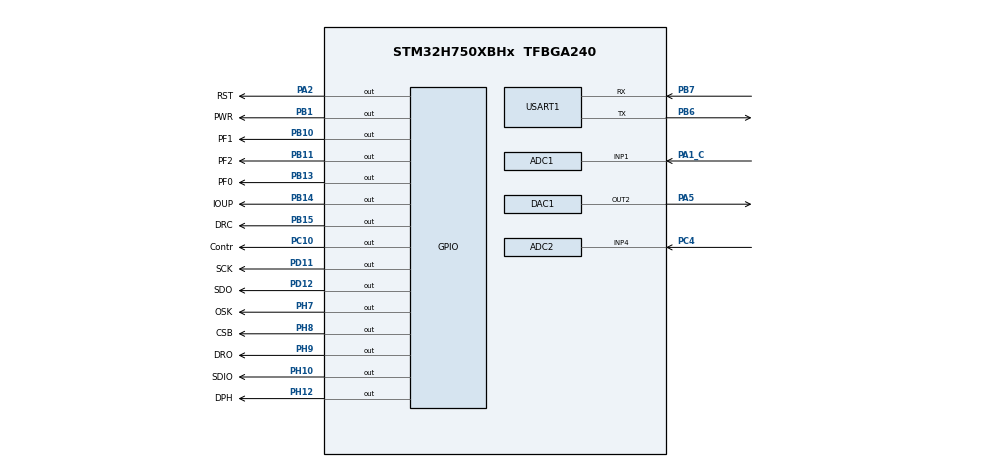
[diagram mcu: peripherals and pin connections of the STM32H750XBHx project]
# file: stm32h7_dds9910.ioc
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ADC1.Channel-3\#ChannelRegularConversion=ADC_CHANNEL_1
ADC1.ContinuousConvMode=DISABLE
ADC1.ConversionDataManagement=ADC_CONVERSIONDATA_DMA_CIRCULAR
ADC1.EOCSelection=ADC_EOC_SINGLE_CONV
ADC1.ExternalTrigConv=ADC_EXTERNALTRIG_T4_TRGO
ADC1.Mode=ADC_MODE_INDEPENDENT
ADC1.NbrOfConversionFlag=1
ADC1.OffsetNumber-3\#ChannelRegularConversion=ADC_OFFSET_NONE
ADC1.OffsetSignedSaturation-3\#ChannelRegularConversion=DISABLE
ADC1.Overrun=ADC_OVR_DATA_OVERWRITTEN
ADC1.Rank-3\#ChannelRegularConversion=1
ADC1.Resolution=ADC_RESOLUTION_12B
ADC1.SamplingTime-3\#ChannelRegularConversion=ADC_SAMPLETIME_1CYCLE_5
ADC1.master=1
ADC2.Channel-3\#ChannelRegularConversion=ADC_CHANNEL_4
ADC2.ConversionDataManagement=ADC_CONVERSIONDATA_DMA_CIRCULAR
ADC2.ExternalTrigConv=ADC_EXTERNALTRIG_T4_TRGO
ADC2.NbrOfConversionFlag=1
ADC2.OffsetNumber-3\#ChannelRegularConversion=ADC_OFFSET_NONE
ADC2.OffsetSignedSaturation-3\#ChannelRegularConversion=DISABLE
ADC2.Overrun=ADC_OVR_DATA_OVERWRITTEN
ADC2.Rank-3\#ChannelRegularConversion=1
ADC2.Resolution=ADC_RESOLUTION_12B
ADC2.SamplingTime-3\#ChannelRegularConversion=ADC_SAMPLETIME_1CYCLE_5
CORTEX_M7.default_mode_Activation=1
DAC1.DAC_Channel-DAC_OUT2=DAC_CHANNEL_2
DAC1.DAC_Trigger-DAC_OUT2=DAC_TRIGGER_T6_TRGO
Dma.ADC1.0.Direction=DMA_PERIPH_TO_MEMORY
Dma.ADC1.0.EventEnable=DISABLE
Dma.ADC1.0.FIFOMode=DMA_FIFOMODE_DISABLE
Dma.ADC1.0.Instance=DMA1_Stream0
Dma.ADC1.0.MemDataAlignment=DMA_MDATAALIGN_HALFWORD
Dma.ADC1.0.MemInc=DMA_MINC_ENABLE
Dma.ADC1.0.Mode=DMA_NORMAL
Dma.ADC1.0.PeriphDataAlignment=DMA_PDATAALIGN_HALFWORD
Dma.ADC1.0.PeriphInc=DMA_PINC_DISABLE
Dma.ADC1.0.Polarity=HAL_DMAMUX_REQ_GEN_RISING
Dma.ADC1.0.Priority=DMA_PRIORITY_LOW
Dma.ADC1.0.RequestNumber=1
Dma.ADC1.0.SignalID=NONE
Dma.ADC1.0.SyncEnable=DISABLE
Dma.ADC1.0.SyncPolarity=HAL_DMAMUX_SYNC_NO_EVENT
Dma.ADC1.0.SyncRequestNumber=1
Dma.ADC1.0.SyncSignalID=NONE
Dma.ADC2.2.Direction=DMA_PERIPH_TO_MEMORY
Dma.ADC2.2.EventEnable=DISABLE
Dma.ADC2.2.FIFOMode=DMA_FIFOMODE_DISABLE
Dma.ADC2.2.Instance=DMA1_Stream2
Dma.ADC2.2.MemDataAlignment=DMA_MDATAALIGN_HALFWORD
Dma.ADC2.2.MemInc=DMA_MINC_ENABLE
Dma.ADC2.2.Mode=DMA_NORMAL
Dma.ADC2.2.PeriphDataAlignment=DMA_PDATAALIGN_HALFWORD
Dma.ADC2.2.PeriphInc=DMA_PINC_DISABLE
Dma.ADC2.2.Polarity=HAL_DMAMUX_REQ_GEN_RISING
Dma.ADC2.2.Priority=DMA_PRIORITY_LOW
Dma.ADC2.2.RequestNumber=1
Dma.ADC2.2.SignalID=NONE
Dma.ADC2.2.SyncEnable=DISABLE
Dma.ADC2.2.SyncPolarity=HAL_DMAMUX_SYNC_NO_EVENT
Dma.ADC2.2.SyncRequestNumber=1
Dma.ADC2.2.SyncSignalID=NONE
Dma.DAC1_CH2.1.Direction=DMA_MEMORY_TO_PERIPH
Dma.DAC1_CH2.1.EventEnable=DISABLE
Dma.DAC1_CH2.1.FIFOMode=DMA_FIFOMODE_DISABLE
Dma.DAC1_CH2.1.Instance=DMA1_Stream1
Dma.DAC1_CH2.1.MemDataAlignment=DMA_MDATAALIGN_HALFWORD
Dma.DAC1_CH2.1.MemInc=DMA_MINC_ENABLE
Dma.DAC1_CH2.1.Mode=DMA_CIRCULAR
Dma.DAC1_CH2.1.PeriphDataAlignment=DMA_PDATAALIGN_HALFWORD
Dma.DAC1_CH2.1.PeriphInc=DMA_PINC_DISABLE
Dma.DAC1_CH2.1.Polarity=HAL_DMAMUX_REQ_GEN_RISING
Dma.DAC1_CH2.1.Priority=DMA_PRIORITY_VERY_HIGH
Dma.DAC1_CH2.1.RequestNumber=1
Dma.DAC1_CH2.1.SignalID=NONE
Dma.DAC1_CH2.1.SyncEnable=DISABLE
Dma.DAC1_CH2.1.SyncPolarity=HAL_DMAMUX_SYNC_NO_EVENT
Dma.DAC1_CH2.1.SyncRequestNumber=1
Dma.DAC1_CH2.1.SyncSignalID=NONE
Dma.Request0=ADC1
Dma.Request1=DAC1_CH2
Dma.Request2=ADC2
Mcu.Family=STM32H7
Mcu.Name=STM32H750XBHx
Mcu.Package=TFBGA240
NVIC.ADC_IRQn=true\:1\:0\:true\:false\:true\:true\:true\:true
NVIC.DMA1_Stream0_IRQn=true\:0\:0\:false\:false\:true\:false\:true\:true
NVIC.DMA1_Stream1_IRQn=true\:0\:0\:false\:false\:true\:false\:true\:true
NVIC.DMA1_Stream2_IRQn=true\:0\:0\:false\:false\:true\:false\:true\:true
NVIC.PriorityGroup=NVIC_PRIORITYGROUP_4
NVIC.USART1_IRQn=true\:0\:0\:false\:false\:true\:true\:true\:true
PA13\ (JTMS/SWDIO).Mode=Serial_Wire
PA13\ (JTMS/SWDIO).Signal=DEBUG_JTMS-SWDIO
PA14\ (JTCK/SWCLK).Mode=Serial_Wire
PA14\ (JTCK/SWCLK).Signal=DEBUG_JTCK-SWCLK
PA1_C.Signal=ADCx_INP1
PA2.GPIO_Label=RST
PA2.GPIO_Speed=GPIO_SPEED_FREQ_VERY_HIGH
PA2.Signal=GPIO_Output
PA4.Signal=ADCx_INP18
PA5.Signal=COMP_DAC12_group
PB1.GPIO_Label=PWR
PB1.GPIO_Speed=GPIO_SPEED_FREQ_VERY_HIGH
PB1.Signal=GPIO_Output
PB10.GPIO_Label=PF1
PB10.GPIO_Speed=GPIO_SPEED_FREQ_VERY_HIGH
PB10.Signal=GPIO_Output
PB11.GPIO_Label=PF2
PB11.GPIO_Speed=GPIO_SPEED_FREQ_VERY_HIGH
PB11.Signal=GPIO_Output
PB13.GPIO_Label=PF0
PB13.GPIO_Speed=GPIO_SPEED_FREQ_VERY_HIGH
PB13.Signal=GPIO_Output
PB14.GPIO_Label=IOUP
PB14.GPIO_Speed=GPIO_SPEED_FREQ_VERY_HIGH
PB14.Signal=GPIO_Output
PB15.GPIO_Label=DRC
PB15.GPIO_Speed=GPIO_SPEED_FREQ_VERY_HIGH
PB15.Signal=GPIO_Output
PB6.Mode=Asynchronous
PB6.Signal=USART1_TX
PB7.Mode=Asynchronous
PB7.Signal=USART1_RX
PC10.GPIO_Label=Contr
PC10.Signal=GPIO_Output
PC4.Signal=ADCx_INP4
PD11.GPIO_Label=SCK
PD11.GPIO_Speed=GPIO_SPEED_FREQ_VERY_HIGH
PD11.Signal=GPIO_Output
PD12.GPIO_Label=SDO
PD12.GPIO_Speed=GPIO_SPEED_FREQ_VERY_HIGH
PD12.Signal=GPIO_Output
PH0-OSC_IN\ (PH0).Mode=HSE-External-Oscillator
PH0-OSC_IN\ (PH0).Signal=RCC_OSC_IN
PH1-OSC_OUT\ (PH1).Mode=HSE-External-Oscillator
PH1-OSC_OUT\ (PH1).Signal=RCC_OSC_OUT
PH10.GPIO_Label=SDIO
PH10.GPIO_Speed=GPIO_SPEED_FREQ_VERY_HIGH
PH10.Signal=GPIO_Output
PH12.GPIO_Label=DPH
PH12.GPIO_Speed=GPIO_SPEED_FREQ_VERY_HIGH
PH12.Signal=GPIO_Output
PH7.GPIO_Label=OSK
PH7.GPIO_Speed=GPIO_SPEED_FREQ_VERY_HIGH
PH7.Signal=GPIO_Output
PH8.GPIO_Label=CSB
PH8.GPIO_Speed=GPIO_SPEED_FREQ_VERY_HIGH
PH8.Signal=GPIO_Output
PH9.GPIO_Label=DRO
PH9.GPIO_Speed=GPIO_SPEED_FREQ_VERY_HIGH
PH9.Signal=GPIO_Output
ProjectManager.HeapSize=0x2000
ProjectManager.StackSize=0x4000
ProjectManager.TargetToolchain=MDK-ARM V5.32
RCC.ADCFreq_Value=50000000
RCC.APB1Freq_Value=120000000
RCC.APB2Freq_Value=120000000
RCC.APB3Freq_Value=120000000
RCC.APB4Freq_Value=120000000
RCC.CortexFreq_Value=480000000
RCC.D1PPRE=RCC_APB3_DIV2
RCC.D2PPRE1=RCC_APB1_DIV2
RCC.D2PPRE2=RCC_APB2_DIV2
RCC.D3PPRE=RCC_APB4_DIV2
RCC.DIVM1=5
RCC.DIVM2=25
RCC.DIVN1=192
RCC.DIVN2=500
RCC.DIVP2=10
RCC.HCLKFreq_Value=240000000
RCC.HPRE=RCC_HCLK_DIV2
RCC.PLL2FRACN=0
RCC.PLL3FRACN=0
RCC.PLLFRACN=0
RCC.PLLSourceVirtual=RCC_PLLSOURCE_HSE
RCC.SYSCLKFreq_VALUE=480000000
RCC.SYSCLKSource=RCC_SYSCLKSOURCE_PLLCLK
RCC.USBFreq_Value=480000000
SH.ADCx_INP1.0=ADC1_INP1,IN1-Single-Ended
SH.ADCx_INP18.0=ADC1_INP18
SH.ADCx_INP4.0=ADC2_INP4,IN4-Single-Ended
SH.COMP_DAC12_group.0=DAC1_OUT2,DAC_OUT2
TIM4.AutoReloadPreload=TIM_AUTORELOAD_PRELOAD_ENABLE
TIM4.Period=240-1
TIM4.Prescaler=0
TIM4.TIM_MasterOutputTrigger=TIM_TRGO_UPDATE
TIM4.TIM_MasterSlaveMode=TIM_MASTERSLAVEMODE_DISABLE
TIM6.AutoReloadPreload=TIM_AUTORELOAD_PRELOAD_ENABLE
TIM6.Period=120-1
TIM6.TIM_MasterOutputTrigger=TIM_TRGO_UPDATE
USART1.VirtualMode-Asynchronous=VM_ASYNC
VP_MEMORYMAP_VS_MEMORYMAP.Mode=CurAppReg
VP_TIM4_VS_ClockSourceINT.Mode=Internal
VP_TIM6_VS_ClockSourceINT.Mode=Enable_Timer
board=custom

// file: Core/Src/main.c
/* USER CODE BEGIN Header */
/**
  ******************************************************************************
  * @file           : main.c
  * @brief          : Main program body
  ******************************************************************************
  * @attention
  *
  * Copyright (c) 2025 STMicroelectronics.
  * All rights reserved.
  *
  * This software is licensed under terms that can be found in the LICENSE file
  * in the root directory of this software component.
  * If no LICENSE file comes with this software, it is provided AS-IS.
  *
  ******************************************************************************
  */
/* USER CODE END Header */
#include "main.h"
#include "adc.h"
#include "dac.h"
#include "dma.h"
#include "memorymap.h"
#include "tim.h"
#include "usart.h"
#include "gpio.h"

/* USER CODE BEGIN Includes */
#include "AD9910.h"
#include "tjc_usart_hmi.h"
#include <stdio.h>
#include <stdlib.h>
#include <string.h>
#include "arm_math.h"
#include "math.h"
#include "arm_const_structs.h"
/* USER CODE END Includes */

/* USER CODE BEGIN PD */
#define FRAME_LENGTH 2
#define FFT_LEN 2048

/* USER CODE END PD */

/* USER CODE BEGIN PV */
float Fre_respon[30]=
{
0.9865,
0.9488,
0.8944,
0.8316,
0.7668,
0.7045,
0.6466,
0.5942,
0.5471,
0.5051,
0.4677,
0.4343,
0.4044,
0.3776,
0.3534,
0.3316,
0.3118,
0.2937,
0.2773,
0.2622,
0.2483,
0.2355,
0.2237,
0.2128,
0.2026,
0.1932,
0.1843,
0.1761,
0.1684,
0.1612
};

/* USER CODE END PV */

void SystemClock_Config(void);
void PeriphCommonClock_Config(void);
static void MPU_Config(void);
/* USER CODE BEGIN PFP */
static float si_10000[10000] = {
0.00000000, 0.00031419, 0.00062838, 0.00094257, 0.00125676, 0.00157095, 0.00188514, 0.00219933, 0.00251351, 0.00282770, 0.00314189, 0.00345607, 0.00377025, 0.00408443, 0.00439861, 0.00471279, 0.00502697, 0.00534114, 0.00565531, 0.00596948, 0.00628365, 0.00659781, 0.00691197, 0.00722613, 0.00754029, 0.00785444, 0.00816859, 0.00848274, 0.00879689, 0.00911103, 0.00942516, 0.00973930, 0.01005342, 0.01036755, 0.01068167, 0.01099579, 0.01130990, 0.01162401, 0.01193811, 0.01225221, 0.01256630, 0.01288039, 0.01319448, 0.01350856, 0.01382263, 0.01413670, 0.01445076, 0.01476482, 0.01507887, 0.01539291, 0.01570695, 0.01602098, 0.01633501, 0.01664903, 0.01696304, 0.01727705, 0.01759105, 0.01790504, 0.01821903, 0.01853300, 0.01884698, 0.01916094, 0.01947489, 0.01978884, 0.02010278, 0.02041672, 0.02073064, 0.02104456, 0.02135847, 0.02167237, 0.02198626, 0.02230014, 0.02261401, 0.02292788, 0.02324173, 0.02355558, 0.02386942, 0.02418324, 0.02449706, 0.02481087, 0.02512467, 0.02543846, 0.02575224, 0.02606601, 0.02637976, 0.02669351, 0.02700725, 0.02732098, 0.02763469, 0.02794840, 0.02826209, 0.02857577, 0.02888944, 0.02920310, 0.02951675, 0.02983039, 0.03014402, 0.03045763, 0.03077123, 0.03108482,
0.03139840, 0.03171196, 0.03202551, 0.03233905, 0.03265258, 0.03296609, 0.03327959, 0.03359308, 0.03390655, 0.03422001, 0.03453346, 0.03484689, 0.03516031, 0.03547372, 0.03578711, 0.03610049, 0.03641385, 0.03672720, 0.03704054, 0.03735386, 0.03766716, 0.03798045, 0.03829373, 0.03860699, 0.03892023, 0.03923346, 0.03954668, 0.03985988, 0.04017306, 0.04048623, 0.04079938, 0.04111251, 0.04142563, 0.04173873, 0.04205182, 0.04236489, 0.04267794, 0.04299098, 0.04330399, 0.04361700, 0.04392998, 0.04424295, 0.04455590, 0.04486883, 0.04518174, 0.04549464, 0.04580752, 0.04612038, 0.04643322, 0.04674604, 0.04705885, 0.04737164, 0.04768440, 0.04799715, 0.04830988, 0.04862259, 0.04893529, 0.04924796, 0.04956061, 0.04987325, 0.05018586, 0.05049845, 0.05081103, 0.05112358, 0.05143612, 0.05174863, 0.05206112, 0.05237359, 0.05268605, 0.05299848, 0.05331089, 0.05362328, 0.05393565, 0.05424799, 0.05456032, 0.05487262, 0.05518490, 0.05549716, 0.05580940, 0.05612162, 0.05643381, 0.05674598, 0.05705813, 0.05737026, 0.05768236, 0.05799445, 0.05830650, 0.05861854, 0.05893055, 0.05924254, 0.05955451, 0.05986645, 0.06017837, 0.06049026, 0.06080213, 0.06111398, 0.06142580, 0.06173760, 0.06204938, 0.06236113,
0.06267285, 0.06298455, 0.06329623, 0.06360788, 0.06391950, 0.06423110, 0.06454268, 0.06485423, 0.06516575, 0.06547725, 0.06578872, 0.06610017, 0.06641159, 0.06672298, 0.06703435, 0.06734569, 0.06765700, 0.06796829, 0.06827955, 0.06859078, 0.06890199, 0.06921317, 0.06952432, 0.06983545, 0.07014655, 0.07045761, 0.07076866, 0.07107967, 0.07139066, 0.07170161, 0.07201254, 0.07232344, 0.07263432, 0.07294516, 0.07325597, 0.07356676, 0.07387752, 0.07418824, 0.07449894, 0.07480961, 0.07512025, 0.07543086, 0.07574144, 0.07605199, 0.07636251, 0.07667300, 0.07698346, 0.07729389, 0.07760429, 0.07791465, 0.07822499, 0.07853530, 0.07884557, 0.07915582, 0.07946603, 0.07977621, 0.08008636, 0.08039648, 0.08070657, 0.08101662, 0.08132664, 0.08163663, 0.08194659, 0.08225652, 0.08256641, 0.08287627, 0.08318610, 0.08349590, 0.08380566, 0.08411539, 0.08442508, 0.08473475, 0.08504438, 0.08535397, 0.08566353, 0.08597306, 0.08628256, 0.08659202, 0.08690144, 0.08721083, 0.08752019, 0.08782951, 0.08813880, 0.08844805, 0.08875727, 0.08906646, 0.08937560, 0.08968472, 0.08999379, 0.09030284, 0.09061184, 0.09092081, 0.09122975, 0.09153865, 0.09184751, 0.09215633, 0.09246512, 0.09277388, 0.09308259, 0.09339127,
0.09369992, 0.09400852, 0.09431709, 0.09462562, 0.09493412, 0.09524257, 0.09555099, 0.09585937, 0.09616772, 0.09647602, 0.09678429, 0.09709252, 0.09740071, 0.09770886, 0.09801698, 0.09832505, 0.09863309, 0.09894108, 0.09924904, 0.09955696, 0.09986484, 0.10017268, 0.10048048, 0.10078824, 0.10109597, 0.10140365, 0.10171129, 0.10201889, 0.10232645, 0.10263397, 0.10294145, 0.10324889, 0.10355629, 0.10386365, 0.10417096, 0.10447824, 0.10478547, 0.10509267, 0.10539982, 0.10570693, 0.10601399, 0.10632102, 0.10662800, 0.10693495, 0.10724185, 0.10754870, 0.10785552, 0.10816229, 0.10846902, 0.10877571, 0.10908235, 0.10938895, 0.10969551, 0.11000203, 0.11030850, 0.11061492, 0.11092131, 0.11122765, 0.11153394, 0.11184020, 0.11214640, 0.11245257, 0.11275869, 0.11306476, 0.11337079, 0.11367678, 0.11398272, 0.11428861, 0.11459446, 0.11490027, 0.11520603, 0.11551174, 0.11581741, 0.11612303, 0.11642861, 0.11673414, 0.11703962, 0.11734506, 0.11765045, 0.11795580, 0.11826110, 0.11856635, 0.11887156, 0.11917672, 0.11948183, 0.11978689, 0.12009191, 0.12039688, 0.12070180, 0.12100668, 0.12131150, 0.12161628, 0.12192101, 0.12222570, 0.12253033, 0.12283492, 0.12313945, 0.12344394, 0.12374838, 0.12405277,
0.12435712, 0.12466141, 0.12496565, 0.12526985, 0.12557399, 0.12587809, 0.12618214, 0.12648613, 0.12679008, 0.12709397, 0.12739782, 0.12770162, 0.12800536, 0.12830906, 0.12861270, 0.12891629, 0.12921983, 0.12952333, 0.12982677, 0.13013015, 0.13043349, 0.13073678, 0.13104001, 0.13134320, 0.13164633, 0.13194940, 0.13225243, 0.13255541, 0.13285833, 0.13316120, 0.13346401, 0.13376678, 0.13406949, 0.13437215, 0.13467475, 0.13497731, 0.13527981, 0.13558225, 0.13588464, 0.13618698, 0.13648927, 0.13679150, 0.13709367, 0.13739580, 0.13769787, 0.13799988, 0.13830184, 0.13860374, 0.13890559, 0.13920739, 0.13950913, 0.13981082, 0.14011245, 0.14041402, 0.14071554, 0.14101700, 0.14131841, 0.14161976, 0.14192106, 0.14222230, 0.14252348, 0.14282461, 0.14312568, 0.14342670, 0.14372766, 0.14402856, 0.14432940, 0.14463019, 0.14493092, 0.14523160, 0.14553221, 0.14583277, 0.14613327, 0.14643371, 0.14673410, 0.14703443, 0.14733470, 0.14763491, 0.14793506, 0.14823516, 0.14853519, 0.14883517, 0.14913509, 0.14943495, 0.14973475, 0.15003449, 0.15033417, 0.15063379, 0.15093336, 0.15123286, 0.15153231, 0.15183169, 0.15213101, 0.15243028, 0.15272948, 0.15302863, 0.15332771, 0.15362673, 0.15392570, 0.15422460,
0.15452344, 0.15482222, 0.15512094, 0.15541959, 0.15571819, 0.15601672, 0.15631520, 0.15661361, 0.15691196, 0.15721024, 0.15750847, 0.15780663, 0.15810473, 0.15840277, 0.15870074, 0.15899866, 0.15929651, 0.15959430, 0.15989202, 0.16018968, 0.16048728, 0.16078481, 0.16108228, 0.16137969, 0.16167703, 0.16197431, 0.16227153, 0.16256868, 0.16286577, 0.16316279, 0.16345975, 0.16375665, 0.16405348, 0.16435024, 0.16464694, 0.16494358, 0.16524015, 0.16553665, 0.16583309, 0.16612946, 0.16642577, 0.16672201, 0.16701819, 0.16731430, 0.16761035, 0.16790632, 0.16820224, 0.16849808, 0.16879386, 0.16908957, 0.16938522, 0.16968080, 0.16997631, 0.17027175, 0.17056713, 0.17086244, 0.17115768, 0.17145286, 0.17174797, 0.17204301, 0.17233798, 0.17263288, 0.17292772, 0.17322248, 0.17351718, 0.17381181, 0.17410637, 0.17440087, 0.17469529, 0.17498965, 0.17528393, 0.17557815, 0.17587230, 0.17616637, 0.17646038, 0.17675432, 0.17704819, 0.17734199, 0.17763572, 0.17792938, 0.17822297, 0.17851648, 0.17880993, 0.17910331, 0.17939661, 0.17968985, 0.17998301, 0.18027611, 0.18056913, 0.18086208, 0.18115496, 0.18144777, 0.18174051, 0.18203317, 0.18232576, 0.18261828, 0.18291073, 0.18320311, 0.18349541, 0.18378764,
0.18407980, 0.18437189, 0.18466390, 0.18495584, 0.18524771, 0.18553951, 0.18583123, 0.18612288, 0.18641445, 0.18670595, 0.18699738, 0.18728873, 0.18758001, 0.18787122, 0.18816235, 0.18845340, 0.18874439, 0.18903529, 0.18932613, 0.18961688, 0.18990757, 0.19019818, 0.19048871, 0.19077917, 0.19106955, 0.19135986, 0.19165009, 0.19194025, 0.19223033, 0.19252033, 0.19281026, 0.19310011, 0.19338989, 0.19367959, 0.19396921, 0.19425876, 0.19454823, 0.19483762, 0.19512694, 0.19541618, 0.19570534, 0.19599442, 0.19628343, 0.19657236, 0.19686121, 0.19714999, 0.19743868, 0.19772730, 0.19801584, 0.19830430, 0.19859269, 0.19888099, 0.19916922, 0.19945737, 0.19974544, 0.20003343, 0.20032134, 0.20060917, 0.20089693, 0.20118460, 0.20147220, 0.20175971, 0.20204715, 0.20233450, 0.20262178, 0.20290897, 0.20319609, 0.20348313, 0.20377008, 0.20405696, 0.20434375, 0.20463046, 0.20491710, 0.20520365, 0.20549012, 0.20577651, 0.20606282, 0.20634904, 0.20663519, 0.20692125, 0.20720723, 0.20749314, 0.20777895, 0.20806469, 0.20835034, 0.20863592, 0.20892141, 0.20920681, 0.20949214, 0.20977738, 0.21006254, 0.21034761, 0.21063261, 0.21091752, 0.21120234, 0.21148709, 0.21177175, 0.21205632, 0.21234081, 0.21262522,
0.21290955, 0.21319379, 0.21347794, 0.21376201, 0.21404600, 0.21432990, 0.21461372, 0.21489746, 0.21518110, 0.21546467, 0.21574815, 0.21603154, 0.21631485, 0.21659807, 0.21688121, 0.21716426, 0.21744723, 0.21773011, 0.21801290, 0.21829561, 0.21857823, 0.21886076, 0.21914321, 0.21942558, 0.21970785, 0.21999004, 0.22027214, 0.22055416, 0.22083609, 0.22111793, 0.22139968, 0.22168135, 0.22196293, 0.22224442, 0.22252582, 0.22280713, 0.22308836, 0.22336950, 0.22365055, 0.22393152, 0.22421239, 0.22449318, 0.22477387, 0.22505448, 0.22533500, 0.22561543, 0.22589577, 0.22617602, 0.22645619, 0.22673626, 0.22701625, 0.22729614, 0.22757594, 0.22785566, 0.22813528, 0.22841482, 0.22869426, 0.22897362, 0.22925288, 0.22953205, 0.22981114, 0.23009013, 0.23036903, 0.23064784, 0.23092656, 0.23120519, 0.23148372, 0.23176217, 0.23204052, 0.23231878, 0.23259695, 0.23287503, 0.23315302, 0.23343091, 0.23370872, 0.23398643, 0.23426404, 0.23454157, 0.23481900, 0.23509634, 0.23537359, 0.23565074, 0.23592780, 0.23620477, 0.23648165, 0.23675843, 0.23703511, 0.23731171, 0.23758821, 0.23786461, 0.23814093, 0.23841715, 0.23869327, 0.23896930, 0.23924524, 0.23952108, 0.23979682, 0.24007248, 0.24034803, 0.24062350,
0.24089886, 0.24117414, 0.24144931, 0.24172439, 0.24199938, 0.24227427, 0.24254907, 0.24282376, 0.24309837, 0.24337288, 0.24364729, 0.24392160, 0.24419582, 0.24446994, 0.24474397, 0.24501790, 0.24529173, 0.24556547, 0.24583910, 0.24611265, 0.24638609, 0.24665944, 0.24693269, 0.24720584, 0.24747889, 0.24775185, 0.24802471, 0.24829747, 0.24857013, 0.24884270, 0.24911516, 0.24938753, 0.24965980, 0.24993197, 0.25020405, 0.25047602, 0.25074789, 0.25101967, 0.25129135, 0.25156292, 0.25183440, 0.25210578, 0.25237706, 0.25264824, 0.25291932, 0.25319030, 0.25346118, 0.25373196, 0.25400264, 0.25427322, 0.25454369, 0.25481407, 0.25508435, 0.25535453, 0.25562460, 0.25589458, 0.25616445, 0.25643423, 0.25670390, 0.25697347, 0.25724294, 0.25751230, 0.25778157, 0.25805073, 0.25831980, 0.25858876, 0.25885761, 0.25912637, 0.25939502, 0.25966357, 0.25993202, 0.26020037, 0.26046861, 0.26073675, 0.26100479, 0.26127272, 0.26154055, 0.26180828, 0.26207591, 0.26234343, 0.26261084, 0.26287816, 0.26314537, 0.26341247, 0.26367947, 0.26394637, 0.26421317, 0.26447985, 0.26474644, 0.26501292, 0.26527930, 0.26554557, 0.26581173, 0.26607779, 0.26634375, 0.26660960, 0.26687535, 0.26714099, 0.26740652, 0.26767195,
0.26793727, 0.26820249, 0.26846760, 0.26873261, 0.26899751, 0.26926230, 0.26952699, 0.26979157, 0.27005604, 0.27032041, 0.27058467, 0.27084882, 0.27111287, 0.27137681, 0.27164064, 0.27190437, 0.27216799, 0.27243150, 0.27269490, 0.27295819, 0.27322138, 0.27348446, 0.27374743, 0.27401030, 0.27427305, 0.27453570, 0.27479824, 0.27506067, 0.27532299, 0.27558520, 0.27584731, 0.27610930, 0.27637119, 0.27663296, 0.27689463, 0.27715619, 0.27741764, 0.27767898, 0.27794021, 0.27820133, 0.27846234, 0.27872324, 0.27898403, 0.27924471, 0.27950528, 0.27976574, 0.28002609, 0.28028632, 0.28054645, 0.28080647, 0.28106638, 0.28132617, 0.28158585, 0.28184543, 0.28210489, 0.28236424, 0.28262348, 0.28288260, 0.28314162, 0.28340052, 0.28365931, 0.28391799, 0.28417656, 0.28443502, 0.28469336, 0.28495159, 0.28520971, 0.28546771, 0.28572560, 0.28598338, 0.28624105, 0.28649861, 0.28675605, 0.28701337, 0.28727059, 0.28752769, 0.28778468, 0.28804155, 0.28829831, 0.28855495, 0.28881149, 0.28906790, 0.28932421, 0.28958040, 0.28983647, 0.29009243, 0.29034828, 0.29060401, 0.29085963, 0.29111513, 0.29137052, 0.29162579, 0.29188095, 0.29213599, 0.29239091, 0.29264573, 0.29290042, 0.29315500, 0.29340946, 0.29366381,
0.29391804, 0.29417216, 0.29442616, 0.29468004, 0.29493381, 0.29518746, 0.29544100, 0.29569441, 0.29594771, 0.29620090, 0.29645396, 0.29670691, 0.29695975, 0.29721246, 0.29746506, 0.29771754, 0.29796990, 0.29822215, 0.29847428, 0.29872629, 0.29897818, 0.29922995, 0.29948161, 0.29973315, 0.29998456, 0.30023587, 0.30048705, 0.30073811, 0.30098906, 0.30123988, 0.30149059, 0.30174118, 0.30199164, 0.30224199, 0.30249222, 0.30274233, 0.30299233, 0.30324220, 0.30349195, 0.30374158, 0.30399109, 0.30424048, 0.30448976, 0.30473891, 0.30498794, 0.30523685, 0.30548564, 0.30573431, 0.30598286, 0.30623129, 0.30647959, 0.30672778, 0.30697584, 0.30722379, 0.30747161, 0.30771931, 0.30796689, 0.30821435, 0.30846169, 0.30870890, 0.30895599, 0.30920296, 0.30944981, 0.30969654, 0.30994314, 0.31018962, 0.31043598, 0.31068222, 0.31092833, 0.31117432, 0.31142019, 0.31166594, 0.31191156, 0.31215706, 0.31240243, 0.31264769, 0.31289282, 0.31313782, 0.31338270, 0.31362746, 0.31387210, 0.31411661, 0.31436099, 0.31460525, 0.31484939, 0.31509341, 0.31533729, 0.31558106, 0.31582470, 0.31606821, 0.31631160, 0.31655487, 0.31679801, 0.31704103, 0.31728392, 0.31752668, 0.31776932, 0.31801184, 0.31825422, 0.31849649,
0.31873862, 0.31898064, 0.31922252, 0.31946428, 0.31970591, 0.31994742, 0.32018880, 0.32043005, 0.32067118, 0.32091218, 0.32115306, 0.32139380, 0.32163443, 0.32187492, 0.32211529, 0.32235552, 0.32259564, 0.32283562, 0.32307548, 0.32331521, 0.32355481, 0.32379428, 0.32403363, 0.32427285, 0.32451194, 0.32475090, 0.32498973, 0.32522844, 0.32546702, 0.32570547, 0.32594379, 0.32618198, 0.32642004, 0.32665797, 0.32689578, 0.32713345, 0.32737100, 0.32760842, 0.32784571, 0.32808286, 0.32831989, 0.32855679, 0.32879356, 0.32903020, 0.32926671, 0.32950309, 0.32973934, 0.32997546, 0.33021145, 0.33044731, 0.33068303, 0.33091863, 0.33115410, 0.33138944, 0.33162464, 0.33185972, 0.33209466, 0.33232947, 0.33256415, 0.33279870, 0.33303312, 0.33326741, 0.33350156, 0.33373558, 0.33396948, 0.33420324, 0.33443686, 0.33467036, 0.33490372, 0.33513695, 0.33537005, 0.33560302, 0.33583585, 0.33606856, 0.33630113, 0.33653356, 0.33676586, 0.33699803, 0.33723007, 0.33746198, 0.33769375, 0.33792538, 0.33815689, 0.33838826, 0.33861949, 0.33885060, 0.33908157, 0.33931240, 0.33954310, 0.33977367, 0.34000410, 0.34023440, 0.34046457, 0.34069460, 0.34092449, 0.34115425, 0.34138388, 0.34161337, 0.34184273, 0.34207195,
0.34230104, 0.34252999, 0.34275880, 0.34298748, 0.34321603, 0.34344444, 0.34367271, 0.34390085, 0.34412885, 0.34435672, 0.34458445, 0.34481205, 0.34503951, 0.34526683, 0.34549401, 0.34572106, 0.34594798, 0.34617475, 0.34640139, 0.34662790, 0.34685426, 0.34708049, 0.34730658, 0.34753254, 0.34775836, 0.34798404, 0.34820958, 0.34843499, 0.34866025, 0.34888538, 0.34911038, 0.34933523, 0.34955995, 0.34978453, 0.35000897, 0.35023327, 0.35045743, 0.35068146, 0.35090535, 0.35112909, 0.35135271, 0.35157618, 0.35179951, 0.35202270, 0.35224576, 0.35246867, 0.35269145, 0.35291409, 0.35313658, 0.35335894, 0.35358116, 0.35380324, 0.35402518, 0.35424698, 0.35446864, 0.35469016, 0.35491154, 0.35513278, 0.35535388, 0.35557484, 0.35579565, 0.35601633, 0.35623687, 0.35645727, 0.35667752, 0.35689764, 0.35711761, 0.35733745, 0.35755714, 0.35777669, 0.35799610, 0.35821537, 0.35843449, 0.35865348, 0.35887232, 0.35909103, 0.35930959, 0.35952800, 0.35974628, 0.35996442, 0.36018241, 0.36040026, 0.36061797, 0.36083553, 0.36105295, 0.36127023, 0.36148737, 0.36170437, 0.36192122, 0.36213793, 0.36235449, 0.36257092, 0.36278720, 0.36300333, 0.36321933, 0.36343518, 0.36365088, 0.36386645, 0.36408187, 0.36429714,
0.36451227, 0.36472726, 0.36494210, 0.36515680, 0.36537136, 0.36558577, 0.36580004, 0.36601416, 0.36622814, 0.36644197, 0.36665566, 0.36686920, 0.36708260, 0.36729585, 0.36750896, 0.36772193, 0.36793475, 0.36814742, 0.36835995, 0.36857233, 0.36878457, 0.36899666, 0.36920860, 0.36942040, 0.36963206, 0.36984356, 0.37005493, 0.37026614, 0.37047721, 0.37068813, 0.37089891, 0.37110954, 0.37132003, 0.37153036, 0.37174055, 0.37195060, 0.37216049, 0.37237024, 0.37257985, 0.37278930, 0.37299861, 0.37320777, 0.37341679, 0.37362565, 0.37383437, 0.37404294, 0.37425137, 0.37445964, 0.37466777, 0.37487575, 0.37508358, 0.37529127, 0.37549880, 0.37570619, 0.37591343, 0.37612052, 0.37632746, 0.37653426, 0.37674090, 0.37694740, 0.37715374, 0.37735994, 0.37756599, 0.37777189, 0.37797764, 0.37818325, 0.37838870, 0.37859400, 0.37879916, 0.37900416, 0.37920901, 0.37941372, 0.37961827, 0.37982268, 0.38002693, 0.38023104, 0.38043499, 0.38063880, 0.38084245, 0.38104596, 0.38124931, 0.38145251, 0.38165556, 0.38185847, 0.38206122, 0.38226382, 0.38246627, 0.38266856, 0.38287071, 0.38307271, 0.38327455, 0.38347624, 0.38367779, 0.38387918, 0.38408041, 0.38428150, 0.38448244, 0.38468322, 0.38488385, 0.38508433,
0.38528466, 0.38548483, 0.38568486, 0.38588473, 0.38608445, 0.38628401, 0.38648343, 0.38668269, 0.38688179, 0.38708075, 0.38727955, 0.38747820, 0.38767670, 0.38787504, 0.38807323, 0.38827127, 0.38846915, 0.38866688, 0.38886446, 0.38906188, 0.38925915, 0.38945627, 0.38965323, 0.38985004, 0.39004670, 0.39024320, 0.39043954, 0.39063573, 0.39083177, 0.39102766, 0.39122339, 0.39141896, 0.39161438, 0.39180965, 0.39200476, 0.39219971, 0.39239451, 0.39258916, 0.39278365, 0.39297799, 0.39317217, 0.39336619, 0.39356006, 0.39375378, 0.39394734, 0.39414074, 0.39433399, 0.39452708, 0.39472002, 0.39491280, 0.39510543, 0.39529790, 0.39549021, 0.39568237, 0.39587437, 0.39606621, 0.39625790, 0.39644943, 0.39664080, 0.39683202, 0.39702308, 0.39721399, 0.39740474, 0.39759533, 0.39778576, 0.39797604, 0.39816616, 0.39835612, 0.39854593, 0.39873557, 0.39892506, 0.39911440, 0.39930357, 0.39949259, 0.39968145, 0.39987015, 0.40005870, 0.40024708, 0.40043531, 0.40062338, 0.40081129, 0.40099905, 0.40118664, 0.40137408, 0.40156136, 0.40174848, 0.40193544, 0.40212224, 0.40230888, 0.40249537, 0.40268170, 0.40286786, 0.40305387, 0.40323972, 0.40342541, 0.40361094, 0.40379631, 0.40398152, 0.40416657, 0.40435146,
0.40453620, 0.40472077, 0.40490518, 0.40508944, 0.40527353, 0.40545746, 0.40564124, 0.40582485, 0.40600830, 0.40619159, 0.40637472, 0.40655770, 0.40674051, 0.40692316, 0.40710565, 0.40728798, 0.40747014, 0.40765215, 0.40783400, 0.40801568, 0.40819721, 0.40837857, 0.40855977, 0.40874081, 0.40892169, 0.40910241, 0.40928296, 0.40946336, 0.40964359, 0.40982366, 0.41000357, 0.41018332, 0.41036290, 0.41054233, 0.41072159, 0.41090069, 0.41107962, 0.41125840, 0.41143701, 0.41161546, 0.41179374, 0.41197187, 0.41214983, 0.41232763, 0.42500527, 0.41268274, 0.41286005, 0.41303720, 0.41321418, 0.41339100, 0.41356766, 0.41374415, 0.41392048, 0.41409665, 0.41427266, 0.41444850, 0.41462417, 0.41479969, 0.41497504, 0.41515022, 0.41532524, 0.41550010, 0.41567479, 0.41584932, 0.41602369, 0.41619789, 0.41637193, 0.41654580, 0.41671950, 0.41689305, 0.41706643, 0.41723964, 0.41741269, 0.41758557, 0.41775829, 0.41793085, 0.41810324, 0.41827546, 0.41844752, 0.41861941, 0.41879114, 0.41896271, 0.41913410, 0.41930534, 0.41947640, 0.41964730, 0.41981804, 0.41998861, 0.42015901, 0.42032925, 0.42049932, 0.42066923, 0.42083897, 0.42100854, 0.42117795, 0.42134719, 0.42151626, 0.42168517, 0.42185391, 0.42202249,
0.42219090, 0.42235914, 0.42252721, 0.42269512, 0.42286286, 0.42303044, 0.42319784, 0.42336508, 0.42353216, 0.42369906, 0.42386580, 0.42403237, 0.42419878, 0.42436501, 0.42453108, 0.42469698, 0.42486271, 0.42502828, 0.42519368, 0.42535891, 0.42552397, 0.42568886, 0.42585359, 0.42601815, 0.42618254, 0.42634676, 0.42651081, 0.42667469, 0.42683841, 0.42700196, 0.42716534, 0.42732854, 0.42749159, 0.42765446, 0.42781716, 0.42797970, 0.42814206, 0.42830426, 0.42846629, 0.42862814, 0.42878983, 0.42895135, 0.42911270, 0.42927388, 0.42943490, 0.42959574, 0.42975641, 0.42991691, 0.43007724, 0.43023741, 0.43039740, 0.43055722, 0.43071688, 0.43087636, 0.43103567, 0.43119482, 0.43135379, 0.43151259, 0.43167122, 0.43182968, 0.43198797, 0.43214609, 0.43230404, 0.43246182, 0.43261943, 0.43277687, 0.43293413, 0.43309123, 0.43324815, 0.43340491, 0.43356149, 0.43371790, 0.43387414, 0.43403021, 0.43418610, 0.43434183, 0.43449738, 0.43465277, 0.43480798, 0.43496302, 0.43511788, 0.43527258, 0.43542710, 0.43558145, 0.43573563, 0.43588964, 0.43604348, 0.43619714, 0.43635063, 0.43650395, 0.43665710, 0.43681007, 0.43696287, 0.43711550, 0.43726796, 0.43742024, 0.43757235, 0.43772429, 0.43787606, 0.43802765,
0.43817907, 0.43833032, 0.43848139, 0.43863229, 0.43878302, 0.43893357, 0.43908395, 0.43923416, 0.43938419, 0.43953405, 0.43968374, 0.43983325, 0.43998259, 0.44013176, 0.44028075, 0.44042957, 0.44057821, 0.44072668, 0.44087498, 0.44102310, 0.44117105, 0.44131882, 0.44146642, 0.44161385, 0.44176110, 0.44190817, 0.44205508, 0.44220180, 0.44234836, 0.44249473, 0.44264094, 0.44278696, 0.44293282, 0.44307850, 0.44322400, 0.44336933, 0.44351448, 0.44365946, 0.44380427, 0.44394889, 0.44409335, 0.44423762, 0.44438173, 0.44452565, 0.44466940, 0.44481298, 0.44495638, 0.44509960, 0.44524265, 0.44538552, 0.44552822, 0.44567074, 0.44581309, 0.44595526, 0.44609725, 0.44623907, 0.44638071, 0.44652217, 0.44666346, 0.44680457, 0.44694550, 0.44708626, 0.44722684, 0.44736725, 0.44750748, 0.44764753, 0.44778741, 0.44792710, 0.44806663, 0.44820597, 0.44834514, 0.44848413, 0.44862294, 0.44876158, 0.44890004, 0.44903832, 0.44917642, 0.44931435, 0.44945210, 0.44958967, 0.44972707, 0.44986429, 0.45000133, 0.45013819, 0.45027487, 0.45041138, 0.45054771, 0.45068386, 0.45081983, 0.45095563, 0.45109124, 0.45122668, 0.45136194, 0.45149702, 0.45163193, 0.45176665, 0.45190120, 0.45203557, 0.45216976, 0.45230377,
0.45243760, 0.45257126, 0.45270473, 0.45283803, 0.45297115, 0.45310409, 0.45323685, 0.45336943, 0.45350183, 0.45363405, 0.45376610, 0.45389796, 0.45402965, 0.45416116, 0.45429248, 0.45442363, 0.45455460, 0.45468539, 0.45481600, 0.45494643, 0.45507668, 0.45520675, 0.45533664, 0.45546635, 0.45559588, 0.45572523, 0.45585440, 0.45598339, 0.45611220, 0.45624084, 0.45636929, 0.45649756, 0.45662565, 0.45675356, 0.45688129, 0.45700884, 0.45713621, 0.45726339, 0.45739040, 0.45751723, 0.45764388, 0.45777034, 0.45789663, 0.45802273, 0.45814865, 0.45827440, 0.45839996, 0.45852534, 0.45865054, 0.45877556, 0.45890039, 0.45902505, 0.45914952, 0.45927382, 0.45939793, 0.45952186, 0.45964561, 0.45976918, 0.45989256, 0.46001577, 0.46013879, 0.46026163, 0.46038429, 0.46050677, 0.46062907, 0.46075118, 0.46087311, 0.46099486, 0.46111643, 0.46123782, 0.46135902, 0.46148004, 0.46160088, 0.46172154, 0.46184201, 0.46196231, 0.46208242, 0.46220235, 0.46232209, 0.46244165, 0.46256103, 0.46268023, 0.46279924, 0.46291808, 0.46303673, 0.46315519, 0.46327348, 0.46339158, 0.46350949, 0.46362723, 0.46374478, 0.46386215, 0.46397933, 0.46409634, 0.46421315, 0.46432979, 0.46444624, 0.46456251, 0.46467860, 0.46479450,
0.46491022, 0.46502575, 0.46514110, 0.46525627, 0.46537125, 0.46548605, 0.46560067, 0.46571510, 0.46582935, 0.46594341, 0.46605729, 0.46617099, 0.46628450, 0.46639783, 0.46651097, 0.46662393, 0.46673671, 0.46684930, 0.46696171, 0.46707393, 0.46718597, 0.46729782, 0.46740949, 0.46752098, 0.46763228, 0.46774339, 0.46785432, 0.46796507, 0.46807563, 0.46818600, 0.46829620, 0.46840620, 0.46851602, 0.46862566, 0.46873511, 0.46884438, 0.46895346, 0.46906236, 0.46917107, 0.46927959, 0.46938793, 0.46949609, 0.46960406, 0.46971184, 0.46981944, 0.46992685, 0.47003408, 0.47014112, 0.47024798, 0.47035465, 0.47046113, 0.47056743, 0.47067355, 0.47077947, 0.47088522, 0.47099077, 0.47109614, 0.47120133, 0.47130632, 0.47141113, 0.47151576, 0.47162020, 0.47172445, 0.47182852, 0.47193240, 0.47203609, 0.47213960, 0.47224292, 0.47234606, 0.47244901, 0.47255177, 0.47265434, 0.47275673, 0.47285893, 0.47296095, 0.47306278, 0.47316442, 0.47326587, 0.47336714, 0.47346822, 0.47356911, 0.47366982, 0.47377034, 0.47387067, 0.47397082, 0.47407078, 0.47417055, 0.47427013, 0.47436953, 0.47446874, 0.47456776, 0.47466660, 0.47476525, 0.47486371, 0.47496198, 0.47506006, 0.47515796, 0.47525567, 0.47535319, 0.47545053,
0.47554767, 0.47564463, 0.47574140, 0.47583799, 0.47593438, 0.47603059, 0.47612661, 0.47622244, 0.47631808, 0.47641354, 0.47650880, 0.47660388, 0.47669877, 0.47679348, 0.47688799, 0.47698232, 0.47707645, 0.47717040, 0.47726416, 0.47735774, 0.47745112, 0.47754432, 0.47763732, 0.47773014, 0.47782277, 0.47791521, 0.47800746, 0.47809953, 0.47819140, 0.47828309, 0.47837458, 0.47846589, 0.47855701, 0.47864794, 0.47873868, 0.47882924, 0.47891960, 0.47900977, 0.47909976, 0.47918955, 0.47927916, 0.47936858, 0.47945780, 0.47954684, 0.47963569, 0.47972435, 0.47981282, 0.47990110, 0.47998919, 0.48007710, 0.48016481, 0.48025233, 0.48033966, 0.48042681, 0.48051376, 0.48060053, 0.48068710, 0.48077348, 0.48085968, 0.48094568, 0.48103150, 0.48111712, 0.48120256, 0.48128780, 0.48137286, 0.48145772, 0.48154240, 0.48162688, 0.48171118, 0.48179528, 0.48187919, 0.48196292, 0.48204645, 0.48212979, 0.48221295, 0.48229591, 0.48237868, 0.48246126, 0.48254365, 0.48262585, 0.48270786, 0.48278968, 0.48287131, 0.48295275, 0.48303399, 0.48311505, 0.48319592, 0.48327659, 0.48335707, 0.48343737, 0.48351747, 0.48359738, 0.48367710, 0.48375663, 0.48383597, 0.48391512, 0.48399407, 0.48407284, 0.48415141, 0.48422979,
0.48430798, 0.48438599, 0.48446379, 0.48454141, 0.48461884, 0.48469607, 0.48477312, 0.48484997, 0.48492663, 0.48500310, 0.48507938, 0.48515546, 0.48523136, 0.48530706, 0.48538257, 0.48545789, 0.48553302, 0.48560796, 0.48568270, 0.48575725, 0.48583161, 0.48590578, 0.48597976, 0.48605355, 0.48612714, 0.48620054, 0.48627375, 0.48634677, 0.48641959, 0.48649223, 0.48656467, 0.48663692, 0.48670898, 0.48678084, 0.48685251, 0.48692399, 0.48699528, 0.48706638, 0.48713728, 0.48720799, 0.48727851, 0.48734884, 0.48741897, 0.48748891, 0.48755866, 0.48762822, 0.48769758, 0.48776675, 0.48783573, 0.48790452, 0.48797311, 0.48804151, 0.48810972, 0.48817774, 0.48824556, 0.48831319, 0.48838063, 0.48844787, 0.48851492, 0.48858178, 0.48864845, 0.48871492, 0.48878120, 0.48884728, 0.48891318, 0.48897888, 0.48904439, 0.48910970, 0.48917482, 0.48923975, 0.48930448, 0.48936902, 0.48943337, 0.48949753, 0.48956149, 0.48962526, 0.48968883, 0.48975222, 0.48981540, 0.48987840, 0.48994120, 0.49000381, 0.49006622, 0.49012844, 0.49019047, 0.49025231, 0.49031395, 0.49037539, 0.49043665, 0.49049771, 0.49055857, 0.49061924, 0.49067972, 0.49074001, 0.49080010, 0.49086000, 0.49091970, 0.49097921, 0.49103852, 0.49109765,
0.49115657, 0.49121531, 0.49127385, 0.49133219, 0.49139034, 0.49144830, 0.49150607, 0.49156364, 0.49162101, 0.49167819, 0.49173518, 0.49179197, 0.49184857, 0.49190498, 0.49196119, 0.49201720, 0.49207303, 0.49212865, 0.49218409, 0.49223933, 0.49229437, 0.49234922, 0.49240388, 0.49245834, 0.49251260, 0.49256668, 0.49262056, 0.49267424, 0.49272773, 0.49278102, 0.49283412, 0.49288703, 0.49293974, 0.49299225, 0.49304457, 0.49309670, 0.49314863, 0.49320037, 0.49325191, 0.49330326, 0.49335441, 0.49340537, 0.49345613, 0.49350670, 0.49355708, 0.49360726, 0.49365724, 0.49370703, 0.49375662, 0.49380602, 0.49385522, 0.49390423, 0.49395305, 0.49400167, 0.49405009, 0.49409832, 0.49414635, 0.49419419, 0.49424183, 0.49428928, 0.49433653, 0.49438359, 0.49443045, 0.49447712, 0.49452359, 0.49456987, 0.49461595, 0.49466184, 0.49470753, 0.49475303, 0.49479833, 0.49484343, 0.49488834, 0.49493305, 0.49497757, 0.49502190, 0.49506602, 0.49510996, 0.49515369, 0.49519723, 0.49524058, 0.49528373, 0.49532668, 0.49536944, 0.49541201, 0.49545437, 0.49549654, 0.49553852, 0.49558030, 0.49562189, 0.49566328, 0.49570447, 0.49574547, 0.49578627, 0.49582688, 0.49586729, 0.49590750, 0.49594752, 0.49598734, 0.49602697,
0.49606640, 0.49610564, 0.49614468, 0.49618352, 0.49622217, 0.49626062, 0.49629888, 0.49633694, 0.49637480, 0.49641247, 0.49644994, 0.49648722, 0.49652430, 0.49656118, 0.49659787, 0.49663436, 0.49667066, 0.49670675, 0.49674266, 0.49677837, 0.49681388, 0.49684919, 0.49688431, 0.49691923, 0.49695396, 0.49698849, 0.49702282, 0.49705696, 0.49709090, 0.49712465, 0.49715819, 0.49719155, 0.49722470, 0.49725766, 0.49729043, 0.49732299, 0.49735536, 0.49738754, 0.49741952, 0.49745130, 0.49748288, 0.49751427, 0.49754546, 0.49757646, 0.49760726, 0.49763786, 0.49766827, 0.49769848, 0.49772849, 0.49775831, 0.49778793, 0.49781735, 0.49784658, 0.49787561, 0.49790444, 0.49793308, 0.49796152, 0.49798976, 0.49801781, 0.49804566, 0.49807331, 0.49810077, 0.49812803, 0.49815509, 0.49818196, 0.49820863, 0.49823511, 0.49826138, 0.49828746, 0.49831335, 0.49833903, 0.49836452, 0.49838982, 0.49841491, 0.49843981, 0.49846452, 0.49848902, 0.49851333, 0.49853744, 0.49856136, 0.49858508, 0.49860860, 0.49863192, 0.49865505, 0.49867798, 0.49870072, 0.49872325, 0.49874559, 0.49876774, 0.49878968, 0.49881143, 0.49883299, 0.49885434, 0.49887550, 0.49889646, 0.49891723, 0.49893779, 0.49895816, 0.49897834, 0.49899831,
0.49901809, 0.49903768, 0.49905706, 0.49907625, 0.49909524, 0.49911403, 0.49913263, 0.49915103, 0.49916923, 0.49918724, 0.49920505, 0.49922266, 0.49924007, 0.49925729, 0.49927431, 0.49929114, 0.49930776, 0.49932419, 0.49934042, 0.49935646, 0.49937229, 0.49938793, 0.49940338, 0.49941862, 0.49943367, 0.49944852, 0.49946317, 0.49947763, 0.49949189, 0.49950595, 0.49951982, 0.49953349, 0.49954696, 0.49956023, 0.49957331, 0.49958618, 0.49959887, 0.49961135, 0.49962364, 0.49963573, 0.49964762, 0.49965931, 0.49967081, 0.49968211, 0.49969322, 0.49970412, 0.49971483, 0.49972534, 0.49973566, 0.49974577, 0.49975569, 0.49976541, 0.49977494, 0.49978427, 0.49979340, 0.49980233, 0.49981106, 0.49981960, 0.49982794, 0.49983609, 0.49984403, 0.49985178, 0.49985933, 0.49986668, 0.49987384, 0.49988080, 0.49988756, 0.49989412, 0.49990049, 0.49990666, 0.49991263, 0.49991841, 0.49992398, 0.49992936, 0.49993455, 0.49993953, 0.49994432, 0.49994891, 0.49995330, 0.49995750, 0.49996150, 0.49996530, 0.49996890, 0.49997230, 0.49997551, 0.49997852, 0.49998134, 0.49998395, 0.49998637, 0.49998859, 0.49999062, 0.49999244, 0.49999407, 0.49999550, 0.49999674, 0.49999777, 0.49999861, 0.49999925, 0.49999970, 0.49999994,
0.49999999, 0.49999985, 0.49999950, 0.49999896, 0.49999822, 0.49999728, 0.49999614, 0.49999481, 0.49999328, 0.49999155, 0.49998963, 0.49998751, 0.49998519, 0.49998267, 0.49997995, 0.49997704, 0.49997393, 0.49997063, 0.49996712, 0.49996342, 0.49995952, 0.49995542, 0.49995113, 0.49994664, 0.49994195, 0.49993706, 0.49993198, 0.49992670, 0.49992122, 0.49991554, 0.49990967, 0.49990360, 0.49989733, 0.49989087, 0.49988420, 0.49987734, 0.49987029, 0.49986303, 0.49985558, 0.49984793, 0.49984008, 0.49983204, 0.49982380, 0.49981536, 0.49980672, 0.49979789, 0.49978886, 0.49977963, 0.49977020, 0.49976058, 0.49975076, 0.49974074, 0.49973052, 0.49972011, 0.49970950, 0.49969869, 0.49968769, 0.49967649, 0.49966509, 0.49965349, 0.49964170, 0.49962971, 0.49961752, 0.49960513, 0.49959255, 0.49957977, 0.49956679, 0.49955362, 0.49954025, 0.49952668, 0.49951291, 0.49949895, 0.49948479, 0.49947043, 0.49945587, 0.49944112, 0.49942617, 0.49941102, 0.49939568, 0.49938014, 0.49936440, 0.49934846, 0.49933233, 0.49931600, 0.49929947, 0.49928275, 0.49926583, 0.49924871, 0.49923139, 0.49921388, 0.49919617, 0.49917826, 0.49916016, 0.49914186, 0.49912336, 0.49910466, 0.49908577, 0.49906668, 0.49904739, 0.49902791,
0.49900823, 0.49898835, 0.49896828, 0.49894800, 0.49892753, 0.49890687, 0.49888601, 0.49886495, 0.49884369, 0.49882223, 0.49880058, 0.49877874, 0.49875669, 0.49873445, 0.49871201, 0.49868937, 0.49866654, 0.49864351, 0.49862029, 0.49859686, 0.49857324, 0.49854943, 0.49852541, 0.49850120, 0.49847679, 0.49845219, 0.49842739, 0.49840239, 0.49837720, 0.49835180, 0.49832622, 0.49830043, 0.49827445, 0.49824827, 0.49822189, 0.49819532, 0.49816855, 0.49814159, 0.49811443, 0.49808707, 0.49805951, 0.49803176, 0.49800381, 0.49797566, 0.49794732, 0.49791878, 0.49789005, 0.49786112, 0.49783199, 0.49780266, 0.49777314, 0.49774342, 0.49771351, 0.49768340, 0.49765309, 0.49762258, 0.49759188, 0.49756098, 0.49752989, 0.49749860, 0.49746711, 0.49743543, 0.49740355, 0.49737148, 0.49733920, 0.49730673, 0.49727407, 0.49724121, 0.49720815, 0.49717490, 0.49714144, 0.49710780, 0.49707395, 0.49703992, 0.49700568, 0.49697125, 0.49693662, 0.49690180, 0.49686678, 0.49683156, 0.49679615, 0.49676054, 0.49672473, 0.49668873, 0.49665253, 0.49661614, 0.49657955, 0.49654276, 0.49650578, 0.49646860, 0.49643123, 0.49639366, 0.49635589, 0.49631793, 0.49627977, 0.49624142, 0.49620287, 0.49616412, 0.49612518, 0.49608604,
0.49604671, 0.49600718, 0.49596746, 0.49592754, 0.49588742, 0.49584711, 0.49580660, 0.49576589, 0.49572499, 0.49568390, 0.49564261, 0.49560112, 0.49555944, 0.49551756, 0.49547548, 0.49543321, 0.49539075, 0.49534809, 0.49530523, 0.49526218, 0.49521893, 0.49517549, 0.49513185, 0.49508801, 0.49504398, 0.49499976, 0.49495534, 0.49491072, 0.49486591, 0.49482090, 0.49477570, 0.49473030, 0.49468471, 0.49463892, 0.49459294, 0.49454676, 0.49450038, 0.49445381, 0.49440705, 0.49436009, 0.49431293, 0.49426558, 0.49421804, 0.49417030, 0.49412236, 0.49407423, 0.49402590, 0.49397738, 0.49392866, 0.49387975, 0.49383065, 0.49378135, 0.49373185, 0.49368216, 0.49363227, 0.49358219, 0.49353191, 0.49348144, 0.49343078, 0.49337992, 0.49332886, 0.49327761, 0.49322617, 0.49317453, 0.49312269, 0.49307066, 0.49301844, 0.49296602, 0.49291341, 0.49286060, 0.49280760, 0.49275440, 0.49270101, 0.49264742, 0.49259364, 0.49253967, 0.49248550, 0.49243113, 0.49237657, 0.49232182, 0.49226687, 0.49221173, 0.49215639, 0.49210086, 0.49204514, 0.49198922, 0.49193311, 0.49187680, 0.49182030, 0.49176360, 0.49170671, 0.49164963, 0.49159235, 0.49153487, 0.49147721, 0.49141935, 0.49136129, 0.49130304, 0.49124460, 0.49118596,
0.49112713, 0.49106811, 0.49100889, 0.49094948, 0.49088987, 0.49083007, 0.49077008, 0.49070989, 0.49064951, 0.49058893, 0.49052816, 0.49046720, 0.49040604, 0.49034469, 0.49028315, 0.49022141, 0.49015948, 0.49009736, 0.49003504, 0.48997253, 0.48990982, 0.48984693, 0.48978383, 0.48972055, 0.48965707, 0.48959340, 0.48952953, 0.48946547, 0.48940122, 0.48933678, 0.48927214, 0.48920731, 0.48914228, 0.48907707, 0.48901166, 0.48894605, 0.48888025, 0.48881426, 0.48874808, 0.48868171, 0.48861514, 0.48854837, 0.48848142, 0.48841427, 0.48834693, 0.48827940, 0.48821167, 0.48814375, 0.48807564, 0.48800734, 0.48793884, 0.48787015, 0.48780127, 0.48773219, 0.48766292, 0.48759346, 0.48752381, 0.48745397, 0.48738393, 0.48731370, 0.48724328, 0.48717266, 0.48710185, 0.48703085, 0.48695966, 0.48688828, 0.48681670, 0.48674493, 0.48667297, 0.48660082, 0.48652847, 0.48645594, 0.48638321, 0.48631028, 0.48623717, 0.48616387, 0.48609037, 0.48601668, 0.48594280, 0.48586872, 0.48579446, 0.48572000, 0.48564535, 0.48557051, 0.48549548, 0.48542026, 0.48534484, 0.48526923, 0.48519343, 0.48511744, 0.48504126, 0.48496489, 0.48488832, 0.48481157, 0.48473462, 0.48465748, 0.48458015, 0.48450263, 0.48442491, 0.48434701,
0.48426891, 0.48419063, 0.48411215, 0.48403348, 0.48395462, 0.48387557, 0.48379632, 0.48371689, 0.48363726, 0.48355745, 0.48347744, 0.48339724, 0.48331686, 0.48323628, 0.48315551, 0.48307455, 0.48299339, 0.48291205, 0.48283052, 0.48274880, 0.48266688, 0.48258478, 0.48250248, 0.48241999, 0.48233732, 0.48225445, 0.48217139, 0.48208815, 0.48200471, 0.48192108, 0.48183726, 0.48175325, 0.48166905, 0.48158466, 0.48150008, 0.48141531, 0.48133035, 0.48124520, 0.48115986, 0.48107433, 0.48098861, 0.48090270, 0.48081661, 0.48073032, 0.48064384, 0.48055717, 0.48047031, 0.48038326, 0.48029602, 0.48020859, 0.48012098, 0.48003317, 0.47994517, 0.47985699, 0.47976861, 0.47968005, 0.47959129, 0.47950235, 0.47941321, 0.47932389, 0.47923438, 0.47914468, 0.47905479, 0.47896471, 0.47887444, 0.47878398, 0.47869334, 0.47860250, 0.47851148, 0.47842026, 0.47832886, 0.47823727, 0.47814549, 0.47805352, 0.47796136, 0.47786901, 0.47777648, 0.47768376, 0.47759084, 0.47749774, 0.47740445, 0.47731097, 0.47721731, 0.47712345, 0.47702941, 0.47693518, 0.47684076, 0.47674615, 0.47665135, 0.47655637, 0.47646119, 0.47636583, 0.47627028, 0.47617455, 0.47607862, 0.47598251, 0.47588621, 0.47578972, 0.47569304, 0.47559618,
0.47549912, 0.47540188, 0.47530445, 0.47520684, 0.47510903, 0.47501104, 0.47491286, 0.47481450, 0.47471594, 0.47461720, 0.47451828, 0.47441916, 0.47431986, 0.47422037, 0.47412069, 0.47402082, 0.47392077, 0.47382053, 0.47372010, 0.47361949, 0.47351869, 0.47341770, 0.47331653, 0.47321517, 0.47311362, 0.47301188, 0.47290996, 0.47280785, 0.47270556, 0.47260308, 0.47250041, 0.47239755, 0.47229451, 0.47219128, 0.47208787, 0.47198427, 0.47188048, 0.47177651, 0.47167235, 0.47156800, 0.47146347, 0.47135875, 0.47125385, 0.47114876, 0.47104348, 0.47093802, 0.47083237, 0.47072653, 0.47062051, 0.47051431, 0.47040792, 0.47030134, 0.47019457, 0.47008762, 0.46998049, 0.46987317, 0.46976566, 0.46965797, 0.46955010, 0.46944203, 0.46933379, 0.46922535, 0.46911673, 0.46900793, 0.46889894, 0.46878977, 0.46868041, 0.46857087, 0.46846114, 0.46835122, 0.46824112, 0.46813084, 0.46802037, 0.46790972, 0.46779888, 0.46768786, 0.46757665, 0.46746526, 0.46735368, 0.46724192, 0.46712997, 0.46701784, 0.46690553, 0.46679303, 0.46668034, 0.46656748, 0.46645443, 0.46634119, 0.46622777, 0.46611416, 0.46600038, 0.46588640, 0.46577225, 0.46565791, 0.46554338, 0.46542867, 0.46531378, 0.46519871, 0.46508345, 0.46496801,
0.46485238, 0.46473657, 0.46462058, 0.46450440, 0.46438804, 0.46427149, 0.46415477, 0.46403786, 0.46392076, 0.46380349, 0.46368603, 0.46356838, 0.46345056, 0.46333255, 0.46321436, 0.46309598, 0.46297742, 0.46285868, 0.46273976, 0.46262065, 0.46500137, 0.46238189, 0.46226224, 0.46214240, 0.46202239, 0.46190218, 0.46178180, 0.46166123, 0.46154049, 0.46141955, 0.46129844, 0.46117715, 0.46105567, 0.46093401, 0.46081217, 0.46069015, 0.46056794, 0.46044555, 0.46032299, 0.46020024, 0.46007730, 0.45995419, 0.45983089, 0.45970742, 0.45958376, 0.45945992, 0.45933590, 0.45921169, 0.45908731, 0.45896274, 0.45883800, 0.45871307, 0.45858796, 0.45846267, 0.45833720, 0.45821155, 0.45808572, 0.45795970, 0.45783351, 0.45770713, 0.45758058, 0.45745384, 0.45732692, 0.45719982, 0.45707254, 0.45694508, 0.45681745, 0.45668963, 0.45656163, 0.45643344, 0.45630508, 0.45617654, 0.45604782, 0.45591892, 0.45578984, 0.45566058, 0.45553114, 0.45540152, 0.45527172, 0.45514174, 0.45501157, 0.45488123, 0.45475072, 0.45462002, 0.45448914, 0.45435808, 0.45422684, 0.45409543, 0.45396383, 0.45383205, 0.45370010, 0.45356797, 0.45343565, 0.45330316, 0.45317049, 0.45303764, 0.45290461, 0.45277140, 0.45263802, 0.45250445,
0.45237071, 0.45223679, 0.45210269, 0.45196841, 0.45183395, 0.45169931, 0.45156450, 0.45142950, 0.45129433, 0.45115898, 0.45102346, 0.45088775, 0.45075187, 0.45061580, 0.45047957, 0.45034315, 0.45020655, 0.45006978, 0.44993283, 0.44979570, 0.44965839, 0.44952091, 0.44938325, 0.44924541, 0.44910739, 0.44896920, 0.44883083, 0.44869228, 0.44855356, 0.44841466, 0.44827558, 0.44813632, 0.44799689, 0.44785728, 0.44771749, 0.44757753, 0.44743739, 0.44729707, 0.44715658, 0.44701591, 0.44687506, 0.44673404, 0.44659284, 0.44645146, 0.44630991, 0.44616818, 0.44602627, 0.44588419, 0.44574194, 0.44559950, 0.44545689, 0.44531411, 0.44517115, 0.44502801, 0.44488470, 0.44474121, 0.44459755, 0.44445371, 0.44430970, 0.44416551, 0.44402114, 0.44387660, 0.44373189, 0.44358699, 0.44344193, 0.44329669, 0.44315127, 0.44300568, 0.44285991, 0.44271397, 0.44256786, 0.44242157, 0.44227510, 0.44212846, 0.44198165, 0.44183466, 0.44168749, 0.44154016, 0.44139264, 0.44124496, 0.44109710, 0.44094906, 0.44080085, 0.44065247, 0.44050391, 0.44035518, 0.44020628, 0.44005720, 0.43990794, 0.43975852, 0.43960892, 0.43945914, 0.43930920, 0.43915908, 0.43900878, 0.43885832, 0.43870767, 0.43855686, 0.43840587, 0.43825471,
0.43810338, 0.43795187, 0.43780020, 0.43764834, 0.43749632, 0.43734412, 0.43719175, 0.43703921, 0.43688649, 0.43673361, 0.43658055, 0.43642731, 0.43627391, 0.43612033, 0.43596658, 0.43581266, 0.43565857, 0.43550430, 0.43534986, 0.43519525, 0.43504047, 0.43488552, 0.43473039, 0.43457510, 0.43441963, 0.43426399, 0.43410818, 0.43395219, 0.43379604, 0.43363971, 0.43348322, 0.43332655, 0.43316971, 0.43301270, 0.43285552, 0.43269817, 0.43254065, 0.43238295, 0.43222509, 0.43206705, 0.43190885, 0.43175047, 0.43159193, 0.43143321, 0.43127432, 0.43111527, 0.43095604, 0.43079664, 0.43063707, 0.43047733, 0.43031743, 0.43015735, 0.42999710, 0.42983668, 0.42967609, 0.42951534, 0.42935441, 0.42919332, 0.42903205, 0.42887061, 0.42870901, 0.42854724, 0.42838529, 0.42822318, 0.42806090, 0.42789845, 0.42773583, 0.42757304, 0.42741009, 0.42724696, 0.42708367, 0.42692020, 0.42675657, 0.42659277, 0.42642880, 0.42626467, 0.42610036, 0.42593589, 0.42577125, 0.42560644, 0.42544146, 0.42527631, 0.42511100, 0.42494552, 0.42477987, 0.42461405, 0.42444807, 0.42428192, 0.42411560, 0.42394911, 0.42378245, 0.42361563, 0.42344864, 0.42328149, 0.42311416, 0.42294667, 0.42277901, 0.42261119, 0.42244320, 0.42227504,
0.42210671, 0.42193822, 0.42176956, 0.42160074, 0.42143175, 0.42126259, 0.42109327, 0.42092377, 0.42075412, 0.42058430, 0.42041431, 0.42024415, 0.42007383, 0.41990334, 0.41973269, 0.41956187, 0.41939089, 0.41921974, 0.41904842, 0.41887694, 0.41870530, 0.41853349, 0.41836151, 0.41818937, 0.41801706, 0.41784459, 0.41767195, 0.41749915, 0.41732619, 0.41715305, 0.41697976, 0.41680630, 0.41663267, 0.41645888, 0.41628493, 0.41611081, 0.41593653, 0.41576208, 0.41558747, 0.41541269, 0.41523775, 0.41506265, 0.41488738, 0.41471195, 0.41453635, 0.41436060, 0.41418467, 0.41400859, 0.41383234, 0.41365593, 0.41347935, 0.41330261, 0.41312571, 0.41294864, 0.41277141, 0.41259402, 0.41241647, 0.41223875, 0.41206087, 0.41188283, 0.41170462, 0.41152625, 0.41134772, 0.41116903, 0.41099017, 0.41081116, 0.41063198, 0.41045263, 0.41027313, 0.41009346, 0.40991364, 0.40973365, 0.40955349, 0.40937318, 0.40919271, 0.40901207, 0.40883127, 0.40865031, 0.40846919, 0.40828791, 0.40810646, 0.40792486, 0.40774309, 0.40756117, 0.40737908, 0.40719683, 0.40701442, 0.40683185, 0.40664912, 0.40646623, 0.40628318, 0.40609997, 0.40591659, 0.40573306, 0.40554937, 0.40536552, 0.40518150, 0.40499733, 0.40481300, 0.40462850,
0.40444385, 0.40425904, 0.40407407, 0.40388893, 0.40370364, 0.40351819, 0.40333258, 0.40314681, 0.40296089, 0.40277480, 0.40258855, 0.40240215, 0.40221558, 0.40202886, 0.40184198, 0.40165494, 0.40146774, 0.40128038, 0.40109286, 0.40090519, 0.40071736, 0.40052937, 0.40034122, 0.40015291, 0.39996444, 0.39977582, 0.39958704, 0.39939810, 0.39920901, 0.39901975, 0.39883034, 0.39864077, 0.39845104, 0.39826116, 0.39807112, 0.39788092, 0.39769056, 0.39750005, 0.39730938, 0.39711856, 0.39692757, 0.39673643, 0.39654514, 0.39635368, 0.39616207, 0.39597031, 0.39577839, 0.39558631, 0.39539407, 0.39520168, 0.39500913, 0.39481643, 0.39462357, 0.39443056, 0.39423739, 0.39404406, 0.39385058, 0.39365694, 0.39346315, 0.39326920, 0.39307510, 0.39288084, 0.39268643, 0.39249186, 0.39229713, 0.39210225, 0.39190722, 0.39171203, 0.39151669, 0.39132119, 0.39112554, 0.39092973, 0.39073377, 0.39053766, 0.39034139, 0.39014496, 0.38994839, 0.38975166, 0.38955477, 0.38935773, 0.38916054, 0.38896319, 0.38876569, 0.38856804, 0.38837023, 0.38817227, 0.38797416, 0.38777589, 0.38757747, 0.38737890, 0.38718017, 0.38698129, 0.38678226, 0.38658307, 0.38638374, 0.38618425, 0.38598461, 0.38578481, 0.38558486, 0.38538476,
0.38518451, 0.38498411, 0.38478355, 0.38458285, 0.38438199, 0.38418098, 0.38397981, 0.38377850, 0.38357703, 0.38337542, 0.38317365, 0.38297173, 0.38276966, 0.38256743, 0.38236506, 0.38216254, 0.38195986, 0.38175703, 0.38155406, 0.38135093, 0.38114765, 0.38094422, 0.38074064, 0.38053691, 0.38033303, 0.38012900, 0.37992482, 0.37972049, 0.37951601, 0.37931138, 0.37910661, 0.37890168, 0.37869660, 0.37849137, 0.37828599, 0.37808046, 0.37787479, 0.37766896, 0.37746299, 0.37725686, 0.37705059, 0.37684417, 0.37663760, 0.37643088, 0.37622401, 0.37601699, 0.37580983, 0.37560252, 0.37539505, 0.37518744, 0.37497969, 0.37477178, 0.37456373, 0.37435552, 0.37414717, 0.37393868, 0.37373003, 0.37352124, 0.37331230, 0.37310321, 0.37289398, 0.37268459, 0.37247506, 0.37226539, 0.37205556, 0.37184559, 0.37163548, 0.37142521, 0.37121480, 0.37100424, 0.37079354, 0.37058269, 0.37037169, 0.37016055, 0.36994926, 0.36973783, 0.36952625, 0.36931452, 0.36910265, 0.36889063, 0.36867847, 0.36846616, 0.36825370, 0.36804110, 0.36782835, 0.36761546, 0.36740243, 0.36718925, 0.36697592, 0.36676245, 0.36654883, 0.36633507, 0.36612117, 0.36590712, 0.36569292, 0.36547858, 0.36526410, 0.36504947, 0.36483470, 0.36461978,
0.36440472, 0.36418952, 0.36397417, 0.36375868, 0.36354305, 0.36332727, 0.36311135, 0.36289528, 0.36267908, 0.36246272, 0.36224623, 0.36202959, 0.36181281, 0.36159589, 0.36137882, 0.36116161, 0.36094426, 0.36072677, 0.36050913, 0.36029135, 0.36007343, 0.35985537, 0.35963716, 0.35941881, 0.35920032, 0.35898169, 0.35876292, 0.35854400, 0.35832495, 0.35810575, 0.35788641, 0.35766693, 0.35744731, 0.35722755, 0.35700764, 0.35678760, 0.35656741, 0.35634709, 0.35612662, 0.35590601, 0.35568526, 0.35546437, 0.35524334, 0.35502217, 0.35480087, 0.35457942, 0.35435783, 0.35413610, 0.35391423, 0.35369222, 0.35347007, 0.35324778, 0.35302535, 0.35280278, 0.35258008, 0.35235723, 0.35213425, 0.35191112, 0.35168786, 0.35146446, 0.35124092, 0.35101724, 0.35079342, 0.35056946, 0.35034537, 0.35012114, 0.34989676, 0.34967225, 0.34944761, 0.34922282, 0.34899790, 0.34877284, 0.34854764, 0.34832230, 0.34809683, 0.34787121, 0.34764546, 0.34741958, 0.34719355, 0.34696739, 0.34674110, 0.34651466, 0.34628809, 0.34606138, 0.34583454, 0.34560756, 0.34538044, 0.34515318, 0.34492579, 0.34469827, 0.34447060, 0.34424281, 0.34401487, 0.34378680, 0.34355859, 0.34333025, 0.34310177, 0.34287316, 0.34264441, 0.34241553,
0.34218651, 0.34195736, 0.34172807, 0.34149864, 0.34126908, 0.34103939, 0.34080956, 0.34057960, 0.34034950, 0.34011927, 0.33988890, 0.33965840, 0.33942777, 0.33919700, 0.33896610, 0.33873506, 0.33850389, 0.33827259, 0.33804115, 0.33780958, 0.33757788, 0.33734604, 0.33711407, 0.33688197, 0.33664973, 0.33641736, 0.33618486, 0.33595222, 0.33571945, 0.33548655, 0.33525352, 0.33502036, 0.33478706, 0.33455363, 0.33432007, 0.33408637, 0.33385255, 0.33361859, 0.33338450, 0.33315028, 0.33291593, 0.33268144, 0.33244683, 0.33221208, 0.33197720, 0.33174219, 0.33150705, 0.33127178, 0.33103638, 0.33080085, 0.33056519, 0.33032939, 0.33009347, 0.32985742, 0.32962123, 0.32938492, 0.32914847, 0.32891190, 0.32867519, 0.32843836, 0.32820139, 0.32796430, 0.32772708, 0.32748973, 0.32725224, 0.32701463, 0.32677689, 0.32653902, 0.32630103, 0.32606290, 0.32582464, 0.32558626, 0.32534775, 0.32510910, 0.32487033, 0.32463144, 0.32439241, 0.32415326, 0.32391397, 0.32367456, 0.32343502, 0.32319536, 0.32295557, 0.32271564, 0.32247560, 0.32223542, 0.32199512, 0.32175469, 0.32151413, 0.32127345, 0.32103264, 0.32079170, 0.32055063, 0.32030944, 0.32006813, 0.31982668, 0.31958511, 0.31934342, 0.31910159, 0.31885965,
0.31861757, 0.31837537, 0.31813305, 0.31789059, 0.31764802, 0.31740531, 0.31716249, 0.31691953, 0.31667646, 0.31643325, 0.31618992, 0.31594647, 0.31570289, 0.31545919, 0.31521537, 0.31497141, 0.31472734, 0.31448314, 0.31423881, 0.31399437, 0.31374979, 0.31350510, 0.31326028, 0.31301533, 0.31277027, 0.31252508, 0.31227976, 0.31203432, 0.31178876, 0.31154308, 0.31129727, 0.31105134, 0.31080529, 0.31055912, 0.31031282, 0.31006640, 0.30981986, 0.30957319, 0.30932640, 0.30907949, 0.30883246, 0.30858531, 0.30833803, 0.30809064, 0.30784312, 0.30759548, 0.30734771, 0.30709983, 0.30685183, 0.30660370, 0.30635545, 0.30610709, 0.30585860, 0.30560999, 0.30536126, 0.30511241, 0.30486344, 0.30461435, 0.30436514, 0.30411580, 0.30386635, 0.30361678, 0.30336709, 0.30311728, 0.30286735, 0.30261729, 0.30236712, 0.30211683, 0.30186643, 0.30161590, 0.30136525, 0.30111448, 0.30086360, 0.30061259, 0.30036147, 0.30011023, 0.29985887, 0.29960739, 0.29935580, 0.29910408, 0.29885225, 0.29860030, 0.29834823, 0.29809604, 0.29784374, 0.29759132, 0.29733878, 0.29708612, 0.29683335, 0.29658045, 0.29632745, 0.29607432, 0.29582108, 0.29556772, 0.29531424, 0.29506065, 0.29480694, 0.29455312, 0.29429917, 0.29404512,
0.29379094, 0.29353665, 0.29328225, 0.29302772, 0.29277309, 0.29251833, 0.29226347, 0.29200848, 0.29175338, 0.29149817, 0.29124284, 0.29098739, 0.29073183, 0.29047616, 0.29022037, 0.28996447, 0.28970845, 0.28945232, 0.28919607, 0.28893971, 0.28868324, 0.28842665, 0.28816994, 0.28791313, 0.28765620, 0.28739915, 0.28714199, 0.28688472, 0.28662734, 0.28636984, 0.28611223, 0.28585451, 0.28559667, 0.28533872, 0.28508066, 0.28482249, 0.28456420, 0.28430580, 0.28404729, 0.28378867, 0.28352993, 0.28327108, 0.28301213, 0.28275305, 0.28249387, 0.28223458, 0.28197517, 0.28171565, 0.28145603, 0.28119629, 0.28093644, 0.28067647, 0.28041640, 0.28015622, 0.27989593, 0.27963552, 0.27937501, 0.27911438, 0.27885365, 0.27859280, 0.27833185, 0.27807078, 0.27780961, 0.27754832, 0.27728693, 0.27702542, 0.27676381, 0.27650209, 0.27624026, 0.27597832, 0.27571627, 0.27545411, 0.27519184, 0.27492947, 0.27466698, 0.27440439, 0.27414169, 0.27387888, 0.27361596, 0.27335294, 0.27308980, 0.27282656, 0.27256321, 0.27229975, 0.27203619, 0.27177252, 0.27150874, 0.27124485, 0.27098086, 0.27071676, 0.27045255, 0.27018824, 0.26992382, 0.26965929, 0.26939466, 0.26912992, 0.26886507, 0.26860012, 0.26833506, 0.26806989,
0.26780462, 0.26753925, 0.26727377, 0.26700818, 0.26674249, 0.26647669, 0.26621078, 0.26594478, 0.26567866, 0.26541244, 0.26514612, 0.26487969, 0.26461316, 0.26434652, 0.26407978, 0.26381294, 0.26354599, 0.26327893, 0.26301177, 0.26274451, 0.26247715, 0.26220968, 0.26194211, 0.26167443, 0.26140665, 0.26113877, 0.26087078, 0.26060269, 0.26033450, 0.26006621, 0.25979781, 0.25952931, 0.25926071, 0.25899200, 0.25872320, 0.25845429, 0.25818528, 0.25791616, 0.25764695, 0.25737763, 0.25710822, 0.25683870, 0.25656907, 0.25629935, 0.25602953, 0.25575960, 0.25548958, 0.25521945, 0.25494922, 0.25467890, 0.25440847, 0.25413794, 0.25386731, 0.25359658, 0.25332575, 0.25305482, 0.25278379, 0.25251266, 0.25224143, 0.25197010, 0.25169867, 0.25142715, 0.25115552, 0.25088379, 0.25061197, 0.25034004, 0.25006802, 0.24979590, 0.24952368, 0.24925136, 0.24897894, 0.24870643, 0.24843381, 0.24816110, 0.24788829, 0.24761538, 0.24734238, 0.24706927, 0.24679607, 0.24652278, 0.24624938, 0.24597589, 0.24570230, 0.24542861, 0.24515483, 0.24488094, 0.24460697, 0.24433289, 0.24405872, 0.24378446, 0.24351009, 0.24323563, 0.24296108, 0.24268643, 0.24241168, 0.24213684, 0.24186190, 0.24158686, 0.24131174, 0.24103651,
0.24076119, 0.24048578, 0.24021027, 0.23993466, 0.23965896, 0.23938317, 0.23910728, 0.23883130, 0.23855522, 0.23827905, 0.23800278, 0.23772642, 0.23744997, 0.23717342, 0.23689678, 0.23662005, 0.23634322, 0.23606630, 0.23578928, 0.23551218, 0.23523498, 0.23495768, 0.23468030, 0.23440282, 0.23412525, 0.23384758, 0.23356983, 0.23329198, 0.23301404, 0.23273601, 0.23245788, 0.23217967, 0.23190136, 0.23162296, 0.23134447, 0.23106588, 0.23078721, 0.23050845, 0.23022959, 0.22995064, 0.22967161, 0.22939248, 0.22911326, 0.22883395, 0.22855455, 0.22827506, 0.22799548, 0.22771581, 0.22743605, 0.22715620, 0.22687626, 0.22659624, 0.22631612, 0.22603591, 0.22575561, 0.22547523, 0.22519475, 0.22491419, 0.22463354, 0.22435279, 0.22407196, 0.22379105, 0.22351004, 0.22322894, 0.22294776, 0.22266649, 0.22238513, 0.22210368, 0.22182215, 0.22154052, 0.22125881, 0.22097702, 0.22069513, 0.22041316, 0.22013110, 0.21984896, 0.21956672, 0.21928441, 0.21900200, 0.21871951, 0.21843693, 0.21815426, 0.21787151, 0.21758868, 0.21730575, 0.21702274, 0.21673965, 0.21645647, 0.21617321, 0.21588985, 0.21560642, 0.21532290, 0.21503929, 0.21475560, 0.21447182, 0.21418796, 0.21390402, 0.21361999, 0.21333587, 0.21305168,
0.21276739, 0.21248303, 0.21219858, 0.21191404, 0.21162943, 0.21134472, 0.21105994, 0.21077507, 0.21049012, 0.21020509, 0.20991997, 0.20963477, 0.20934949, 0.20906412, 0.20877867, 0.20849314, 0.20820753, 0.20792183, 0.20763605, 0.20735020, 0.20706425, 0.20677823, 0.20649213, 0.20620594, 0.20591967, 0.20563332, 0.20534689, 0.20506038, 0.20477379, 0.20448712, 0.20420036, 0.20391353, 0.20362661, 0.20333962, 0.20305254, 0.20276539, 0.20247815, 0.20219084, 0.20190344, 0.20161596, 0.20132841, 0.20104077, 0.20075306, 0.20046527, 0.20017740, 0.19988944, 0.19960141, 0.19931330, 0.19902512, 0.19873685, 0.19844851, 0.19816008, 0.19787158, 0.19758300, 0.19729434, 0.19700561, 0.19671679, 0.19642790, 0.19613894, 0.19584989, 0.19556077, 0.19527157, 0.19498229, 0.19469293, 0.19440350, 0.19411399, 0.19382441, 0.19353475, 0.19324501, 0.19295520, 0.19266530, 0.19237534, 0.19208530, 0.19179518, 0.19150498, 0.19121471, 0.19092437, 0.19063395, 0.19034345, 0.19005288, 0.18976224, 0.18947151, 0.18918072, 0.18888985, 0.18859890, 0.18830788, 0.18801679, 0.18772562, 0.18743438, 0.18714306, 0.18685167, 0.18656021, 0.18626867, 0.18597706, 0.18568538, 0.18539362, 0.18510179, 0.18480988, 0.18451791, 0.18422586,
0.18393373, 0.18364154, 0.18334927, 0.18305693, 0.18276452, 0.18247203, 0.18217948, 0.18188685, 0.18159415, 0.18130137, 0.18100853, 0.18071562, 0.18042263, 0.18012957, 0.17983644, 0.17954324, 0.17924997, 0.17895663, 0.17866322, 0.17836973, 0.17807618, 0.17778256, 0.17748886, 0.17719510, 0.17690126, 0.17660736, 0.17631339, 0.17601934, 0.17572523, 0.17543105, 0.17513680, 0.17484248, 0.17454809, 0.17425363, 0.17395910, 0.17366451, 0.17336984, 0.17307511, 0.17278031, 0.17248544, 0.17219050, 0.17189550, 0.17160042, 0.17130528, 0.17101007, 0.17071480, 0.17041945, 0.17012404, 0.16982856, 0.16953302, 0.16923740, 0.16894173, 0.16864598, 0.16835017, 0.16805429, 0.16775834, 0.16746233, 0.16716625, 0.16687011, 0.16657390, 0.16627763, 0.16598128, 0.16568488, 0.16538841, 0.16509187, 0.16479527, 0.16449860, 0.16420187, 0.16390507, 0.16360821, 0.16331128, 0.16301429, 0.16271723, 0.16242011, 0.16212293, 0.16182568, 0.16152837, 0.16123100, 0.16093356, 0.16063605, 0.16033849, 0.16004086, 0.15974317, 0.15944541, 0.15914759, 0.15884971, 0.15855177, 0.15825376, 0.15795569, 0.15765756, 0.15735936, 0.15706111, 0.15676279, 0.15646441, 0.15616597, 0.15586746, 0.15556890, 0.15527027, 0.15497158, 0.15467284,
0.15437403, 0.15407515, 0.15377622, 0.15347723, 0.15317818, 0.15287906, 0.15257989, 0.15228065, 0.15198136, 0.15168201, 0.15138259, 0.15108312, 0.15078358, 0.15048399, 0.15018434, 0.14988463, 0.14958485, 0.14928502, 0.14898514, 0.14868519, 0.14838518, 0.14808512, 0.14778499, 0.14748481, 0.14718457, 0.14688427, 0.14658391, 0.14628350, 0.14598303, 0.14568250, 0.14538191, 0.14508127, 0.14478056, 0.14447980, 0.14417899, 0.14387811, 0.14357719, 0.14327620, 0.14297516, 0.14267406, 0.14237290, 0.14207169, 0.14177042, 0.14146909, 0.14116771, 0.14086628, 0.14056479, 0.14026324, 0.13996164, 0.13965998, 0.13935827, 0.13905650, 0.13875468, 0.13845280, 0.13815087, 0.13784888, 0.13754684, 0.13724474, 0.13694259, 0.13664039, 0.13633813, 0.13603582, 0.13573345, 0.13543104, 0.13512856, 0.13482604, 0.13452346, 0.13422083, 0.13391814, 0.13361540, 0.13331261, 0.13300977, 0.13270687, 0.13240393, 0.13210092, 0.13179787, 0.13149477, 0.13119161, 0.13088840, 0.13058514, 0.13028183, 0.12997847, 0.12967505, 0.12937159, 0.12906807, 0.12876450, 0.12846088, 0.12815721, 0.12785349, 0.12754972, 0.12724590, 0.12694203, 0.12663811, 0.12633414, 0.12603012, 0.12572605, 0.12542193, 0.12511776, 0.12481354, 0.12450927,
0.12420495, 0.12390058, 0.12359617, 0.12329170, 0.12298719, 0.12268263, 0.12237802, 0.12207336, 0.12176865, 0.12146390, 0.12115910, 0.12085424, 0.12054935, 0.12024440, 0.11993941, 0.11963437, 0.11932928, 0.11902414, 0.11871896, 0.11841373, 0.11810846, 0.11780313, 0.11749776, 0.11719235, 0.11688689, 0.11658138, 0.11627582, 0.11597023, 0.11566458, 0.11535889, 0.11505315, 0.11474737, 0.11444154, 0.11413567, 0.11382975, 0.11352379, 0.11321778, 0.11291173, 0.11260563, 0.11229949, 0.11199330, 0.11168707, 0.11138080, 0.11107448, 0.11076812, 0.11046172, 0.11015527, 0.10984877, 0.10954224, 0.10923566, 0.10892904, 0.10862237, 0.10831566, 0.10800891, 0.10770212, 0.10739528, 0.10708840, 0.10678148, 0.10647452, 0.10616751, 0.10586047, 0.10555338, 0.10524625, 0.10493907, 0.10463186, 0.10432461, 0.10401731, 0.10370997, 0.10340259, 0.10309518, 0.10278772, 0.10248022, 0.10217267, 0.10186509, 0.10155747, 0.10124981, 0.10094211, 0.10063437, 0.10032659, 0.10001877, 0.09971091, 0.09940301, 0.09909507, 0.09878709, 0.09847907, 0.09817102, 0.09786292, 0.09755479, 0.09724662, 0.09693841, 0.09663016, 0.09632187, 0.09601355, 0.09570519, 0.09539679, 0.09508835, 0.09477987, 0.09447136, 0.09416281, 0.09385422,
0.09354560, 0.09323694, 0.09292824, 0.09261950, 0.09231073, 0.09200193, 0.09169308, 0.09138420, 0.09107528, 0.09076633, 0.09045734, 0.09014832, 0.08983926, 0.08953017, 0.08922103, 0.08891187, 0.08860267, 0.08829343, 0.08798416, 0.08767486, 0.08736552, 0.08705614, 0.08674673, 0.08643729, 0.08612781, 0.08581830, 0.08550876, 0.08519918, 0.08488957, 0.08457992, 0.08427024, 0.08396053, 0.08365078, 0.08334100, 0.08303119, 0.08272135, 0.08241147, 0.08210156, 0.08179162, 0.08148164, 0.08117164, 0.08086160, 0.08055153, 0.08024142, 0.07993129, 0.07962112, 0.07931093, 0.07900070, 0.07869044, 0.07838015, 0.07806983, 0.07775947, 0.07744909, 0.07713868, 0.07682823, 0.07651776, 0.07620725, 0.07589672, 0.07558615, 0.07527556, 0.07496493, 0.07465428, 0.07434360, 0.07403288, 0.07372214, 0.07341137, 0.07310057, 0.07278974, 0.07247888, 0.07216800, 0.07185708, 0.07154614, 0.07123517, 0.07092417, 0.07061314, 0.07030208, 0.06999100, 0.06967989, 0.06936875, 0.06905758, 0.06874639, 0.06843517, 0.06812392, 0.06781265, 0.06750135, 0.06719002, 0.06687867, 0.06656729, 0.06625588, 0.06594445, 0.06563299, 0.06532150, 0.06500999, 0.06469846, 0.06438689, 0.06407531, 0.06376369, 0.06345206, 0.06314039, 0.06282870,
0.06251699, 0.06220525, 0.06189349, 0.06158171, 0.06126990, 0.06095806, 0.06064620, 0.06033432, 0.06002241, 0.05971048, 0.05939853, 0.05908655, 0.05877455, 0.05846252, 0.05815048, 0.05783841, 0.05752631, 0.05721420, 0.05690206, 0.05658990, 0.05627772, 0.05596551, 0.05565328, 0.05534104, 0.05502876, 0.05471647, 0.05440416, 0.05409182, 0.05377946, 0.05346709, 0.05315469, 0.05284226, 0.05252982, 0.05221736, 0.05190488, 0.05159237, 0.05127985, 0.05096731, 0.05065474, 0.05034216, 0.05002955, 0.04971693, 0.04940429, 0.04909162, 0.04877894, 0.04846624, 0.04815352, 0.04784078, 0.04752802, 0.04721524, 0.04690245, 0.04658963, 0.04627680, 0.04596395, 0.04565108, 0.04533819, 0.04502529, 0.04471236, 0.04439942, 0.04408647, 0.04377349, 0.04346050, 0.04314749, 0.04283446, 0.04252142, 0.04220835, 0.04189528, 0.04158218, 0.04126907, 0.04095595, 0.04064280, 0.04032964, 0.04001647, 0.03970328, 0.03939007, 0.03907685, 0.03876361, 0.03845036, 0.03813709, 0.03782381, 0.03751051, 0.03719720, 0.03688387, 0.03657053, 0.03625717, 0.03594380, 0.03563042, 0.03531702, 0.03500361, 0.03469018, 0.03437674, 0.03406328, 0.03374982, 0.03343634, 0.03312284, 0.03280934, 0.03249582, 0.03218228, 0.03186874, 0.03155518,
0.03124161, 0.03092803, 0.03061443, 0.03030082, 0.02998720, 0.02967357, 0.02935993, 0.02904628, 0.02873261, 0.02841893, 0.02810524, 0.02779155, 0.02747783, 0.02716411, 0.02685038, 0.02653664, 0.02622289, 0.02590912, 0.02559535, 0.02528157, 0.02496777, 0.02465397, 0.02434015, 0.02402633, 0.02372500, 0.02339866, 0.02308481, 0.02277095, 0.02245708, 0.02214320, 0.02182931, 0.02151542, 0.02120151, 0.02088760, 0.02057368, 0.02025975, 0.01994581, 0.01963187, 0.01931792, 0.01900396, 0.01868999, 0.01837602, 0.01806203, 0.01774804, 0.01743405, 0.01712005, 0.01680604, 0.01649202, 0.01617800, 0.01586397, 0.01554993, 0.01523589, 0.01492184, 0.01460779, 0.01429373, 0.01397966, 0.01366559, 0.01335152, 0.01303744, 0.01272335, 0.01240926, 0.01209516, 0.01178106, 0.01146695, 0.01115284, 0.01083873, 0.01052461, 0.01021049, 0.00989636, 0.00958223, 0.00926809, 0.00895396, 0.00863981, 0.00832567, 0.00801152, 0.00769737, 0.00738321, 0.00706905, 0.00675489, 0.00644073, 0.00612657, 0.00581240, 0.00549823, 0.00518405, 0.00486988, 0.00455570, 0.00424152, 0.00392734, 0.00361316, 0.00329898, 0.00298479, 0.00267061, 0.00235642, 0.00204223, 0.00172805, 0.00141386, 0.00109967, 0.00078548, 0.00047129, 0.00015710,
-0.00015710, -0.00047129, -0.00078548, -0.00109967, -0.00141386, -0.00172805, -0.00204223, -0.00235642, -0.00267061, -0.00298479, -0.00329898, -0.00361316, -0.00392734, -0.00424152, -0.00455570, -0.00486988, -0.00518405, -0.00549823, -0.00581240, -0.00612657, -0.00644073, -0.00675489, -0.00706905, -0.00738321, -0.00769737, -0.00801152, -0.00832567, -0.00863981, -0.00895396, -0.00926809, -0.00958223, -0.00989636, -0.01021049, -0.01052461, -0.01083873, -0.01115284, -0.01146695, -0.01178106, -0.01209516, -0.01240926, -0.01272335, -0.01303744, -0.01335152, -0.01366559, -0.01397966, -0.01429373, -0.01460779, -0.01492184, -0.01523589, -0.01554993, -0.01586397, -0.01617800, -0.01649202, -0.01680604, -0.01712005, -0.01743405, -0.01774804, -0.01806203, -0.01837602, -0.01868999, -0.01900396, -0.01931792, -0.01963187, -0.01994581, -0.02025975, -0.02057368, -0.02088760, -0.02120151, -0.02151542, -0.02182931, -0.02214320, -0.02245708, -0.02277095, -0.02308481, -0.02339866, -0.02372500, -0.02402633, -0.02434015, -0.02465397, -0.02496777, -0.02528157, -0.02559535, -0.02590912, -0.02622289, -0.02653664, -0.02685038, -0.02716411, -0.02747783, -0.02779155, -0.02810524, -0.02841893, -0.02873261, -0.02904628, -0.02935993, -0.02967357, -0.02998720, -0.03030082, -0.03061443, -0.03092803, -0.03124161,
-0.03155518, -0.03186874, -0.03218228, -0.03249582, -0.03280934, -0.03312284, -0.03343634, -0.03374982, -0.03406328, -0.03437674, -0.03469018, -0.03500361, -0.03531702, -0.03563042, -0.03594380, -0.03625717, -0.03657053, -0.03688387, -0.03719720, -0.03751051, -0.03782381, -0.03813709, -0.03845036, -0.03876361, -0.03907685, -0.03939007, -0.03970328, -0.04001647, -0.04032964, -0.04064280, -0.04095595, -0.04126907, -0.04158218, -0.04189528, -0.04220835, -0.04252142, -0.04283446, -0.04314749, -0.04346050, -0.04377349, -0.04408647, -0.04439942, -0.04471236, -0.04502529, -0.04533819, -0.04565108, -0.04596395, -0.04627680, -0.04658963, -0.04690245, -0.04721524, -0.04752802, -0.04784078, -0.04815352, -0.04846624, -0.04877894, -0.04909162, -0.04940429, -0.04971693, -0.05002955, -0.05034216, -0.05065474, -0.05096731, -0.05127985, -0.05159237, -0.05190488, -0.05221736, -0.05252982, -0.05284226, -0.05315469, -0.05346709, -0.05377946, -0.05409182, -0.05440416, -0.05471647, -0.05502876, -0.05534104, -0.05565328, -0.05596551, -0.05627772, -0.05658990, -0.05690206, -0.05721420, -0.05752631, -0.05783841, -0.05815048, -0.05846252, -0.05877455, -0.05908655, -0.05939853, -0.05971048, -0.06002241, -0.06033432, -0.06064620, -0.06095806, -0.06126990, -0.06158171, -0.06189349, -0.06220525, -0.06251699,
-0.06282870, -0.06314039, -0.06345206, -0.06376369, -0.06407531, -0.06438689, -0.06469846, -0.06500999, -0.06532150, -0.06563299, -0.06594445, -0.06625588, -0.06656729, -0.06687867, -0.06719002, -0.06750135, -0.06781265, -0.06812392, -0.06843517, -0.06874639, -0.06905758, -0.06936875, -0.06967989, -0.06999100, -0.07030208, -0.07061314, -0.07092417, -0.07123517, -0.07154614, -0.07185708, -0.07216800, -0.07247888, -0.07278974, -0.07310057, -0.07341137, -0.07372214, -0.07403288, -0.07434360, -0.07465428, -0.07496493, -0.07527556, -0.07558615, -0.07589672, -0.07620725, -0.07651776, -0.07682823, -0.07713868, -0.07744909, -0.07775947, -0.07806983, -0.07838015, -0.07869044, -0.07900070, -0.07931093, -0.07962112, -0.07993129, -0.08024142, -0.08055153, -0.08086160, -0.08117164, -0.08148164, -0.08179162, -0.08210156, -0.08241147, -0.08272135, -0.08303119, -0.08334100, -0.08365078, -0.08396053, -0.08427024, -0.08457992, -0.08488957, -0.08519918, -0.08550876, -0.08581830, -0.08612781, -0.08643729, -0.08674673, -0.08705614, -0.08736552, -0.08767486, -0.08798416, -0.08829343, -0.08860267, -0.08891187, -0.08922103, -0.08953017, -0.08983926, -0.09014832, -0.09045734, -0.09076633, -0.09107528, -0.09138420, -0.09169308, -0.09200193, -0.09231073, -0.09261950, -0.09292824, -0.09323694, -0.09354560,
-0.09385422, -0.09416281, -0.09447136, -0.09477987, -0.09508835, -0.09539679, -0.09570519, -0.09601355, -0.09632187, -0.09663016, -0.09693841, -0.09724662, -0.09755479, -0.09786292, -0.09817102, -0.09847907, -0.09878709, -0.09909507, -0.09940301, -0.09971091, -0.10001877, -0.10032659, -0.10063437, -0.10094211, -0.10124981, -0.10155747, -0.10186509, -0.10217267, -0.10248022, -0.10278772, -0.10309518, -0.10340259, -0.10370997, -0.10401731, -0.10432461, -0.10463186, -0.10493907, -0.10524625, -0.10555338, -0.10586047, -0.10616751, -0.10647452, -0.10678148, -0.10708840, -0.10739528, -0.10770212, -0.10800891, -0.10831566, -0.10862237, -0.10892904, -0.10923566, -0.10954224, -0.10984877, -0.11015527, -0.11046172, -0.11076812, -0.11107448, -0.11138080, -0.11168707, -0.11199330, -0.11229949, -0.11260563, -0.11291173, -0.11321778, -0.11352379, -0.11382975, -0.11413567, -0.11444154, -0.11474737, -0.11505315, -0.11535889, -0.11566458, -0.11597023, -0.11627582, -0.11658138, -0.11688689, -0.11719235, -0.11749776, -0.11780313, -0.11810846, -0.11841373, -0.11871896, -0.11902414, -0.11932928, -0.11963437, -0.11993941, -0.12024440, -0.12054935, -0.12085424, -0.12115910, -0.12146390, -0.12176865, -0.12207336, -0.12237802, -0.12268263, -0.12298719, -0.12329170, -0.12359617, -0.12390058, -0.12420495,
-0.12450927, -0.12481354, -0.12511776, -0.12542193, -0.12572605, -0.12603012, -0.12633414, -0.12663811, -0.12694203, -0.12724590, -0.12754972, -0.12785349, -0.12815721, -0.12846088, -0.12876450, -0.12906807, -0.12937159, -0.12967505, -0.12997847, -0.13028183, -0.13058514, -0.13088840, -0.13119161, -0.13149477, -0.13179787, -0.13210092, -0.13240393, -0.13270687, -0.13300977, -0.13331261, -0.13361540, -0.13391814, -0.13422083, -0.13452346, -0.13482604, -0.13512856, -0.13543104, -0.13573345, -0.13603582, -0.13633813, -0.13664039, -0.13694259, -0.13724474, -0.13754684, -0.13784888, -0.13815087, -0.13845280, -0.13875468, -0.13905650, -0.13935827, -0.13965998, -0.13996164, -0.14026324, -0.14056479, -0.14086628, -0.14116771, -0.14146909, -0.14177042, -0.14207169, -0.14237290, -0.14267406, -0.14297516, -0.14327620, -0.14357719, -0.14387811, -0.14417899, -0.14447980, -0.14478056, -0.14508127, -0.14538191, -0.14568250, -0.14598303, -0.14628350, -0.14658391, -0.14688427, -0.14718457, -0.14748481, -0.14778499, -0.14808512, -0.14838518, -0.14868519, -0.14898514, -0.14928502, -0.14958485, -0.14988463, -0.15018434, -0.15048399, -0.15078358, -0.15108312, -0.15138259, -0.15168201, -0.15198136, -0.15228065, -0.15257989, -0.15287906, -0.15317818, -0.15347723, -0.15377622, -0.15407515, -0.15437403,
-0.15467284, -0.15497158, -0.15527027, -0.15556890, -0.15586746, -0.15616597, -0.15646441, -0.15676279, -0.15706111, -0.15735936, -0.15765756, -0.15795569, -0.15825376, -0.15855177, -0.15884971, -0.15914759, -0.15944541, -0.15974317, -0.16004086, -0.16033849, -0.16063605, -0.16093356, -0.16123100, -0.16152837, -0.16182568, -0.16212293, -0.16242011, -0.16271723, -0.16301429, -0.16331128, -0.16360821, -0.16390507, -0.16420187, -0.16449860, -0.16479527, -0.16509187, -0.16538841, -0.16568488, -0.16598128, -0.16627763, -0.16657390, -0.16687011, -0.16716625, -0.16746233, -0.16775834, -0.16805429, -0.16835017, -0.16864598, -0.16894173, -0.16923740, -0.16953302, -0.16982856, -0.17012404, -0.17041945, -0.17071480, -0.17101007, -0.17130528, -0.17160042, -0.17189550, -0.17219050, -0.17248544, -0.17278031, -0.17307511, -0.17336984, -0.17366451, -0.17395910, -0.17425363, -0.17454809, -0.17484248, -0.17513680, -0.17543105, -0.17572523, -0.17601934, -0.17631339, -0.17660736, -0.17690126, -0.17719510, -0.17748886, -0.17778256, -0.17807618, -0.17836973, -0.17866322, -0.17895663, -0.17924997, -0.17954324, -0.17983644, -0.18012957, -0.18042263, -0.18071562, -0.18100853, -0.18130137, -0.18159415, -0.18188685, -0.18217948, -0.18247203, -0.18276452, -0.18305693, -0.18334927, -0.18364154, -0.18393373,
-0.18422586, -0.18451791, -0.18480988, -0.18510179, -0.18539362, -0.18568538, -0.18597706, -0.18626867, -0.18656021, -0.18685167, -0.18714306, -0.18743438, -0.18772562, -0.18801679, -0.18830788, -0.18859890, -0.18888985, -0.18918072, -0.18947151, -0.18976224, -0.19005288, -0.19034345, -0.19063395, -0.19092437, -0.19121471, -0.19150498, -0.19179518, -0.19208530, -0.19237534, -0.19266530, -0.19295520, -0.19324501, -0.19353475, -0.19382441, -0.19411399, -0.19440350, -0.19469293, -0.19498229, -0.19527157, -0.19556077, -0.19584989, -0.19613894, -0.19642790, -0.19671679, -0.19700561, -0.19729434, -0.19758300, -0.19787158, -0.19816008, -0.19844851, -0.19873685, -0.19902512, -0.19931330, -0.19960141, -0.19988944, -0.20017740, -0.20046527, -0.20075306, -0.20104077, -0.20132841, -0.20161596, -0.20190344, -0.20219084, -0.20247815, -0.20276539, -0.20305254, -0.20333962, -0.20362661, -0.20391353, -0.20420036, -0.20448712, -0.20477379, -0.20506038, -0.20534689, -0.20563332, -0.20591967, -0.20620594, -0.20649213, -0.20677823, -0.20706425, -0.20735020, -0.20763605, -0.20792183, -0.20820753, -0.20849314, -0.20877867, -0.20906412, -0.20934949, -0.20963477, -0.20991997, -0.21020509, -0.21049012, -0.21077507, -0.21105994, -0.21134472, -0.21162943, -0.21191404, -0.21219858, -0.21248303, -0.21276739,
-0.21305168, -0.21333587, -0.21361999, -0.21390402, -0.21418796, -0.21447182, -0.21475560, -0.21503929, -0.21532290, -0.21560642, -0.21588985, -0.21617321, -0.21645647, -0.21673965, -0.21702274, -0.21730575, -0.21758868, -0.21787151, -0.21815426, -0.21843693, -0.21871951, -0.21900200, -0.21928441, -0.21956672, -0.21984896, -0.22013110, -0.22041316, -0.22069513, -0.22097702, -0.22125881, -0.22154052, -0.22182215, -0.22210368, -0.22238513, -0.22266649, -0.22294776, -0.22322894, -0.22351004, -0.22379105, -0.22407196, -0.22435279, -0.22463354, -0.22491419, -0.22519475, -0.22547523, -0.22575561, -0.22603591, -0.22631612, -0.22659624, -0.22687626, -0.22715620, -0.22743605, -0.22771581, -0.22799548, -0.22827506, -0.22855455, -0.22883395, -0.22911326, -0.22939248, -0.22967161, -0.22995064, -0.23022959, -0.23050845, -0.23078721, -0.23106588, -0.23134447, -0.23162296, -0.23190136, -0.23217967, -0.23245788, -0.23273601, -0.23301404, -0.23329198, -0.23356983, -0.23384758, -0.23412525, -0.23440282, -0.23468030, -0.23495768, -0.23523498, -0.23551218, -0.23578928, -0.23606630, -0.23634322, -0.23662005, -0.23689678, -0.23717342, -0.23744997, -0.23772642, -0.23800278, -0.23827905, -0.23855522, -0.23883130, -0.23910728, -0.23938317, -0.23965896, -0.23993466, -0.24021027, -0.24048578, -0.24076119,
-0.24103651, -0.24131174, -0.24158686, -0.24186190, -0.24213684, -0.24241168, -0.24268643, -0.24296108, -0.24323563, -0.24351009, -0.24378446, -0.24405872, -0.24433289, -0.24460697, -0.24488094, -0.24515483, -0.24542861, -0.24570230, -0.24597589, -0.24624938, -0.24652278, -0.24679607, -0.24706927, -0.24734238, -0.24761538, -0.24788829, -0.24816110, -0.24843381, -0.24870643, -0.24897894, -0.24925136, -0.24952368, -0.24979590, -0.25006802, -0.25034004, -0.25061197, -0.25088379, -0.25115552, -0.25142715, -0.25169867, -0.25197010, -0.25224143, -0.25251266, -0.25278379, -0.25305482, -0.25332575, -0.25359658, -0.25386731, -0.25413794, -0.25440847, -0.25467890, -0.25494922, -0.25521945, -0.25548958, -0.25575960, -0.25602953, -0.25629935, -0.25656907, -0.25683870, -0.25710822, -0.25737763, -0.25764695, -0.25791616, -0.25818528, -0.25845429, -0.25872320, -0.25899200, -0.25926071, -0.25952931, -0.25979781, -0.26006621, -0.26033450, -0.26060269, -0.26087078, -0.26113877, -0.26140665, -0.26167443, -0.26194211, -0.26220968, -0.26247715, -0.26274451, -0.26301177, -0.26327893, -0.26354599, -0.26381294, -0.26407978, -0.26434652, -0.26461316, -0.26487969, -0.26514612, -0.26541244, -0.26567866, -0.26594478, -0.26621078, -0.26647669, -0.26674249, -0.26700818, -0.26727377, -0.26753925, -0.26780462,
-0.26806989, -0.26833506, -0.26860012, -0.26886507, -0.26912992, -0.26939466, -0.26965929, -0.26992382, -0.27018824, -0.27045255, -0.27071676, -0.27098086, -0.27124485, -0.27150874, -0.27177252, -0.27203619, -0.27229975, -0.27256321, -0.27282656, -0.27308980, -0.27335294, -0.27361596, -0.27387888, -0.27414169, -0.27440439, -0.27466698, -0.27492947, -0.27519184, -0.27545411, -0.27571627, -0.27597832, -0.27624026, -0.27650209, -0.27676381, -0.27702542, -0.27728693, -0.27754832, -0.27780961, -0.27807078, -0.27833185, -0.27859280, -0.27885365, -0.27911438, -0.27937501, -0.27963552, -0.27989593, -0.28015622, -0.28041640, -0.28067647, -0.28093644, -0.28119629, -0.28145603, -0.28171565, -0.28197517, -0.28223458, -0.28249387, -0.28275305, -0.28301213, -0.28327108, -0.28352993, -0.28378867, -0.28404729, -0.28430580, -0.28456420, -0.28482249, -0.28508066, -0.28533872, -0.28559667, -0.28585451, -0.28611223, -0.28636984, -0.28662734, -0.28688472, -0.28714199, -0.28739915, -0.28765620, -0.28791313, -0.28816994, -0.28842665, -0.28868324, -0.28893971, -0.28919607, -0.28945232, -0.28970845, -0.28996447, -0.29022037, -0.29047616, -0.29073183, -0.29098739, -0.29124284, -0.29149817, -0.29175338, -0.29200848, -0.29226347, -0.29251833, -0.29277309, -0.29302772, -0.29328225, -0.29353665, -0.29379094,
-0.29404512, -0.29429917, -0.29455312, -0.29480694, -0.29506065, -0.29531424, -0.29556772, -0.29582108, -0.29607432, -0.29632745, -0.29658045, -0.29683335, -0.29708612, -0.29733878, -0.29759132, -0.29784374, -0.29809604, -0.29834823, -0.29860030, -0.29885225, -0.29910408, -0.29935580, -0.29960739, -0.29985887, -0.30011023, -0.30036147, -0.30061259, -0.30086360, -0.30111448, -0.30136525, -0.30161590, -0.30186643, -0.30211683, -0.30236712, -0.30261729, -0.30286735, -0.30311728, -0.30336709, -0.30361678, -0.30386635, -0.30411580, -0.30436514, -0.30461435, -0.30486344, -0.30511241, -0.30536126, -0.30560999, -0.30585860, -0.30610709, -0.30635545, -0.30660370, -0.30685183, -0.30709983, -0.30734771, -0.30759548, -0.30784312, -0.30809064, -0.30833803, -0.30858531, -0.30883246, -0.30907949, -0.30932640, -0.30957319, -0.30981986, -0.31006640, -0.31031282, -0.31055912, -0.31080529, -0.31105134, -0.31129727, -0.31154308, -0.31178876, -0.31203432, -0.31227976, -0.31252508, -0.31277027, -0.31301533, -0.31326028, -0.31350510, -0.31374979, -0.31399437, -0.31423881, -0.31448314, -0.31472734, -0.31497141, -0.31521537, -0.31545919, -0.31570289, -0.31594647, -0.31618992, -0.31643325, -0.31667646, -0.31691953, -0.31716249, -0.31740531, -0.31764802, -0.31789059, -0.31813305, -0.31837537, -0.31861757,
-0.31885965, -0.31910159, -0.31934342, -0.31958511, -0.31982668, -0.32006813, -0.32030944, -0.32055063, -0.32079170, -0.32103264, -0.32127345, -0.32151413, -0.32175469, -0.32199512, -0.32223542, -0.32247560, -0.32271564, -0.32295557, -0.32319536, -0.32343502, -0.32367456, -0.32391397, -0.32415326, -0.32439241, -0.32463144, -0.32487033, -0.32510910, -0.32534775, -0.32558626, -0.32582464, -0.32606290, -0.32630103, -0.32653902, -0.32677689, -0.32701463, -0.32725224, -0.32748973, -0.32772708, -0.32796430, -0.32820139, -0.32843836, -0.32867519, -0.32891190, -0.32914847, -0.32938492, -0.32962123, -0.32985742, -0.33009347, -0.33032939, -0.33056519, -0.33080085, -0.33103638, -0.33127178, -0.33150705, -0.33174219, -0.33197720, -0.33221208, -0.33244683, -0.33268144, -0.33291593, -0.33315028, -0.33338450, -0.33361859, -0.33385255, -0.33408637, -0.33432007, -0.33455363, -0.33478706, -0.33502036, -0.33525352, -0.33548655, -0.33571945, -0.33595222, -0.33618486, -0.33641736, -0.33664973, -0.33688197, -0.33711407, -0.33734604, -0.33757788, -0.33780958, -0.33804115, -0.33827259, -0.33850389, -0.33873506, -0.33896610, -0.33919700, -0.33942777, -0.33965840, -0.33988890, -0.34011927, -0.34034950, -0.34057960, -0.34080956, -0.34103939, -0.34126908, -0.34149864, -0.34172807, -0.34195736, -0.34218651,
-0.34241553, -0.34264441, -0.34287316, -0.34310177, -0.34333025, -0.34355859, -0.34378680, -0.34401487, -0.34424281, -0.34447060, -0.34469827, -0.34492579, -0.34515318, -0.34538044, -0.34560756, -0.34583454, -0.34606138, -0.34628809, -0.34651466, -0.34674110, -0.34696739, -0.34719355, -0.34741958, -0.34764546, -0.34787121, -0.34809683, -0.34832230, -0.34854764, -0.34877284, -0.34899790, -0.34922282, -0.34944761, -0.34967225, -0.34989676, -0.35012114, -0.35034537, -0.35056946, -0.35079342, -0.35101724, -0.35124092, -0.35146446, -0.35168786, -0.35191112, -0.35213425, -0.35235723, -0.35258008, -0.35280278, -0.35302535, -0.35324778, -0.35347007, -0.35369222, -0.35391423, -0.35413610, -0.35435783, -0.35457942, -0.35480087, -0.35502217, -0.35524334, -0.35546437, -0.35568526, -0.35590601, -0.35612662, -0.35634709, -0.35656741, -0.35678760, -0.35700764, -0.35722755, -0.35744731, -0.35766693, -0.35788641, -0.35810575, -0.35832495, -0.35854400, -0.35876292, -0.35898169, -0.35920032, -0.35941881, -0.35963716, -0.35985537, -0.36007343, -0.36029135, -0.36050913, -0.36072677, -0.36094426, -0.36116161, -0.36137882, -0.36159589, -0.36181281, -0.36202959, -0.36224623, -0.36246272, -0.36267908, -0.36289528, -0.36311135, -0.36332727, -0.36354305, -0.36375868, -0.36397417, -0.36418952, -0.36440472,
-0.36461978, -0.36483470, -0.36504947, -0.36526410, -0.36547858, -0.36569292, -0.36590712, -0.36612117, -0.36633507, -0.36654883, -0.36676245, -0.36697592, -0.36718925, -0.36740243, -0.36761546, -0.36782835, -0.36804110, -0.36825370, -0.36846616, -0.36867847, -0.36889063, -0.36910265, -0.36931452, -0.36952625, -0.36973783, -0.36994926, -0.37016055, -0.37037169, -0.37058269, -0.37079354, -0.37100424, -0.37121480, -0.37142521, -0.37163548, -0.37184559, -0.37205556, -0.37226539, -0.37247506, -0.37268459, -0.37289398, -0.37310321, -0.37331230, -0.37352124, -0.37373003, -0.37393868, -0.37414717, -0.37435552, -0.37456373, -0.37477178, -0.37497969, -0.37518744, -0.37539505, -0.37560252, -0.37580983, -0.37601699, -0.37622401, -0.37643088, -0.37663760, -0.37684417, -0.37705059, -0.37725686, -0.37746299, -0.37766896, -0.37787479, -0.37808046, -0.37828599, -0.37849137, -0.37869660, -0.37890168, -0.37910661, -0.37931138, -0.37951601, -0.37972049, -0.37992482, -0.38012900, -0.38033303, -0.38053691, -0.38074064, -0.38094422, -0.38114765, -0.38135093, -0.38155406, -0.38175703, -0.38195986, -0.38216254, -0.38236506, -0.38256743, -0.38276966, -0.38297173, -0.38317365, -0.38337542, -0.38357703, -0.38377850, -0.38397981, -0.38418098, -0.38438199, -0.38458285, -0.38478355, -0.38498411, -0.38518451,
-0.38538476, -0.38558486, -0.38578481, -0.38598461, -0.38618425, -0.38638374, -0.38658307, -0.38678226, -0.38698129, -0.38718017, -0.38737890, -0.38757747, -0.38777589, -0.38797416, -0.38817227, -0.38837023, -0.38856804, -0.38876569, -0.38896319, -0.38916054, -0.38935773, -0.38955477, -0.38975166, -0.38994839, -0.39014496, -0.39034139, -0.39053766, -0.39073377, -0.39092973, -0.39112554, -0.39132119, -0.39151669, -0.39171203, -0.39190722, -0.39210225, -0.39229713, -0.39249186, -0.39268643, -0.39288084, -0.39307510, -0.39326920, -0.39346315, -0.39365694, -0.39385058, -0.39404406, -0.39423739, -0.39443056, -0.39462357, -0.39481643, -0.39500913, -0.39520168, -0.39539407, -0.39558631, -0.39577839, -0.39597031, -0.39616207, -0.39635368, -0.39654514, -0.39673643, -0.39692757, -0.39711856, -0.39730938, -0.39750005, -0.39769056, -0.39788092, -0.39807112, -0.39826116, -0.39845104, -0.39864077, -0.39883034, -0.39901975, -0.39920901, -0.39939810, -0.39958704, -0.39977582, -0.39996444, -0.40015291, -0.40034122, -0.40052937, -0.40071736, -0.40090519, -0.40109286, -0.40128038, -0.40146774, -0.40165494, -0.40184198, -0.40202886, -0.40221558, -0.40240215, -0.40258855, -0.40277480, -0.40296089, -0.40314681, -0.40333258, -0.40351819, -0.40370364, -0.40388893, -0.40407407, -0.40425904, -0.40444385,
-0.40462850, -0.40481300, -0.40499733, -0.40518150, -0.40536552, -0.40554937, -0.40573306, -0.40591659, -0.40609997, -0.40628318, -0.40646623, -0.40664912, -0.40683185, -0.40701442, -0.40719683, -0.40737908, -0.40756117, -0.40774309, -0.40792486, -0.40810646, -0.40828791, -0.40846919, -0.40865031, -0.40883127, -0.40901207, -0.40919271, -0.40937318, -0.40955349, -0.40973365, -0.40991364, -0.41009346, -0.41027313, -0.41045263, -0.41063198, -0.41081116, -0.41099017, -0.41116903, -0.41134772, -0.41152625, -0.41170462, -0.41188283, -0.41206087, -0.41223875, -0.41241647, -0.41259402, -0.41277141, -0.41294864, -0.41312571, -0.41330261, -0.41347935, -0.41365593, -0.41383234, -0.41400859, -0.41418467, -0.41436060, -0.41453635, -0.41471195, -0.41488738, -0.41506265, -0.41523775, -0.41541269, -0.41558747, -0.41576208, -0.41593653, -0.41611081, -0.41628493, -0.41645888, -0.41663267, -0.41680630, -0.41697976, -0.41715305, -0.41732619, -0.41749915, -0.41767195, -0.41784459, -0.41801706, -0.41818937, -0.41836151, -0.41853349, -0.41870530, -0.41887694, -0.41904842, -0.41921974, -0.41939089, -0.41956187, -0.41973269, -0.41990334, -0.42007383, -0.42024415, -0.42041431, -0.42058430, -0.42075412, -0.42092377, -0.42109327, -0.42126259, -0.42143175, -0.42160074, -0.42176956, -0.42193822, -0.42210671,
-0.42227504, -0.42244320, -0.42261119, -0.42277901, -0.42294667, -0.42311416, -0.42328149, -0.42344864, -0.42361563, -0.42378245, -0.42394911, -0.42411560, -0.42428192, -0.42444807, -0.42461405, -0.42477987, -0.42494552, -0.42511100, -0.42527631, -0.42544146, -0.42560644, -0.42577125, -0.42593589, -0.42610036, -0.42626467, -0.42642880, -0.42659277, -0.42675657, -0.42692020, -0.42708367, -0.42724696, -0.42741009, -0.42757304, -0.42773583, -0.42789845, -0.42806090, -0.42822318, -0.42838529, -0.42854724, -0.42870901, -0.42887061, -0.42903205, -0.42919332, -0.42935441, -0.42951534, -0.42967609, -0.42983668, -0.42999710, -0.43015735, -0.43031743, -0.43047733, -0.43063707, -0.43079664, -0.43095604, -0.43111527, -0.43127432, -0.43143321, -0.43159193, -0.43175047, -0.43190885, -0.43206705, -0.43222509, -0.43238295, -0.43254065, -0.43269817, -0.43285552, -0.43301270, -0.43316971, -0.43332655, -0.43348322, -0.43363971, -0.43379604, -0.43395219, -0.43410818, -0.43426399, -0.43441963, -0.43457510, -0.43473039, -0.43488552, -0.43504047, -0.43519525, -0.43534986, -0.43550430, -0.43565857, -0.43581266, -0.43596658, -0.43612033, -0.43627391, -0.43642731, -0.43658055, -0.43673361, -0.43688649, -0.43703921, -0.43719175, -0.43734412, -0.43749632, -0.43764834, -0.43780020, -0.43795187, -0.43810338,
-0.43825471, -0.43840587, -0.43855686, -0.43870767, -0.43885832, -0.43900878, -0.43915908, -0.43930920, -0.43945914, -0.43960892, -0.43975852, -0.43990794, -0.44005720, -0.44020628, -0.44035518, -0.44050391, -0.44065247, -0.44080085, -0.44094906, -0.44109710, -0.44124496, -0.44139264, -0.44154016, -0.44168749, -0.44183466, -0.44198165, -0.44212846, -0.44227510, -0.44242157, -0.44256786, -0.44271397, -0.44285991, -0.44300568, -0.44315127, -0.44329669, -0.44344193, -0.44358699, -0.44373189, -0.44387660, -0.44402114, -0.44416551, -0.44430970, -0.44445371, -0.44459755, -0.44474121, -0.44488470, -0.44502801, -0.44517115, -0.44531411, -0.44545689, -0.44559950, -0.44574194, -0.44588419, -0.44602627, -0.44616818, -0.44630991, -0.44645146, -0.44659284, -0.44673404, -0.44687506, -0.44701591, -0.44715658, -0.44729707, -0.44743739, -0.44757753, -0.44771749, -0.44785728, -0.44799689, -0.44813632, -0.44827558, -0.44841466, -0.44855356, -0.44869228, -0.44883083, -0.44896920, -0.44910739, -0.44924541, -0.44938325, -0.44952091, -0.44965839, -0.44979570, -0.44993283, -0.45006978, -0.45020655, -0.45034315, -0.45047957, -0.45061580, -0.45075187, -0.45088775, -0.45102346, -0.45115898, -0.45129433, -0.45142950, -0.45156450, -0.45169931, -0.45183395, -0.45196841, -0.45210269, -0.45223679, -0.45237071,
-0.45250445, -0.45263802, -0.45277140, -0.45290461, -0.45303764, -0.45317049, -0.45330316, -0.45343565, -0.45356797, -0.45370010, -0.45383205, -0.45396383, -0.45409543, -0.45422684, -0.45435808, -0.45448914, -0.45462002, -0.45475072, -0.45488123, -0.45501157, -0.45514174, -0.45527172, -0.45540152, -0.45553114, -0.45566058, -0.45578984, -0.45591892, -0.45604782, -0.45617654, -0.45630508, -0.45643344, -0.45656163, -0.45668963, -0.45681745, -0.45694508, -0.45707254, -0.45719982, -0.45732692, -0.45745384, -0.45758058, -0.45770713, -0.45783351, -0.45795970, -0.45808572, -0.45821155, -0.45833720, -0.45846267, -0.45858796, -0.45871307, -0.45883800, -0.45896274, -0.45908731, -0.45921169, -0.45933590, -0.45945992, -0.45958376, -0.45970742, -0.45983089, -0.45995419, -0.46007730, -0.46020024, -0.46032299, -0.46044555, -0.46056794, -0.46069015, -0.46081217, -0.46093401, -0.46105567, -0.46117715, -0.46129844, -0.46141955, -0.46154049, -0.46166123, -0.46178180, -0.46190218, -0.46202239, -0.46214240, -0.46226224, -0.46238189, -0.46500137, -0.46262065, -0.46273976, -0.46285868, -0.46297742, -0.46309598, -0.46321436, -0.46333255, -0.46345056, -0.46356838, -0.46368603, -0.46380349, -0.46392076, -0.46403786, -0.46415477, -0.46427149, -0.46438804, -0.46450440, -0.46462058, -0.46473657, -0.46485238,
-0.46496801, -0.46508345, -0.46519871, -0.46531378, -0.46542867, -0.46554338, -0.46565791, -0.46577225, -0.46588640, -0.46600038, -0.46611416, -0.46622777, -0.46634119, -0.46645443, -0.46656748, -0.46668034, -0.46679303, -0.46690553, -0.46701784, -0.46712997, -0.46724192, -0.46735368, -0.46746526, -0.46757665, -0.46768786, -0.46779888, -0.46790972, -0.46802037, -0.46813084, -0.46824112, -0.46835122, -0.46846114, -0.46857087, -0.46868041, -0.46878977, -0.46889894, -0.46900793, -0.46911673, -0.46922535, -0.46933379, -0.46944203, -0.46955010, -0.46965797, -0.46976566, -0.46987317, -0.46998049, -0.47008762, -0.47019457, -0.47030134, -0.47040792, -0.47051431, -0.47062051, -0.47072653, -0.47083237, -0.47093802, -0.47104348, -0.47114876, -0.47125385, -0.47135875, -0.47146347, -0.47156800, -0.47167235, -0.47177651, -0.47188048, -0.47198427, -0.47208787, -0.47219128, -0.47229451, -0.47239755, -0.47250041, -0.47260308, -0.47270556, -0.47280785, -0.47290996, -0.47301188, -0.47311362, -0.47321517, -0.47331653, -0.47341770, -0.47351869, -0.47361949, -0.47372010, -0.47382053, -0.47392077, -0.47402082, -0.47412069, -0.47422037, -0.47431986, -0.47441916, -0.47451828, -0.47461720, -0.47471594, -0.47481450, -0.47491286, -0.47501104, -0.47510903, -0.47520684, -0.47530445, -0.47540188, -0.47549912,
-0.47559618, -0.47569304, -0.47578972, -0.47588621, -0.47598251, -0.47607862, -0.47617455, -0.47627028, -0.47636583, -0.47646119, -0.47655637, -0.47665135, -0.47674615, -0.47684076, -0.47693518, -0.47702941, -0.47712345, -0.47721731, -0.47731097, -0.47740445, -0.47749774, -0.47759084, -0.47768376, -0.47777648, -0.47786901, -0.47796136, -0.47805352, -0.47814549, -0.47823727, -0.47832886, -0.47842026, -0.47851148, -0.47860250, -0.47869334, -0.47878398, -0.47887444, -0.47896471, -0.47905479, -0.47914468, -0.47923438, -0.47932389, -0.47941321, -0.47950235, -0.47959129, -0.47968005, -0.47976861, -0.47985699, -0.47994517, -0.48003317, -0.48012098, -0.48020859, -0.48029602, -0.48038326, -0.48047031, -0.48055717, -0.48064384, -0.48073032, -0.48081661, -0.48090270, -0.48098861, -0.48107433, -0.48115986, -0.48124520, -0.48133035, -0.48141531, -0.48150008, -0.48158466, -0.48166905, -0.48175325, -0.48183726, -0.48192108, -0.48200471, -0.48208815, -0.48217139, -0.48225445, -0.48233732, -0.48241999, -0.48250248, -0.48258478, -0.48266688, -0.48274880, -0.48283052, -0.48291205, -0.48299339, -0.48307455, -0.48315551, -0.48323628, -0.48331686, -0.48339724, -0.48347744, -0.48355745, -0.48363726, -0.48371689, -0.48379632, -0.48387557, -0.48395462, -0.48403348, -0.48411215, -0.48419063, -0.48426891,
-0.48434701, -0.48442491, -0.48450263, -0.48458015, -0.48465748, -0.48473462, -0.48481157, -0.48488832, -0.48496489, -0.48504126, -0.48511744, -0.48519343, -0.48526923, -0.48534484, -0.48542026, -0.48549548, -0.48557051, -0.48564535, -0.48572000, -0.48579446, -0.48586872, -0.48594280, -0.48601668, -0.48609037, -0.48616387, -0.48623717, -0.48631028, -0.48638321, -0.48645594, -0.48652847, -0.48660082, -0.48667297, -0.48674493, -0.48681670, -0.48688828, -0.48695966, -0.48703085, -0.48710185, -0.48717266, -0.48724328, -0.48731370, -0.48738393, -0.48745397, -0.48752381, -0.48759346, -0.48766292, -0.48773219, -0.48780127, -0.48787015, -0.48793884, -0.48800734, -0.48807564, -0.48814375, -0.48821167, -0.48827940, -0.48834693, -0.48841427, -0.48848142, -0.48854837, -0.48861514, -0.48868171, -0.48874808, -0.48881426, -0.48888025, -0.48894605, -0.48901166, -0.48907707, -0.48914228, -0.48920731, -0.48927214, -0.48933678, -0.48940122, -0.48946547, -0.48952953, -0.48959340, -0.48965707, -0.48972055, -0.48978383, -0.48984693, -0.48990982, -0.48997253, -0.49003504, -0.49009736, -0.49015948, -0.49022141, -0.49028315, -0.49034469, -0.49040604, -0.49046720, -0.49052816, -0.49058893, -0.49064951, -0.49070989, -0.49077008, -0.49083007, -0.49088987, -0.49094948, -0.49100889, -0.49106811, -0.49112713,
-0.49118596, -0.49124460, -0.49130304, -0.49136129, -0.49141935, -0.49147721, -0.49153487, -0.49159235, -0.49164963, -0.49170671, -0.49176360, -0.49182030, -0.49187680, -0.49193311, -0.49198922, -0.49204514, -0.49210086, -0.49215639, -0.49221173, -0.49226687, -0.49232182, -0.49237657, -0.49243113, -0.49248550, -0.49253967, -0.49259364, -0.49264742, -0.49270101, -0.49275440, -0.49280760, -0.49286060, -0.49291341, -0.49296602, -0.49301844, -0.49307066, -0.49312269, -0.49317453, -0.49322617, -0.49327761, -0.49332886, -0.49337992, -0.49343078, -0.49348144, -0.49353191, -0.49358219, -0.49363227, -0.49368216, -0.49373185, -0.49378135, -0.49383065, -0.49387975, -0.49392866, -0.49397738, -0.49402590, -0.49407423, -0.49412236, -0.49417030, -0.49421804, -0.49426558, -0.49431293, -0.49436009, -0.49440705, -0.49445381, -0.49450038, -0.49454676, -0.49459294, -0.49463892, -0.49468471, -0.49473030, -0.49477570, -0.49482090, -0.49486591, -0.49491072, -0.49495534, -0.49499976, -0.49504398, -0.49508801, -0.49513185, -0.49517549, -0.49521893, -0.49526218, -0.49530523, -0.49534809, -0.49539075, -0.49543321, -0.49547548, -0.49551756, -0.49555944, -0.49560112, -0.49564261, -0.49568390, -0.49572499, -0.49576589, -0.49580660, -0.49584711, -0.49588742, -0.49592754, -0.49596746, -0.49600718, -0.49604671,
-0.49608604, -0.49612518, -0.49616412, -0.49620287, -0.49624142, -0.49627977, -0.49631793, -0.49635589, -0.49639366, -0.49643123, -0.49646860, -0.49650578, -0.49654276, -0.49657955, -0.49661614, -0.49665253, -0.49668873, -0.49672473, -0.49676054, -0.49679615, -0.49683156, -0.49686678, -0.49690180, -0.49693662, -0.49697125, -0.49700568, -0.49703992, -0.49707395, -0.49710780, -0.49714144, -0.49717490, -0.49720815, -0.49724121, -0.49727407, -0.49730673, -0.49733920, -0.49737148, -0.49740355, -0.49743543, -0.49746711, -0.49749860, -0.49752989, -0.49756098, -0.49759188, -0.49762258, -0.49765309, -0.49768340, -0.49771351, -0.49774342, -0.49777314, -0.49780266, -0.49783199, -0.49786112, -0.49789005, -0.49791878, -0.49794732, -0.49797566, -0.49800381, -0.49803176, -0.49805951, -0.49808707, -0.49811443, -0.49814159, -0.49816855, -0.49819532, -0.49822189, -0.49824827, -0.49827445, -0.49830043, -0.49832622, -0.49835180, -0.49837720, -0.49840239, -0.49842739, -0.49845219, -0.49847679, -0.49850120, -0.49852541, -0.49854943, -0.49857324, -0.49859686, -0.49862029, -0.49864351, -0.49866654, -0.49868937, -0.49871201, -0.49873445, -0.49875669, -0.49877874, -0.49880058, -0.49882223, -0.49884369, -0.49886495, -0.49888601, -0.49890687, -0.49892753, -0.49894800, -0.49896828, -0.49898835, -0.49900823,
-0.49902791, -0.49904739, -0.49906668, -0.49908577, -0.49910466, -0.49912336, -0.49914186, -0.49916016, -0.49917826, -0.49919617, -0.49921388, -0.49923139, -0.49924871, -0.49926583, -0.49928275, -0.49929947, -0.49931600, -0.49933233, -0.49934846, -0.49936440, -0.49938014, -0.49939568, -0.49941102, -0.49942617, -0.49944112, -0.49945587, -0.49947043, -0.49948479, -0.49949895, -0.49951291, -0.49952668, -0.49954025, -0.49955362, -0.49956679, -0.49957977, -0.49959255, -0.49960513, -0.49961752, -0.49962971, -0.49964170, -0.49965349, -0.49966509, -0.49967649, -0.49968769, -0.49969869, -0.49970950, -0.49972011, -0.49973052, -0.49974074, -0.49975076, -0.49976058, -0.49977020, -0.49977963, -0.49978886, -0.49979789, -0.49980672, -0.49981536, -0.49982380, -0.49983204, -0.49984008, -0.49984793, -0.49985558, -0.49986303, -0.49987029, -0.49987734, -0.49988420, -0.49989087, -0.49989733, -0.49990360, -0.49990967, -0.49991554, -0.49992122, -0.49992670, -0.49993198, -0.49993706, -0.49994195, -0.49994664, -0.49995113, -0.49995542, -0.49995952, -0.49996342, -0.49996712, -0.49997063, -0.49997393, -0.49997704, -0.49997995, -0.49998267, -0.49998519, -0.49998751, -0.49998963, -0.49999155, -0.49999328, -0.49999481, -0.49999614, -0.49999728, -0.49999822, -0.49999896, -0.49999950, -0.49999985, -0.49999999,
-0.49999994, -0.49999970, -0.49999925, -0.49999861, -0.49999777, -0.49999674, -0.49999550, -0.49999407, -0.49999244, -0.49999062, -0.49998859, -0.49998637, -0.49998395, -0.49998134, -0.49997852, -0.49997551, -0.49997230, -0.49996890, -0.49996530, -0.49996150, -0.49995750, -0.49995330, -0.49994891, -0.49994432, -0.49993953, -0.49993455, -0.49992936, -0.49992398, -0.49991841, -0.49991263, -0.49990666, -0.49990049, -0.49989412, -0.49988756, -0.49988080, -0.49987384, -0.49986668, -0.49985933, -0.49985178, -0.49984403, -0.49983609, -0.49982794, -0.49981960, -0.49981106, -0.49980233, -0.49979340, -0.49978427, -0.49977494, -0.49976541, -0.49975569, -0.49974577, -0.49973566, -0.49972534, -0.49971483, -0.49970412, -0.49969322, -0.49968211, -0.49967081, -0.49965931, -0.49964762, -0.49963573, -0.49962364, -0.49961135, -0.49959887, -0.49958618, -0.49957331, -0.49956023, -0.49954696, -0.49953349, -0.49951982, -0.49950595, -0.49949189, -0.49947763, -0.49946317, -0.49944852, -0.49943367, -0.49941862, -0.49940338, -0.49938793, -0.49937229, -0.49935646, -0.49934042, -0.49932419, -0.49930776, -0.49929114, -0.49927431, -0.49925729, -0.49924007, -0.49922266, -0.49920505, -0.49918724, -0.49916923, -0.49915103, -0.49913263, -0.49911403, -0.49909524, -0.49907625, -0.49905706, -0.49903768, -0.49901809,
-0.49899831, -0.49897834, -0.49895816, -0.49893779, -0.49891723, -0.49889646, -0.49887550, -0.49885434, -0.49883299, -0.49881143, -0.49878968, -0.49876774, -0.49874559, -0.49872325, -0.49870072, -0.49867798, -0.49865505, -0.49863192, -0.49860860, -0.49858508, -0.49856136, -0.49853744, -0.49851333, -0.49848902, -0.49846452, -0.49843981, -0.49841491, -0.49838982, -0.49836452, -0.49833903, -0.49831335, -0.49828746, -0.49826138, -0.49823511, -0.49820863, -0.49818196, -0.49815509, -0.49812803, -0.49810077, -0.49807331, -0.49804566, -0.49801781, -0.49798976, -0.49796152, -0.49793308, -0.49790444, -0.49787561, -0.49784658, -0.49781735, -0.49778793, -0.49775831, -0.49772849, -0.49769848, -0.49766827, -0.49763786, -0.49760726, -0.49757646, -0.49754546, -0.49751427, -0.49748288, -0.49745130, -0.49741952, -0.49738754, -0.49735536, -0.49732299, -0.49729043, -0.49725766, -0.49722470, -0.49719155, -0.49715819, -0.49712465, -0.49709090, -0.49705696, -0.49702282, -0.49698849, -0.49695396, -0.49691923, -0.49688431, -0.49684919, -0.49681388, -0.49677837, -0.49674266, -0.49670675, -0.49667066, -0.49663436, -0.49659787, -0.49656118, -0.49652430, -0.49648722, -0.49644994, -0.49641247, -0.49637480, -0.49633694, -0.49629888, -0.49626062, -0.49622217, -0.49618352, -0.49614468, -0.49610564, -0.49606640,
-0.49602697, -0.49598734, -0.49594752, -0.49590750, -0.49586729, -0.49582688, -0.49578627, -0.49574547, -0.49570447, -0.49566328, -0.49562189, -0.49558030, -0.49553852, -0.49549654, -0.49545437, -0.49541201, -0.49536944, -0.49532668, -0.49528373, -0.49524058, -0.49519723, -0.49515369, -0.49510996, -0.49506602, -0.49502190, -0.49497757, -0.49493305, -0.49488834, -0.49484343, -0.49479833, -0.49475303, -0.49470753, -0.49466184, -0.49461595, -0.49456987, -0.49452359, -0.49447712, -0.49443045, -0.49438359, -0.49433653, -0.49428928, -0.49424183, -0.49419419, -0.49414635, -0.49409832, -0.49405009, -0.49400167, -0.49395305, -0.49390423, -0.49385522, -0.49380602, -0.49375662, -0.49370703, -0.49365724, -0.49360726, -0.49355708, -0.49350670, -0.49345613, -0.49340537, -0.49335441, -0.49330326, -0.49325191, -0.49320037, -0.49314863, -0.49309670, -0.49304457, -0.49299225, -0.49293974, -0.49288703, -0.49283412, -0.49278102, -0.49272773, -0.49267424, -0.49262056, -0.49256668, -0.49251260, -0.49245834, -0.49240388, -0.49234922, -0.49229437, -0.49223933, -0.49218409, -0.49212865, -0.49207303, -0.49201720, -0.49196119, -0.49190498, -0.49184857, -0.49179197, -0.49173518, -0.49167819, -0.49162101, -0.49156364, -0.49150607, -0.49144830, -0.49139034, -0.49133219, -0.49127385, -0.49121531, -0.49115657,
-0.49109765, -0.49103852, -0.49097921, -0.49091970, -0.49086000, -0.49080010, -0.49074001, -0.49067972, -0.49061924, -0.49055857, -0.49049771, -0.49043665, -0.49037539, -0.49031395, -0.49025231, -0.49019047, -0.49012844, -0.49006622, -0.49000381, -0.48994120, -0.48987840, -0.48981540, -0.48975222, -0.48968883, -0.48962526, -0.48956149, -0.48949753, -0.48943337, -0.48936902, -0.48930448, -0.48923975, -0.48917482, -0.48910970, -0.48904439, -0.48897888, -0.48891318, -0.48884728, -0.48878120, -0.48871492, -0.48864845, -0.48858178, -0.48851492, -0.48844787, -0.48838063, -0.48831319, -0.48824556, -0.48817774, -0.48810972, -0.48804151, -0.48797311, -0.48790452, -0.48783573, -0.48776675, -0.48769758, -0.48762822, -0.48755866, -0.48748891, -0.48741897, -0.48734884, -0.48727851, -0.48720799, -0.48713728, -0.48706638, -0.48699528, -0.48692399, -0.48685251, -0.48678084, -0.48670898, -0.48663692, -0.48656467, -0.48649223, -0.48641959, -0.48634677, -0.48627375, -0.48620054, -0.48612714, -0.48605355, -0.48597976, -0.48590578, -0.48583161, -0.48575725, -0.48568270, -0.48560796, -0.48553302, -0.48545789, -0.48538257, -0.48530706, -0.48523136, -0.48515546, -0.48507938, -0.48500310, -0.48492663, -0.48484997, -0.48477312, -0.48469607, -0.48461884, -0.48454141, -0.48446379, -0.48438599, -0.48430798,
-0.48422979, -0.48415141, -0.48407284, -0.48399407, -0.48391512, -0.48383597, -0.48375663, -0.48367710, -0.48359738, -0.48351747, -0.48343737, -0.48335707, -0.48327659, -0.48319592, -0.48311505, -0.48303399, -0.48295275, -0.48287131, -0.48278968, -0.48270786, -0.48262585, -0.48254365, -0.48246126, -0.48237868, -0.48229591, -0.48221295, -0.48212979, -0.48204645, -0.48196292, -0.48187919, -0.48179528, -0.48171118, -0.48162688, -0.48154240, -0.48145772, -0.48137286, -0.48128780, -0.48120256, -0.48111712, -0.48103150, -0.48094568, -0.48085968, -0.48077348, -0.48068710, -0.48060053, -0.48051376, -0.48042681, -0.48033966, -0.48025233, -0.48016481, -0.48007710, -0.47998919, -0.47990110, -0.47981282, -0.47972435, -0.47963569, -0.47954684, -0.47945780, -0.47936858, -0.47927916, -0.47918955, -0.47909976, -0.47900977, -0.47891960, -0.47882924, -0.47873868, -0.47864794, -0.47855701, -0.47846589, -0.47837458, -0.47828309, -0.47819140, -0.47809953, -0.47800746, -0.47791521, -0.47782277, -0.47773014, -0.47763732, -0.47754432, -0.47745112, -0.47735774, -0.47726416, -0.47717040, -0.47707645, -0.47698232, -0.47688799, -0.47679348, -0.47669877, -0.47660388, -0.47650880, -0.47641354, -0.47631808, -0.47622244, -0.47612661, -0.47603059, -0.47593438, -0.47583799, -0.47574140, -0.47564463, -0.47554767,
-0.47545053, -0.47535319, -0.47525567, -0.47515796, -0.47506006, -0.47496198, -0.47486371, -0.47476525, -0.47466660, -0.47456776, -0.47446874, -0.47436953, -0.47427013, -0.47417055, -0.47407078, -0.47397082, -0.47387067, -0.47377034, -0.47366982, -0.47356911, -0.47346822, -0.47336714, -0.47326587, -0.47316442, -0.47306278, -0.47296095, -0.47285893, -0.47275673, -0.47265434, -0.47255177, -0.47244901, -0.47234606, -0.47224292, -0.47213960, -0.47203609, -0.47193240, -0.47182852, -0.47172445, -0.47162020, -0.47151576, -0.47141113, -0.47130632, -0.47120133, -0.47109614, -0.47099077, -0.47088522, -0.47077947, -0.47067355, -0.47056743, -0.47046113, -0.47035465, -0.47024798, -0.47014112, -0.47003408, -0.46992685, -0.46981944, -0.46971184, -0.46960406, -0.46949609, -0.46938793, -0.46927959, -0.46917107, -0.46906236, -0.46895346, -0.46884438, -0.46873511, -0.46862566, -0.46851602, -0.46840620, -0.46829620, -0.46818600, -0.46807563, -0.46796507, -0.46785432, -0.46774339, -0.46763228, -0.46752098, -0.46740949, -0.46729782, -0.46718597, -0.46707393, -0.46696171, -0.46684930, -0.46673671, -0.46662393, -0.46651097, -0.46639783, -0.46628450, -0.46617099, -0.46605729, -0.46594341, -0.46582935, -0.46571510, -0.46560067, -0.46548605, -0.46537125, -0.46525627, -0.46514110, -0.46502575, -0.46491022,
-0.46479450, -0.46467860, -0.46456251, -0.46444624, -0.46432979, -0.46421315, -0.46409634, -0.46397933, -0.46386215, -0.46374478, -0.46362723, -0.46350949, -0.46339158, -0.46327348, -0.46315519, -0.46303673, -0.46291808, -0.46279924, -0.46268023, -0.46256103, -0.46244165, -0.46232209, -0.46220235, -0.46208242, -0.46196231, -0.46184201, -0.46172154, -0.46160088, -0.46148004, -0.46135902, -0.46123782, -0.46111643, -0.46099486, -0.46087311, -0.46075118, -0.46062907, -0.46050677, -0.46038429, -0.46026163, -0.46013879, -0.46001577, -0.45989256, -0.45976918, -0.45964561, -0.45952186, -0.45939793, -0.45927382, -0.45914952, -0.45902505, -0.45890039, -0.45877556, -0.45865054, -0.45852534, -0.45839996, -0.45827440, -0.45814865, -0.45802273, -0.45789663, -0.45777034, -0.45764388, -0.45751723, -0.45739040, -0.45726339, -0.45713621, -0.45700884, -0.45688129, -0.45675356, -0.45662565, -0.45649756, -0.45636929, -0.45624084, -0.45611220, -0.45598339, -0.45585440, -0.45572523, -0.45559588, -0.45546635, -0.45533664, -0.45520675, -0.45507668, -0.45494643, -0.45481600, -0.45468539, -0.45455460, -0.45442363, -0.45429248, -0.45416116, -0.45402965, -0.45389796, -0.45376610, -0.45363405, -0.45350183, -0.45336943, -0.45323685, -0.45310409, -0.45297115, -0.45283803, -0.45270473, -0.45257126, -0.45243760,
-0.45230377, -0.45216976, -0.45203557, -0.45190120, -0.45176665, -0.45163193, -0.45149702, -0.45136194, -0.45122668, -0.45109124, -0.45095563, -0.45081983, -0.45068386, -0.45054771, -0.45041138, -0.45027487, -0.45013819, -0.45000133, -0.44986429, -0.44972707, -0.44958967, -0.44945210, -0.44931435, -0.44917642, -0.44903832, -0.44890004, -0.44876158, -0.44862294, -0.44848413, -0.44834514, -0.44820597, -0.44806663, -0.44792710, -0.44778741, -0.44764753, -0.44750748, -0.44736725, -0.44722684, -0.44708626, -0.44694550, -0.44680457, -0.44666346, -0.44652217, -0.44638071, -0.44623907, -0.44609725, -0.44595526, -0.44581309, -0.44567074, -0.44552822, -0.44538552, -0.44524265, -0.44509960, -0.44495638, -0.44481298, -0.44466940, -0.44452565, -0.44438173, -0.44423762, -0.44409335, -0.44394889, -0.44380427, -0.44365946, -0.44351448, -0.44336933, -0.44322400, -0.44307850, -0.44293282, -0.44278696, -0.44264094, -0.44249473, -0.44234836, -0.44220180, -0.44205508, -0.44190817, -0.44176110, -0.44161385, -0.44146642, -0.44131882, -0.44117105, -0.44102310, -0.44087498, -0.44072668, -0.44057821, -0.44042957, -0.44028075, -0.44013176, -0.43998259, -0.43983325, -0.43968374, -0.43953405, -0.43938419, -0.43923416, -0.43908395, -0.43893357, -0.43878302, -0.43863229, -0.43848139, -0.43833032, -0.43817907,
-0.43802765, -0.43787606, -0.43772429, -0.43757235, -0.43742024, -0.43726796, -0.43711550, -0.43696287, -0.43681007, -0.43665710, -0.43650395, -0.43635063, -0.43619714, -0.43604348, -0.43588964, -0.43573563, -0.43558145, -0.43542710, -0.43527258, -0.43511788, -0.43496302, -0.43480798, -0.43465277, -0.43449738, -0.43434183, -0.43418610, -0.43403021, -0.43387414, -0.43371790, -0.43356149, -0.43340491, -0.43324815, -0.43309123, -0.43293413, -0.43277687, -0.43261943, -0.43246182, -0.43230404, -0.43214609, -0.43198797, -0.43182968, -0.43167122, -0.43151259, -0.43135379, -0.43119482, -0.43103567, -0.43087636, -0.43071688, -0.43055722, -0.43039740, -0.43023741, -0.43007724, -0.42991691, -0.42975641, -0.42959574, -0.42943490, -0.42927388, -0.42911270, -0.42895135, -0.42878983, -0.42862814, -0.42846629, -0.42830426, -0.42814206, -0.42797970, -0.42781716, -0.42765446, -0.42749159, -0.42732854, -0.42716534, -0.42700196, -0.42683841, -0.42667469, -0.42651081, -0.42634676, -0.42618254, -0.42601815, -0.42585359, -0.42568886, -0.42552397, -0.42535891, -0.42519368, -0.42502828, -0.42486271, -0.42469698, -0.42453108, -0.42436501, -0.42419878, -0.42403237, -0.42386580, -0.42369906, -0.42353216, -0.42336508, -0.42319784, -0.42303044, -0.42286286, -0.42269512, -0.42252721, -0.42235914, -0.42219090,
-0.42202249, -0.42185391, -0.42168517, -0.42151626, -0.42134719, -0.42117795, -0.42100854, -0.42083897, -0.42066923, -0.42049932, -0.42032925, -0.42015901, -0.41998861, -0.41981804, -0.41964730, -0.41947640, -0.41930534, -0.41913410, -0.41896271, -0.41879114, -0.41861941, -0.41844752, -0.41827546, -0.41810324, -0.41793085, -0.41775829, -0.41758557, -0.41741269, -0.41723964, -0.41706643, -0.41689305, -0.41671950, -0.41654580, -0.41637193, -0.41619789, -0.41602369, -0.41584932, -0.41567479, -0.41550010, -0.41532524, -0.41515022, -0.41497504, -0.41479969, -0.41462417, -0.41444850, -0.41427266, -0.41409665, -0.41392048, -0.41374415, -0.41356766, -0.41339100, -0.41321418, -0.41303720, -0.41286005, -0.41268274, -0.42500527, -0.41232763, -0.41214983, -0.41197187, -0.41179374, -0.41161546, -0.41143701, -0.41125840, -0.41107962, -0.41090069, -0.41072159, -0.41054233, -0.41036290, -0.41018332, -0.41000357, -0.40982366, -0.40964359, -0.40946336, -0.40928296, -0.40910241, -0.40892169, -0.40874081, -0.40855977, -0.40837857, -0.40819721, -0.40801568, -0.40783400, -0.40765215, -0.40747014, -0.40728798, -0.40710565, -0.40692316, -0.40674051, -0.40655770, -0.40637472, -0.40619159, -0.40600830, -0.40582485, -0.40564124, -0.40545746, -0.40527353, -0.40508944, -0.40490518, -0.40472077, -0.40453620,
-0.40435146, -0.40416657, -0.40398152, -0.40379631, -0.40361094, -0.40342541, -0.40323972, -0.40305387, -0.40286786, -0.40268170, -0.40249537, -0.40230888, -0.40212224, -0.40193544, -0.40174848, -0.40156136, -0.40137408, -0.40118664, -0.40099905, -0.40081129, -0.40062338, -0.40043531, -0.40024708, -0.40005870, -0.39987015, -0.39968145, -0.39949259, -0.39930357, -0.39911440, -0.39892506, -0.39873557, -0.39854593, -0.39835612, -0.39816616, -0.39797604, -0.39778576, -0.39759533, -0.39740474, -0.39721399, -0.39702308, -0.39683202, -0.39664080, -0.39644943, -0.39625790, -0.39606621, -0.39587437, -0.39568237, -0.39549021, -0.39529790, -0.39510543, -0.39491280, -0.39472002, -0.39452708, -0.39433399, -0.39414074, -0.39394734, -0.39375378, -0.39356006, -0.39336619, -0.39317217, -0.39297799, -0.39278365, -0.39258916, -0.39239451, -0.39219971, -0.39200476, -0.39180965, -0.39161438, -0.39141896, -0.39122339, -0.39102766, -0.39083177, -0.39063573, -0.39043954, -0.39024320, -0.39004670, -0.38985004, -0.38965323, -0.38945627, -0.38925915, -0.38906188, -0.38886446, -0.38866688, -0.38846915, -0.38827127, -0.38807323, -0.38787504, -0.38767670, -0.38747820, -0.38727955, -0.38708075, -0.38688179, -0.38668269, -0.38648343, -0.38628401, -0.38608445, -0.38588473, -0.38568486, -0.38548483, -0.38528466,
-0.38508433, -0.38488385, -0.38468322, -0.38448244, -0.38428150, -0.38408041, -0.38387918, -0.38367779, -0.38347624, -0.38327455, -0.38307271, -0.38287071, -0.38266856, -0.38246627, -0.38226382, -0.38206122, -0.38185847, -0.38165556, -0.38145251, -0.38124931, -0.38104596, -0.38084245, -0.38063880, -0.38043499, -0.38023104, -0.38002693, -0.37982268, -0.37961827, -0.37941372, -0.37920901, -0.37900416, -0.37879916, -0.37859400, -0.37838870, -0.37818325, -0.37797764, -0.37777189, -0.37756599, -0.37735994, -0.37715374, -0.37694740, -0.37674090, -0.37653426, -0.37632746, -0.37612052, -0.37591343, -0.37570619, -0.37549880, -0.37529127, -0.37508358, -0.37487575, -0.37466777, -0.37445964, -0.37425137, -0.37404294, -0.37383437, -0.37362565, -0.37341679, -0.37320777, -0.37299861, -0.37278930, -0.37257985, -0.37237024, -0.37216049, -0.37195060, -0.37174055, -0.37153036, -0.37132003, -0.37110954, -0.37089891, -0.37068813, -0.37047721, -0.37026614, -0.37005493, -0.36984356, -0.36963206, -0.36942040, -0.36920860, -0.36899666, -0.36878457, -0.36857233, -0.36835995, -0.36814742, -0.36793475, -0.36772193, -0.36750896, -0.36729585, -0.36708260, -0.36686920, -0.36665566, -0.36644197, -0.36622814, -0.36601416, -0.36580004, -0.36558577, -0.36537136, -0.36515680, -0.36494210, -0.36472726, -0.36451227,
-0.36429714, -0.36408187, -0.36386645, -0.36365088, -0.36343518, -0.36321933, -0.36300333, -0.36278720, -0.36257092, -0.36235449, -0.36213793, -0.36192122, -0.36170437, -0.36148737, -0.36127023, -0.36105295, -0.36083553, -0.36061797, -0.36040026, -0.36018241, -0.35996442, -0.35974628, -0.35952800, -0.35930959, -0.35909103, -0.35887232, -0.35865348, -0.35843449, -0.35821537, -0.35799610, -0.35777669, -0.35755714, -0.35733745, -0.35711761, -0.35689764, -0.35667752, -0.35645727, -0.35623687, -0.35601633, -0.35579565, -0.35557484, -0.35535388, -0.35513278, -0.35491154, -0.35469016, -0.35446864, -0.35424698, -0.35402518, -0.35380324, -0.35358116, -0.35335894, -0.35313658, -0.35291409, -0.35269145, -0.35246867, -0.35224576, -0.35202270, -0.35179951, -0.35157618, -0.35135271, -0.35112909, -0.35090535, -0.35068146, -0.35045743, -0.35023327, -0.35000897, -0.34978453, -0.34955995, -0.34933523, -0.34911038, -0.34888538, -0.34866025, -0.34843499, -0.34820958, -0.34798404, -0.34775836, -0.34753254, -0.34730658, -0.34708049, -0.34685426, -0.34662790, -0.34640139, -0.34617475, -0.34594798, -0.34572106, -0.34549401, -0.34526683, -0.34503951, -0.34481205, -0.34458445, -0.34435672, -0.34412885, -0.34390085, -0.34367271, -0.34344444, -0.34321603, -0.34298748, -0.34275880, -0.34252999, -0.34230104,
-0.34207195, -0.34184273, -0.34161337, -0.34138388, -0.34115425, -0.34092449, -0.34069460, -0.34046457, -0.34023440, -0.34000410, -0.33977367, -0.33954310, -0.33931240, -0.33908157, -0.33885060, -0.33861949, -0.33838826, -0.33815689, -0.33792538, -0.33769375, -0.33746198, -0.33723007, -0.33699803, -0.33676586, -0.33653356, -0.33630113, -0.33606856, -0.33583585, -0.33560302, -0.33537005, -0.33513695, -0.33490372, -0.33467036, -0.33443686, -0.33420324, -0.33396948, -0.33373558, -0.33350156, -0.33326741, -0.33303312, -0.33279870, -0.33256415, -0.33232947, -0.33209466, -0.33185972, -0.33162464, -0.33138944, -0.33115410, -0.33091863, -0.33068303, -0.33044731, -0.33021145, -0.32997546, -0.32973934, -0.32950309, -0.32926671, -0.32903020, -0.32879356, -0.32855679, -0.32831989, -0.32808286, -0.32784571, -0.32760842, -0.32737100, -0.32713345, -0.32689578, -0.32665797, -0.32642004, -0.32618198, -0.32594379, -0.32570547, -0.32546702, -0.32522844, -0.32498973, -0.32475090, -0.32451194, -0.32427285, -0.32403363, -0.32379428, -0.32355481, -0.32331521, -0.32307548, -0.32283562, -0.32259564, -0.32235552, -0.32211529, -0.32187492, -0.32163443, -0.32139380, -0.32115306, -0.32091218, -0.32067118, -0.32043005, -0.32018880, -0.31994742, -0.31970591, -0.31946428, -0.31922252, -0.31898064, -0.31873862,
-0.31849649, -0.31825422, -0.31801184, -0.31776932, -0.31752668, -0.31728392, -0.31704103, -0.31679801, -0.31655487, -0.31631160, -0.31606821, -0.31582470, -0.31558106, -0.31533729, -0.31509341, -0.31484939, -0.31460525, -0.31436099, -0.31411661, -0.31387210, -0.31362746, -0.31338270, -0.31313782, -0.31289282, -0.31264769, -0.31240243, -0.31215706, -0.31191156, -0.31166594, -0.31142019, -0.31117432, -0.31092833, -0.31068222, -0.31043598, -0.31018962, -0.30994314, -0.30969654, -0.30944981, -0.30920296, -0.30895599, -0.30870890, -0.30846169, -0.30821435, -0.30796689, -0.30771931, -0.30747161, -0.30722379, -0.30697584, -0.30672778, -0.30647959, -0.30623129, -0.30598286, -0.30573431, -0.30548564, -0.30523685, -0.30498794, -0.30473891, -0.30448976, -0.30424048, -0.30399109, -0.30374158, -0.30349195, -0.30324220, -0.30299233, -0.30274233, -0.30249222, -0.30224199, -0.30199164, -0.30174118, -0.30149059, -0.30123988, -0.30098906, -0.30073811, -0.30048705, -0.30023587, -0.29998456, -0.29973315, -0.29948161, -0.29922995, -0.29897818, -0.29872629, -0.29847428, -0.29822215, -0.29796990, -0.29771754, -0.29746506, -0.29721246, -0.29695975, -0.29670691, -0.29645396, -0.29620090, -0.29594771, -0.29569441, -0.29544100, -0.29518746, -0.29493381, -0.29468004, -0.29442616, -0.29417216, -0.29391804,
-0.29366381, -0.29340946, -0.29315500, -0.29290042, -0.29264573, -0.29239091, -0.29213599, -0.29188095, -0.29162579, -0.29137052, -0.29111513, -0.29085963, -0.29060401, -0.29034828, -0.29009243, -0.28983647, -0.28958040, -0.28932421, -0.28906790, -0.28881149, -0.28855495, -0.28829831, -0.28804155, -0.28778468, -0.28752769, -0.28727059, -0.28701337, -0.28675605, -0.28649861, -0.28624105, -0.28598338, -0.28572560, -0.28546771, -0.28520971, -0.28495159, -0.28469336, -0.28443502, -0.28417656, -0.28391799, -0.28365931, -0.28340052, -0.28314162, -0.28288260, -0.28262348, -0.28236424, -0.28210489, -0.28184543, -0.28158585, -0.28132617, -0.28106638, -0.28080647, -0.28054645, -0.28028632, -0.28002609, -0.27976574, -0.27950528, -0.27924471, -0.27898403, -0.27872324, -0.27846234, -0.27820133, -0.27794021, -0.27767898, -0.27741764, -0.27715619, -0.27689463, -0.27663296, -0.27637119, -0.27610930, -0.27584731, -0.27558520, -0.27532299, -0.27506067, -0.27479824, -0.27453570, -0.27427305, -0.27401030, -0.27374743, -0.27348446, -0.27322138, -0.27295819, -0.27269490, -0.27243150, -0.27216799, -0.27190437, -0.27164064, -0.27137681, -0.27111287, -0.27084882, -0.27058467, -0.27032041, -0.27005604, -0.26979157, -0.26952699, -0.26926230, -0.26899751, -0.26873261, -0.26846760, -0.26820249, -0.26793727,
-0.26767195, -0.26740652, -0.26714099, -0.26687535, -0.26660960, -0.26634375, -0.26607779, -0.26581173, -0.26554557, -0.26527930, -0.26501292, -0.26474644, -0.26447985, -0.26421317, -0.26394637, -0.26367947, -0.26341247, -0.26314537, -0.26287816, -0.26261084, -0.26234343, -0.26207591, -0.26180828, -0.26154055, -0.26127272, -0.26100479, -0.26073675, -0.26046861, -0.26020037, -0.25993202, -0.25966357, -0.25939502, -0.25912637, -0.25885761, -0.25858876, -0.25831980, -0.25805073, -0.25778157, -0.25751230, -0.25724294, -0.25697347, -0.25670390, -0.25643423, -0.25616445, -0.25589458, -0.25562460, -0.25535453, -0.25508435, -0.25481407, -0.25454369, -0.25427322, -0.25400264, -0.25373196, -0.25346118, -0.25319030, -0.25291932, -0.25264824, -0.25237706, -0.25210578, -0.25183440, -0.25156292, -0.25129135, -0.25101967, -0.25074789, -0.25047602, -0.25020405, -0.24993197, -0.24965980, -0.24938753, -0.24911516, -0.24884270, -0.24857013, -0.24829747, -0.24802471, -0.24775185, -0.24747889, -0.24720584, -0.24693269, -0.24665944, -0.24638609, -0.24611265, -0.24583910, -0.24556547, -0.24529173, -0.24501790, -0.24474397, -0.24446994, -0.24419582, -0.24392160, -0.24364729, -0.24337288, -0.24309837, -0.24282376, -0.24254907, -0.24227427, -0.24199938, -0.24172439, -0.24144931, -0.24117414, -0.24089886,
-0.24062350, -0.24034803, -0.24007248, -0.23979682, -0.23952108, -0.23924524, -0.23896930, -0.23869327, -0.23841715, -0.23814093, -0.23786461, -0.23758821, -0.23731171, -0.23703511, -0.23675843, -0.23648165, -0.23620477, -0.23592780, -0.23565074, -0.23537359, -0.23509634, -0.23481900, -0.23454157, -0.23426404, -0.23398643, -0.23370872, -0.23343091, -0.23315302, -0.23287503, -0.23259695, -0.23231878, -0.23204052, -0.23176217, -0.23148372, -0.23120519, -0.23092656, -0.23064784, -0.23036903, -0.23009013, -0.22981114, -0.22953205, -0.22925288, -0.22897362, -0.22869426, -0.22841482, -0.22813528, -0.22785566, -0.22757594, -0.22729614, -0.22701625, -0.22673626, -0.22645619, -0.22617602, -0.22589577, -0.22561543, -0.22533500, -0.22505448, -0.22477387, -0.22449318, -0.22421239, -0.22393152, -0.22365055, -0.22336950, -0.22308836, -0.22280713, -0.22252582, -0.22224442, -0.22196293, -0.22168135, -0.22139968, -0.22111793, -0.22083609, -0.22055416, -0.22027214, -0.21999004, -0.21970785, -0.21942558, -0.21914321, -0.21886076, -0.21857823, -0.21829561, -0.21801290, -0.21773011, -0.21744723, -0.21716426, -0.21688121, -0.21659807, -0.21631485, -0.21603154, -0.21574815, -0.21546467, -0.21518110, -0.21489746, -0.21461372, -0.21432990, -0.21404600, -0.21376201, -0.21347794, -0.21319379, -0.21290955,
-0.21262522, -0.21234081, -0.21205632, -0.21177175, -0.21148709, -0.21120234, -0.21091752, -0.21063261, -0.21034761, -0.21006254, -0.20977738, -0.20949214, -0.20920681, -0.20892141, -0.20863592, -0.20835034, -0.20806469, -0.20777895, -0.20749314, -0.20720723, -0.20692125, -0.20663519, -0.20634904, -0.20606282, -0.20577651, -0.20549012, -0.20520365, -0.20491710, -0.20463046, -0.20434375, -0.20405696, -0.20377008, -0.20348313, -0.20319609, -0.20290897, -0.20262178, -0.20233450, -0.20204715, -0.20175971, -0.20147220, -0.20118460, -0.20089693, -0.20060917, -0.20032134, -0.20003343, -0.19974544, -0.19945737, -0.19916922, -0.19888099, -0.19859269, -0.19830430, -0.19801584, -0.19772730, -0.19743868, -0.19714999, -0.19686121, -0.19657236, -0.19628343, -0.19599442, -0.19570534, -0.19541618, -0.19512694, -0.19483762, -0.19454823, -0.19425876, -0.19396921, -0.19367959, -0.19338989, -0.19310011, -0.19281026, -0.19252033, -0.19223033, -0.19194025, -0.19165009, -0.19135986, -0.19106955, -0.19077917, -0.19048871, -0.19019818, -0.18990757, -0.18961688, -0.18932613, -0.18903529, -0.18874439, -0.18845340, -0.18816235, -0.18787122, -0.18758001, -0.18728873, -0.18699738, -0.18670595, -0.18641445, -0.18612288, -0.18583123, -0.18553951, -0.18524771, -0.18495584, -0.18466390, -0.18437189, -0.18407980,
-0.18378764, -0.18349541, -0.18320311, -0.18291073, -0.18261828, -0.18232576, -0.18203317, -0.18174051, -0.18144777, -0.18115496, -0.18086208, -0.18056913, -0.18027611, -0.17998301, -0.17968985, -0.17939661, -0.17910331, -0.17880993, -0.17851648, -0.17822297, -0.17792938, -0.17763572, -0.17734199, -0.17704819, -0.17675432, -0.17646038, -0.17616637, -0.17587230, -0.17557815, -0.17528393, -0.17498965, -0.17469529, -0.17440087, -0.17410637, -0.17381181, -0.17351718, -0.17322248, -0.17292772, -0.17263288, -0.17233798, -0.17204301, -0.17174797, -0.17145286, -0.17115768, -0.17086244, -0.17056713, -0.17027175, -0.16997631, -0.16968080, -0.16938522, -0.16908957, -0.16879386, -0.16849808, -0.16820224, -0.16790632, -0.16761035, -0.16731430, -0.16701819, -0.16672201, -0.16642577, -0.16612946, -0.16583309, -0.16553665, -0.16524015, -0.16494358, -0.16464694, -0.16435024, -0.16405348, -0.16375665, -0.16345975, -0.16316279, -0.16286577, -0.16256868, -0.16227153, -0.16197431, -0.16167703, -0.16137969, -0.16108228, -0.16078481, -0.16048728, -0.16018968, -0.15989202, -0.15959430, -0.15929651, -0.15899866, -0.15870074, -0.15840277, -0.15810473, -0.15780663, -0.15750847, -0.15721024, -0.15691196, -0.15661361, -0.15631520, -0.15601672, -0.15571819, -0.15541959, -0.15512094, -0.15482222, -0.15452344,
-0.15422460, -0.15392570, -0.15362673, -0.15332771, -0.15302863, -0.15272948, -0.15243028, -0.15213101, -0.15183169, -0.15153231, -0.15123286, -0.15093336, -0.15063379, -0.15033417, -0.15003449, -0.14973475, -0.14943495, -0.14913509, -0.14883517, -0.14853519, -0.14823516, -0.14793506, -0.14763491, -0.14733470, -0.14703443, -0.14673410, -0.14643371, -0.14613327, -0.14583277, -0.14553221, -0.14523160, -0.14493092, -0.14463019, -0.14432940, -0.14402856, -0.14372766, -0.14342670, -0.14312568, -0.14282461, -0.14252348, -0.14222230, -0.14192106, -0.14161976, -0.14131841, -0.14101700, -0.14071554, -0.14041402, -0.14011245, -0.13981082, -0.13950913, -0.13920739, -0.13890559, -0.13860374, -0.13830184, -0.13799988, -0.13769787, -0.13739580, -0.13709367, -0.13679150, -0.13648927, -0.13618698, -0.13588464, -0.13558225, -0.13527981, -0.13497731, -0.13467475, -0.13437215, -0.13406949, -0.13376678, -0.13346401, -0.13316120, -0.13285833, -0.13255541, -0.13225243, -0.13194940, -0.13164633, -0.13134320, -0.13104001, -0.13073678, -0.13043349, -0.13013015, -0.12982677, -0.12952333, -0.12921983, -0.12891629, -0.12861270, -0.12830906, -0.12800536, -0.12770162, -0.12739782, -0.12709397, -0.12679008, -0.12648613, -0.12618214, -0.12587809, -0.12557399, -0.12526985, -0.12496565, -0.12466141, -0.12435712,
-0.12405277, -0.12374838, -0.12344394, -0.12313945, -0.12283492, -0.12253033, -0.12222570, -0.12192101, -0.12161628, -0.12131150, -0.12100668, -0.12070180, -0.12039688, -0.12009191, -0.11978689, -0.11948183, -0.11917672, -0.11887156, -0.11856635, -0.11826110, -0.11795580, -0.11765045, -0.11734506, -0.11703962, -0.11673414, -0.11642861, -0.11612303, -0.11581741, -0.11551174, -0.11520603, -0.11490027, -0.11459446, -0.11428861, -0.11398272, -0.11367678, -0.11337079, -0.11306476, -0.11275869, -0.11245257, -0.11214640, -0.11184020, -0.11153394, -0.11122765, -0.11092131, -0.11061492, -0.11030850, -0.11000203, -0.10969551, -0.10938895, -0.10908235, -0.10877571, -0.10846902, -0.10816229, -0.10785552, -0.10754870, -0.10724185, -0.10693495, -0.10662800, -0.10632102, -0.10601399, -0.10570693, -0.10539982, -0.10509267, -0.10478547, -0.10447824, -0.10417096, -0.10386365, -0.10355629, -0.10324889, -0.10294145, -0.10263397, -0.10232645, -0.10201889, -0.10171129, -0.10140365, -0.10109597, -0.10078824, -0.10048048, -0.10017268, -0.09986484, -0.09955696, -0.09924904, -0.09894108, -0.09863309, -0.09832505, -0.09801698, -0.09770886, -0.09740071, -0.09709252, -0.09678429, -0.09647602, -0.09616772, -0.09585937, -0.09555099, -0.09524257, -0.09493412, -0.09462562, -0.09431709, -0.09400852, -0.09369992,
-0.09339127, -0.09308259, -0.09277388, -0.09246512, -0.09215633, -0.09184751, -0.09153865, -0.09122975, -0.09092081, -0.09061184, -0.09030284, -0.08999379, -0.08968472, -0.08937560, -0.08906646, -0.08875727, -0.08844805, -0.08813880, -0.08782951, -0.08752019, -0.08721083, -0.08690144, -0.08659202, -0.08628256, -0.08597306, -0.08566353, -0.08535397, -0.08504438, -0.08473475, -0.08442508, -0.08411539, -0.08380566, -0.08349590, -0.08318610, -0.08287627, -0.08256641, -0.08225652, -0.08194659, -0.08163663, -0.08132664, -0.08101662, -0.08070657, -0.08039648, -0.08008636, -0.07977621, -0.07946603, -0.07915582, -0.07884557, -0.07853530, -0.07822499, -0.07791465, -0.07760429, -0.07729389, -0.07698346, -0.07667300, -0.07636251, -0.07605199, -0.07574144, -0.07543086, -0.07512025, -0.07480961, -0.07449894, -0.07418824, -0.07387752, -0.07356676, -0.07325597, -0.07294516, -0.07263432, -0.07232344, -0.07201254, -0.07170161, -0.07139066, -0.07107967, -0.07076866, -0.07045761, -0.07014655, -0.06983545, -0.06952432, -0.06921317, -0.06890199, -0.06859078, -0.06827955, -0.06796829, -0.06765700, -0.06734569, -0.06703435, -0.06672298, -0.06641159, -0.06610017, -0.06578872, -0.06547725, -0.06516575, -0.06485423, -0.06454268, -0.06423110, -0.06391950, -0.06360788, -0.06329623, -0.06298455, -0.06267285,
-0.06236113, -0.06204938, -0.06173760, -0.06142580, -0.06111398, -0.06080213, -0.06049026, -0.06017837, -0.05986645, -0.05955451, -0.05924254, -0.05893055, -0.05861854, -0.05830650, -0.05799445, -0.05768236, -0.05737026, -0.05705813, -0.05674598, -0.05643381, -0.05612162, -0.05580940, -0.05549716, -0.05518490, -0.05487262, -0.05456032, -0.05424799, -0.05393565, -0.05362328, -0.05331089, -0.05299848, -0.05268605, -0.05237359, -0.05206112, -0.05174863, -0.05143612, -0.05112358, -0.05081103, -0.05049845, -0.05018586, -0.04987325, -0.04956061, -0.04924796, -0.04893529, -0.04862259, -0.04830988, -0.04799715, -0.04768440, -0.04737164, -0.04705885, -0.04674604, -0.04643322, -0.04612038, -0.04580752, -0.04549464, -0.04518174, -0.04486883, -0.04455590, -0.04424295, -0.04392998, -0.04361700, -0.04330399, -0.04299098, -0.04267794, -0.04236489, -0.04205182, -0.04173873, -0.04142563, -0.04111251, -0.04079938, -0.04048623, -0.04017306, -0.03985988, -0.03954668, -0.03923346, -0.03892023, -0.03860699, -0.03829373, -0.03798045, -0.03766716, -0.03735386, -0.03704054, -0.03672720, -0.03641385, -0.03610049, -0.03578711, -0.03547372, -0.03516031, -0.03484689, -0.03453346, -0.03422001, -0.03390655, -0.03359308, -0.03327959, -0.03296609, -0.03265258, -0.03233905, -0.03202551, -0.03171196, -0.03139840,
-0.03108482, -0.03077123, -0.03045763, -0.03014402, -0.02983039, -0.02951675, -0.02920310, -0.02888944, -0.02857577, -0.02826209, -0.02794840, -0.02763469, -0.02732098, -0.02700725, -0.02669351, -0.02637976, -0.02606601, -0.02575224, -0.02543846, -0.02512467, -0.02481087, -0.02449706, -0.02418324, -0.02386942, -0.02355558, -0.02324173, -0.02292788, -0.02261401, -0.02230014, -0.02198626, -0.02167237, -0.02135847, -0.02104456, -0.02073064, -0.02041672, -0.02010278, -0.01978884, -0.01947489, -0.01916094, -0.01884698, -0.01853300, -0.01821903, -0.01790504, -0.01759105, -0.01727705, -0.01696304, -0.01664903, -0.01633501, -0.01602098, -0.01570695, -0.01539291, -0.01507887, -0.01476482, -0.01445076, -0.01413670, -0.01382263, -0.01350856, -0.01319448, -0.01288039, -0.01256630, -0.01225221, -0.01193811, -0.01162401, -0.01130990, -0.01099579, -0.01068167, -0.01036755, -0.01005342, -0.00973930, -0.00942516, -0.00911103, -0.00879689, -0.00848274, -0.00816859, -0.00785444, -0.00754029, -0.00722613, -0.00691197, -0.00659781, -0.00628365, -0.00596948, -0.00565531, -0.00534114, -0.00502697, -0.00471279, -0.00439861, -0.00408443, -0.00377025, -0.00345607, -0.00314189, -0.00282770, -0.00251351, -0.00219933, -0.00188514, -0.00157095, -0.00125676, -0.00094257, -0.00062838, -0.00031419, -0.00000000
};
/* USER CODE END PFP */

/* USER CODE BEGIN 0 */

char frev[10];//串口屏幕获得
volatile unsigned char frev2[8];//串口屏幕获得
volatile uint16_t fre;
volatile uint32_t fre2;
volatile uint16_t f;//Fre zi
volatile uint8_t AD_flag = 0;
volatile uint8_t AD_flag2 = 0;
volatile uint8_t DA_flag = 0;
float va;
uint16_t AD_value[10000];
uint16_t AD_value2[10000];
uint16_t AD_valuefft[2048];
uint16_t DA_value[10000];
uint16_t DA_set[2000];
float Fre_v[5001];
float Fre_p[5001];
float Fre_s[5001];
float Fre_c[5001];
float frequency;
uint16_t count_max;
float fs;

volatile _Bool halflag=0;
volatile _Bool comflag=0;

float  FFT_INPUT [FFT_LEN *2];   //fft输入数组 ，大小是二倍的点数

float FFT_OUTPUT[FFT_LEN];  ///fft输出数组

float adc_value[FFT_LEN];  /// adc读取数组

uint16_t rise_cut=0;
uint16_t fall_cut=0;
uint8_t cut_count = 0;
uint16_t maxindex=2;
uint16_t minindex=2;

//串口指令
void get() {
		uint8_t index;
		fre = 0;
		va=0;
		for (int i = 0; i < 10; i++)
		{
				if(frev[i]==0x01)
				{
					index=i;
					break;
				}
		}
		for (int i = 1; i < index; i++)
		{
				fre = fre * 10 + (frev[i] - '0');
		}
		va=(float)(frev[index+1]- '0')*1.0f+(float)(frev[index+3]- '0')/10.0f;

}

void get2()
{
    uint8_t index = 0xFF;  // 初始为非法值
    fre2 = 0;              // fre2 清零

    for (int i = 0; i < 8; i++)
    {
        if (frev2[i] == 0xFF)
        {
            index = i;
            break;
        }
    }

    if (index != 0xFF)  // 找到0xFF
    {
        for (int i = 0; i < index; i++)
        {
            fre2 = fre2 * 10 + (frev2[i] - '0');
        }
    }
    else
    {
        // 错误处理：没有找到0xFF
        fre2 = 0;
    }
}

void detect_filter(uint16_t size)
{
    float threshold = 0.707f;  // -3dB点
//    uint16_t rise_cut = 0, fall_cut = 0;
//    uint8_t cut_count = 0;

    // 找到拐点
    for (uint16_t i = 2; i < size; i++)
    {
			 if(Fre_v[i]>Fre_v[maxindex])
			 {
				 maxindex=i;
			 }
			 if(Fre_v[i]<Fre_v[minindex])
			 {
				 minindex=i;
			 }
        if (Fre_v[i - 1] >= threshold && Fre_v[i] < threshold)
        {
            fall_cut = i;
            cut_count++;
        }
        if (Fre_v[i - 1] <= threshold && Fre_v[i] > threshold)
        {
            rise_cut = i;
            cut_count++;
        }
    }

    if (cut_count == 2)
    {
        // 检查rise_cut和fall_cut之间是否一直高于threshold
        uint8_t is_bandpass = 1;
			if(rise_cut<fall_cut)
			{
        for (uint16_t i = rise_cut + 1; i < fall_cut; i++)
        {
            if (Fre_v[i] < threshold)
            {
                is_bandpass = 0;
                break;
            }
        }
			}
			else
			{
				is_bandpass = 0;
				for (uint16_t i = fall_cut + 1; i < rise_cut; i++)
        {
            if (Fre_v[i] > threshold)
            {
                is_bandpass = 1;
                break;
            }
        }
			}
        if (is_bandpass)
        {
            tjc_send_txt("t5", "txt", "band pass");
        }
        else
        {
            tjc_send_txt("t5", "txt", "band stop");
        }
    }
    else if (cut_count == 1)
    {
        if (rise_cut == 0)
        {
            tjc_send_txt("t5", "txt", "low pass");
        }
        else if (fall_cut == 0)
        {
            tjc_send_txt("t5", "txt", "high pass");
        }
    }
    else
    {
			if((maxindex-minindex)>4000&&maxindex>minindex)
			{
				tjc_send_txt("t5", "txt", "high pass");
			}
			else
				tjc_send_txt("t5", "txt", "Unknown");
    }
}

//单位 Khz
void Set_SampleRate(TIM_TypeDef *timer, uint32_t target_freq) {
    uint32_t timer_clk = 240000;  // 240MHz
    uint32_t psc;
//		__HAL_TIM_DISABLE(&htim4);  // 可选，防止CNT正好在边界

		__HAL_TIM_SET_COUNTER(&htim4, 0);  // CNT清零（可选，看需求）
    if (target_freq == 0) return;  // 防止除0错误

    // 计算ARR重装数
    psc = (timer_clk / target_freq) - 1;

    // 限制ARR合法范围 (16位定时器最大65535)
    if (psc > 0xFFFF) psc = 0xFFFF;
		TIM4->ARR=psc;

//		TIM4->EGR = TIM_EGR_UG;  // 触发更新事件，让ARR和PSC立即生效

//		__HAL_TIM_ENABLE(&htim4);  // 可选，重新启用
}

void dftphase(int fre)
{
	float s1;
	float c1;
	float s1q;
	float c1q;
	float v1,v1q;
	uint16_t fc1=2500;
	uint16_t f1=0;
	s1=0;
	c1=0;
	s1q=0;
	c1q=0;
	float p1,p1q;
	 for (int i=0;i<10000;i++)
    {
        s1+=(float)AD_value[i]*si_10000[f1];
        c1+=(float)AD_value[i]*si_10000[fc1];
			  s1q+=(float)AD_value2[i]*si_10000[f1];
        c1q+=(float)AD_value2[i]*si_10000[fc1];
        f1+=fre;
				fc1+=fre;
        if (f1>=10000)
        {
            f1-=10000;
        }
        if (fc1>=10000)
        {
            fc1-=10000;
        }
		}
//	s1/=2500.0f;
//	c1/=2500.0f;
//	s1q/=2500.0f;
//	c1q/=2500.0f;
		v1q=s1q*s1q+c1q*c1q;
		Fre_c[fre]=(c1*c1q+s1*s1q)/v1q;
		Fre_s[fre]=(s1q*c1-s1*c1q)/v1q;
		Fre_v[fre]=sqrtf(Fre_c[fre]*Fre_c[fre]+Fre_s[fre]*Fre_s[fre]);
//		Fre_v[fre]=sqrtf(Fre_c[fre]*Fre_c[fre]*v1q+Fre_s[fre]*Fre_s[fre]*v1q);
}

//扫频，幅频特性
void sweep()
{
	uint32_t fre;
	AD9910_AmpWrite(6000);

	for(int i = 0; i <5001; i++)
	{
		fre = i * 200;
		AD9910_FreWrite(fre);
//		HAL_Delay(1);
		AD_flag = 0;  // 先清零
		AD_flag2=0;
		Set_SampleRate(TIM4,2000);//1000khz
		HAL_ADC_Start_DMA(&hadc1, (uint32_t*)AD_value,10000);
		HAL_ADC_Start_DMA(&hadc2, (uint32_t*)AD_value2,10000);
		HAL_TIM_Base_Start(&htim4);
		while(AD_flag == 0&&AD_flag2==0);
//		Fre_v[i]=calculate_amplitude();
		dftphase(i);
		printf("add s0.id,16,%d\xff\xff\xff",(int)(Fre_v[i]*256) );
		printf("add s1.id,17,%d\xff\xff\xff",(int)(atanf(Fre_s[i]/Fre_c[i])/3.14159)*128+128 );
	}
	detect_filter(5001);
	tjc_send_txt("t8", "txt", "Success!");
}

float s[20], c[20];
float prev_phase[20] = {0};
float f_step[20];
float freq_error_acc[20] = {0};

void dft()
{
    // DFT前缀初始化
		uint16_t f_idx[20] ;     // 正弦索引
		uint16_t fc_idx[20] ; // 余弦索引
		uint16_t f_step[20];
	    for (int n = 0; n < 20; n++)
    {
			s[n]=0;
			c[n]=0;
      f_idx[n] = 0;
      fc_idx[n] = 2500;
    }
       // 每次谐波的步进

    // 步进因子初始化
    for (int n = 0; n < 20; n++)
    {
        f_step[n] = f * (n + 1) + (n + 1) * 5;
    }

    // === DFT计算 ===
    for (int i = 0; i < 10000; i++)
    {
        for (int n = 0; n < 20; n++)
        {
            s[n] += (float)AD_value[i] * si_10000[f_idx[n]];
            c[n] += (float)AD_value[i] * si_10000[fc_idx[n]];

            f_idx[n] += f_step[n];
            fc_idx[n] += f_step[n];

            if (f_idx[n] >= 10000) f_idx[n] -= 10000;
            if (fc_idx[n] >= 10000) fc_idx[n] -= 10000;
        }
    }

		for (int n = 0; n < 20; n++)
    {
        s[n] /= 1250.0f;
        c[n] /= 1250.0f;
				if (s[n]*s[n]+c[n]*c[n]<20.0)
				{
					s[n]=0;
					c[n]=0;
				}
    }
    float Kp = 0.005;  // 锁相增益（可调）
    for (int n = 0; n < 20; n++)
    {
//        s[n] /= 1250.0f;
//        c[n] /= 1250.0f;

        float phase = atan2f(s[n], c[n]);
        float delta_phase = phase - prev_phase[n];
				if(delta_phase<(3.14159f/100.0f))
				{
					Kp = 0.0005;
				}
				if(delta_phase<(3.14159f/1000.0f))
				{
					Kp = 0.00001;
				}
        // 处理相位跳变
        if (delta_phase > 3.14159f) delta_phase -= 6.28318f;
        if (delta_phase < -3.14159f) delta_phase += 6.28318f;

        prev_phase[n] = phase;
				f_idx[n] += Kp * delta_phase/3.14159f*5000.0f;
				fc_idx[n]+= Kp * delta_phase/3.14159f*5000.0f;
//				f_step[n]+= Kp * delta_phase*500/3.14159f/f;
				        // 限幅
        if (f_step[n] < n  * f) 		f_step[n] = (n + 1) * f;
        if (f_step[n] > (n + 2) *f) f_step[n] = (n + 1) * f;
		}
        // === 累加频率误差到 f_step ===
//    for (int n = 0; n < 20; n++)
//    {
//
//    }

    // === 重构信号 ===
    for (int i = 0; i < 10000; i++)
    {
        float sum = 0;
        for (int n = 0; n < 20; n++)
        {
            sum += (s[n] * Fre_c[f_step[n]] - c[n] * Fre_s[f_step[n]]) * si_10000[f_idx[n]];
            sum += (c[n] * Fre_c[f_step[n]] + s[n] * Fre_s[f_step[n]]) * si_10000[fc_idx[n]];

            f_idx[n] += f_step[n];
            fc_idx[n] += f_step[n];

            if (f_idx[n] >= 10000) f_idx[n] -= 10000;
            if (fc_idx[n] >= 10000) fc_idx[n] -= 10000;
        }
        DA_value[i] = 2048 + sum;
    }
}

uint16_t fft()
{
//		HAL_Delay(5);
		Set_SampleRate(TIM4,410);//arr 293-1
		HAL_TIM_Base_Start(&htim4);
		HAL_ADC_Start_DMA(&hadc1, (uint32_t*)AD_valuefft, FFT_LEN);
		while(AD_flag == 0);
		float fs=240000000.0f/(TIM4->ARR+1);
		float value_max = 0;

	  for (int i = 0; i < FFT_LEN; i++)
        {
             FFT_INPUT[2 * i] =(float)AD_valuefft[i]/4096.0f*3.3f;       // shi bu
             FFT_INPUT[2 * i + 1] = 0;              // xu  bu
        }
        //////////////////FFT计算
				arm_cfft_f32(&arm_cfft_sR_f32_len2048, FFT_INPUT, 0, 1);
				arm_cmplx_mag_f32(FFT_INPUT, FFT_OUTPUT, FFT_LEN);

        //FFT后的第一个赋值很大，最好跳过，
        for(int j=1 ;j<300;j++)
        {
            if(value_max<FFT_OUTPUT[j])
            {
                count_max = j;
                value_max = FFT_OUTPUT[j];
            }
        }
		 fre = fs*(count_max*1.0f)/(FFT_LEN*1.0f);
		 f=(uint16_t)((fre/200.0f+0.5f)-5.0f);
		 return f;
}

/* USER CODE END 0 */

int main(void)
{

  /* MPU Configuration--------------------------------------------------------*/
  MPU_Config();

  /* MCU Configuration--------------------------------------------------------*/

  /* Reset of all peripherals, Initializes the Flash interface and the Systick. */
  HAL_Init();

  /* Configure the system clock */
  SystemClock_Config();

  /* Configure the peripherals common clocks */
  PeriphCommonClock_Config();

  /* Initialize all configured peripherals */
  MX_GPIO_Init();
  MX_DMA_Init();
  MX_ADC1_Init();
  MX_DAC1_Init();
  MX_TIM6_Init();
  MX_USART1_UART_Init();
  MX_ADC2_Init();
  MX_TIM4_Init();
  /* USER CODE BEGIN 2 */
	Init_AD9910();
	initRingBuffer();
//	HAL_ADC_Start_DMA(&hadc1,(uint32_t*)AD_value,10000);
	HAL_UART_Receive_IT(&TJC_UART, RxBuffer, 1);
	tjc_send_txt("t8", "txt", " ");
	tjc_send_txt("t5", "txt", " ");
  /* USER CODE END 2 */

  /* Infinite loop */
  while (1)
  {

    /* USER CODE BEGIN 3 */
//		tjc_send_txt("t7", "txt", "S");

			while (usize >= 12)
				{
					// 校验帧头帧尾是否匹配
					if (u(0) == 0x03)
					{
						// 匹配，进行解析
						for(int i=0;i<10;i++)
						{
							frev[i]=u(i);
						}
						get();
						AD9910_FreWrite(fre);
						AD9910_AmpWrite((uint16_t)(va/Fre_respon[(fre/100)-1]/4.0f/5.0f/0.8f*16383));
						udelete(13); // 删除解析过的数据
					}
					else if(u(0)==0xff)
					{
						for(int i=1;i<9;i++)
						{
							frev2[i-1]=u(i);
						}
							get2();
							AD9910_FreWrite(fre2);
							AD9910_AmpWrite(9000);
							udelete(16); // 删除解析过的数据
					}
					else if( u(0) == 0x05)
					{
						if(u(1) == 0x66)
						{
							tjc_send_txt("t8", "txt", "... ");
							tjc_send_txt("t5", "txt", "  ");
							sweep();
						}
						if((u(1) == 0x99))
						{
							while(1)
							{
							HAL_GPIO_WritePin(Contr_GPIO_Port,Contr_Pin,GPIO_PIN_SET);
							HAL_Delay(2);
							while(1)
							{
								f=fft();
								f=fft();
								Set_SampleRate(TIM4,2000);
								HAL_TIM_Base_Start(&htim4);
								HAL_ADC_Start_DMA(&hadc1, (uint32_t*)AD_value, 10000);
	//							while(AD_flag == 0);
								dft();
	//							DA_flag=1;
								for(int i=0;i<10000;i++)
								{
									DA_set[i]=DA_value[i];
								}
									HAL_TIM_Base_Start(&htim6);
									HAL_DAC_Start_DMA(&hdac1,DAC_CHANNEL_2,(uint32_t*)DA_value,10000,DAC_ALIGN_12B_R);
								while(!(halflag&&comflag));
									HAL_ADC_Start_DMA(&hadc1, (uint32_t*)AD_value, 10000);
									HAL_TIM_Base_Start(&htim4);
									while(AD_flag == 0);
									dft();
									halflag=comflag=0;
								}
							}
						udelete(2);
					}
					else
					{
						// 不匹配删除1字节
						udelete(1);
						break;
					}
				}
			}

	}
  /* USER CODE END 3 */
}

void SystemClock_Config(void)
{
  RCC_OscInitTypeDef RCC_OscInitStruct = {0};
  RCC_ClkInitTypeDef RCC_ClkInitStruct = {0};

  /** Supply configuration update enable
  */
  HAL_PWREx_ConfigSupply(PWR_LDO_SUPPLY);

  /** Configure the main internal regulator output voltage
  */
  __HAL_PWR_VOLTAGESCALING_CONFIG(PWR_REGULATOR_VOLTAGE_SCALE0);

  while(!__HAL_PWR_GET_FLAG(PWR_FLAG_VOSRDY)) {}

  /** Initializes the RCC Oscillators according to the specified parameters
  * in the RCC_OscInitTypeDef structure.
  */
  RCC_OscInitStruct.OscillatorType = RCC_OSCILLATORTYPE_HSE;
  RCC_OscInitStruct.HSEState = RCC_HSE_ON;
  RCC_OscInitStruct.PLL.PLLState = RCC_PLL_ON;
  RCC_OscInitStruct.PLL.PLLSource = RCC_PLLSOURCE_HSE;
  RCC_OscInitStruct.PLL.PLLM = 5;
  RCC_OscInitStruct.PLL.PLLN = 192;
  RCC_OscInitStruct.PLL.PLLP = 2;
  RCC_OscInitStruct.PLL.PLLQ = 2;
  RCC_OscInitStruct.PLL.PLLR = 2;
  RCC_OscInitStruct.PLL.PLLRGE = RCC_PLL1VCIRANGE_2;
  RCC_OscInitStruct.PLL.PLLVCOSEL = RCC_PLL1VCOWIDE;
  RCC_OscInitStruct.PLL.PLLFRACN = 0;
  if (HAL_RCC_OscConfig(&RCC_OscInitStruct) != HAL_OK)
  {
    Error_Handler();
  }

  /** Initializes the CPU, AHB and APB buses clocks
  */
  RCC_ClkInitStruct.ClockType = RCC_CLOCKTYPE_HCLK|RCC_CLOCKTYPE_SYSCLK
                              |RCC_CLOCKTYPE_PCLK1|RCC_CLOCKTYPE_PCLK2
                              |RCC_CLOCKTYPE_D3PCLK1|RCC_CLOCKTYPE_D1PCLK1;
  RCC_ClkInitStruct.SYSCLKSource = RCC_SYSCLKSOURCE_PLLCLK;
  RCC_ClkInitStruct.SYSCLKDivider = RCC_SYSCLK_DIV1;
  RCC_ClkInitStruct.AHBCLKDivider = RCC_HCLK_DIV2;
  RCC_ClkInitStruct.APB3CLKDivider = RCC_APB3_DIV2;
  RCC_ClkInitStruct.APB1CLKDivider = RCC_APB1_DIV2;
  RCC_ClkInitStruct.APB2CLKDivider = RCC_APB2_DIV2;
  RCC_ClkInitStruct.APB4CLKDivider = RCC_APB4_DIV2;

  if (HAL_RCC_ClockConfig(&RCC_ClkInitStruct, FLASH_LATENCY_4) != HAL_OK)
  {
    Error_Handler();
  }
}

void PeriphCommonClock_Config(void)
{
  RCC_PeriphCLKInitTypeDef PeriphClkInitStruct = {0};

  /** Initializes the peripherals clock
  */
  PeriphClkInitStruct.PeriphClockSelection = RCC_PERIPHCLK_ADC;
  PeriphClkInitStruct.PLL2.PLL2M = 25;
  PeriphClkInitStruct.PLL2.PLL2N = 500;
  PeriphClkInitStruct.PLL2.PLL2P = 10;
  PeriphClkInitStruct.PLL2.PLL2Q = 2;
  PeriphClkInitStruct.PLL2.PLL2R = 2;
  PeriphClkInitStruct.PLL2.PLL2RGE = RCC_PLL2VCIRANGE_0;
  PeriphClkInitStruct.PLL2.PLL2VCOSEL = RCC_PLL2VCOWIDE;
  PeriphClkInitStruct.PLL2.PLL2FRACN = 0;
  PeriphClkInitStruct.AdcClockSelection = RCC_ADCCLKSOURCE_PLL2;
  if (HAL_RCCEx_PeriphCLKConfig(&PeriphClkInitStruct) != HAL_OK)
  {
    Error_Handler();
  }
}

/* USER CODE BEGIN 4 */
void HAL_ADC_ConvCpltCallback(ADC_HandleTypeDef *hadc)
{
	if(hadc->Instance == ADC1)
	{
		AD_flag=1;
		HAL_TIM_Base_Stop(&htim4);
		HAL_ADC_Stop_DMA(&hadc1);
	}
	if(hadc->Instance == ADC2)
	{
		AD_flag2=1;
		HAL_ADC_Stop_DMA(&hadc2);
	}
}
/* USER CODE END 4 */

 /* MPU Configuration */

void MPU_Config(void)
{
  MPU_Region_InitTypeDef MPU_InitStruct = {0};

  /* Disables the MPU */
  HAL_MPU_Disable();

  /** Initializes and configures the Region and the memory to be protected
  */
  MPU_InitStruct.Enable = MPU_REGION_ENABLE;
  MPU_InitStruct.Number = MPU_REGION_NUMBER0;
  MPU_InitStruct.BaseAddress = 0x0;
  MPU_InitStruct.Size = MPU_REGION_SIZE_4GB;
  MPU_InitStruct.SubRegionDisable = 0x87;
  MPU_InitStruct.TypeExtField = MPU_TEX_LEVEL0;
  MPU_InitStruct.AccessPermission = MPU_REGION_NO_ACCESS;
  MPU_InitStruct.DisableExec = MPU_INSTRUCTION_ACCESS_DISABLE;
  MPU_InitStruct.IsShareable = MPU_ACCESS_SHAREABLE;
  MPU_InitStruct.IsCacheable = MPU_ACCESS_NOT_CACHEABLE;
  MPU_InitStruct.IsBufferable = MPU_ACCESS_NOT_BUFFERABLE;

  HAL_MPU_ConfigRegion(&MPU_InitStruct);
  /* Enables the MPU */
  HAL_MPU_Enable(MPU_PRIVILEGED_DEFAULT);

}

void Error_Handler(void)
{
  __disable_irq();
  while (1)
  {
  }
}
